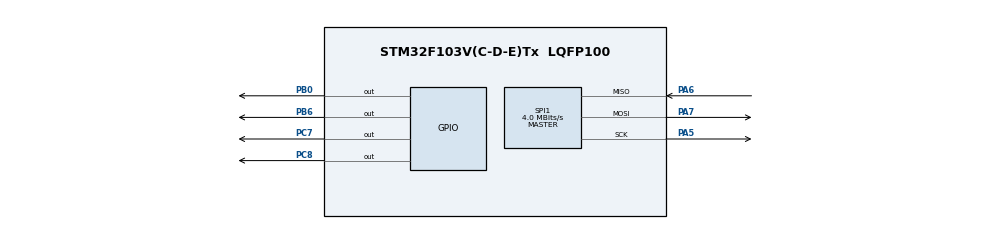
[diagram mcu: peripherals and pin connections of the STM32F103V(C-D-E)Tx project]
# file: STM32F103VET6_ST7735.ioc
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Mcu.Family=STM32F1
Mcu.Name=STM32F103V(C-D-E)Tx
Mcu.Package=LQFP100
NVIC.PriorityGroup=NVIC_PRIORITYGROUP_4
PA13.Mode=Serial_Wire
PA13.Signal=SYS_JTMS-SWDIO
PA14.Mode=Serial_Wire
PA14.Signal=SYS_JTCK-SWCLK
PA5.Mode=Full_Duplex_Master
PA5.Signal=SPI1_SCK
PA6.Mode=Full_Duplex_Master
PA6.Signal=SPI1_MISO
PA7.Mode=Full_Duplex_Master
PA7.Signal=SPI1_MOSI
PB0.PinState=GPIO_PIN_SET
PB0.Signal=GPIO_Output
PB6.Signal=GPIO_Output
PC7.Signal=GPIO_Output
PC8.Signal=GPIO_Output
ProjectManager.HeapSize=0x200
ProjectManager.StackSize=0x400
ProjectManager.TargetToolchain=STM32CubeIDE
RCC.APB1Freq_Value=8000000
RCC.APB2Freq_Value=8000000
SPI1.CalculateBaudRate=4.0 MBits/s
SPI1.Direction=SPI_DIRECTION_2LINES
SPI1.Mode=SPI_MODE_MASTER
SPI1.VirtualType=VM_MASTER
board=custom

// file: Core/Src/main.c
/* USER CODE BEGIN Header */
/**
  ******************************************************************************
  * @file           : main.c
  * @brief          : Main program body
  ******************************************************************************
  * @attention
  *
  * Copyright (c) 2024 STMicroelectronics.
  * All rights reserved.
  *
  * This software is licensed under terms that can be found in the LICENSE file
  * in the root directory of this software component.
  * If no LICENSE file comes with this software, it is provided AS-IS.
  *
  ******************************************************************************
  */
/* USER CODE END Header */
#include "main.h"
#include "spi.h"
#include "gpio.h"

/* USER CODE BEGIN Includes */
#include "ST7735.h"
#include "fonts.h"
#include "GFX_FUNCTIONS.h"
/* USER CODE END Includes */

/* USER CODE BEGIN PD */
const uint16_t _acBrandenburg_gate_cropped_high[] = {
		  0xA2, 0xA2, 0xA2, 0xA2, 0xA2, 0xA2, 0xA2, 0xA2, 0xA2, 0xA2, 0xA2, 0xA2, 0xA2, 0xA2, 0xA2, 0xA2, 0xA8, 0xA8, 0xA8, 0xA8, 0xA8, 0xA8, 0xA8, 0xA8, 0xA8, 0xA8, 0xA8, 0xA8, 0xA8, 0xA8, 0xA8, 0xA8, 0xA8, 0xA8, 0xA8, 0xA2, 0xA2, 0xA2, 0xA8, 0xA8, 0xA8, 0xA8,
		        0xA8, 0xA8, 0xA8, 0xA8, 0xA8, 0xA8, 0xA8, 0xA8, 0xA8, 0xA8, 0xA8, 0xA8, 0xA8, 0xCC, 0xCC, 0xCC, 0xCC, 0xCC, 0xCC, 0xCC, 0xCC, 0xCC, 0xCC, 0xCD, 0xCD, 0xCD, 0xCD, 0xCD, 0xCD, 0xCD, 0xCD, 0xCC, 0xCC, 0xCC, 0xCC, 0xCC, 0xCC, 0xCC, 0xCC, 0xCC, 0xCC,
		        0xCC, 0xCC, 0xCC, 0xCC, 0xCC, 0xCC, 0xCC, 0xCC, 0xCC, 0xCC, 0xCC, 0xCC, 0xCC, 0xCC, 0xA8, 0xA8, 0xA8, 0xA8, 0xA8, 0xA8, 0xA8, 0xA8, 0xA8, 0xA8, 0xA8, 0xA8, 0xA8, 0xA8, 0xA8, 0xA8, 0xA8, 0xA8, 0xA8, 0xA8, 0xA8, 0xA8, 0xA8,
		  0xA2, 0xA2, 0xA2, 0xA2, 0xA2, 0xA2, 0xA2, 0xA2, 0xA2, 0xA2, 0xA2, 0xA2, 0xA2, 0xA2, 0xA2, 0xA2, 0xA2, 0xA2, 0xA8, 0xA8, 0xA8, 0xA8, 0xA8, 0xA8, 0xA8, 0xA8, 0xA8, 0xA8, 0xA8, 0xA8, 0xA8, 0xA8, 0xA8, 0xA8, 0xA8, 0xA2, 0xA2, 0xA2, 0xA2, 0xA8, 0xA8, 0xA8,
		        0xA8, 0xA8, 0xA8, 0xA8, 0xA8, 0xA8, 0xA8, 0xA8, 0xA8, 0xA8, 0xA8, 0xA8, 0xA8, 0xA8, 0xA8, 0xCC, 0xCC, 0xCC, 0xCC, 0xCC, 0xCC, 0xCC, 0xCC, 0xCC, 0xCC, 0xCD, 0xCD, 0xCD, 0xCD, 0xCD, 0xCD, 0xCD, 0xCD, 0xCC, 0xCC, 0xCC, 0xCC, 0xCC, 0xCC, 0xCC, 0xCC,
		        0xCC, 0xCC, 0xCC, 0xCC, 0xCC, 0xCC, 0xCC, 0xCC, 0xCC, 0xCC, 0xCC, 0xCC, 0xCC, 0xA8, 0xA8, 0xA8, 0xA8, 0xA8, 0xA8, 0xA8, 0xA8, 0xA8, 0xA8, 0xA8, 0xA8, 0xA8, 0xA8, 0xA8, 0xA8, 0xA8, 0xA8, 0xA8, 0xA8, 0xA8, 0xA8, 0xA8, 0xA8,
		  0xA8, 0xA2, 0xA2, 0xA2, 0xA2, 0xA2, 0xA2, 0xA2, 0xA2, 0xA2, 0xA2, 0xA2, 0xA2, 0xA2, 0xA2, 0xA2, 0xA2, 0xA2, 0xA2, 0xA8, 0xA8, 0xA8, 0xA8, 0xA8, 0xA8, 0xA8, 0xA8, 0xA8, 0xA8, 0xA8, 0xA8, 0xA8, 0xA8, 0xA8, 0xA8, 0xA2, 0xA2, 0xA2, 0xA2, 0xA2, 0xA8, 0xA8,
		        0xA8, 0xA8, 0xA8, 0xA8, 0xA8, 0xA8, 0xA8, 0xA8, 0xA8, 0xA8, 0xA8, 0xA8, 0xCC, 0xCC, 0xCC, 0xCC, 0xCC, 0xCC, 0xCC, 0xCC, 0xCC, 0xCC, 0xCC, 0xCC, 0xCC, 0xCC, 0xCC, 0xCD, 0xCD, 0xCD, 0xCD, 0xCD, 0xCD, 0xCC, 0xCC, 0xCC, 0xCC, 0xCC, 0xCC, 0xCC, 0xCC,
		        0xCC, 0xCC, 0xCC, 0xCC, 0xCC, 0xCC, 0xCC, 0xCC, 0xCC, 0xCC, 0xCC, 0xCC, 0xCC, 0xA8, 0xA8, 0xA8, 0xA8, 0xA8, 0xA8, 0xA8, 0xA8, 0xA8, 0xA8, 0xA8, 0xA8, 0xA8, 0xA8, 0xA8, 0xA8, 0xA8, 0xA8, 0xA8, 0xA8, 0xA8, 0xA8, 0xA8, 0xA8,
		  0xA8, 0xA2, 0xA2, 0xA2, 0xA2, 0xA2, 0xA2, 0xA2, 0xA2, 0xA2, 0xA2, 0xA2, 0xA2, 0xA2, 0xA2, 0xA2, 0xA2, 0xA2, 0xA2, 0xA8, 0xA8, 0xA8, 0xA8, 0xA8, 0xA8, 0xA8, 0xA8, 0xA8, 0xA8, 0xA8, 0xA8, 0xA8, 0xA8, 0xA8, 0xA8, 0xA8, 0xA8, 0xA8, 0xA2, 0xA2, 0xA8, 0xA8,
		        0xA8, 0xA8, 0xA8, 0xA8, 0xA8, 0xA8, 0xA8, 0xA8, 0xA8, 0xA8, 0xA8, 0xCC, 0xCC, 0xCC, 0xCC, 0xA8, 0xA8, 0xCC, 0xCC, 0xCC, 0xCC, 0xCC, 0xCC, 0xCC, 0xCC, 0xCC, 0xCC, 0xCC, 0xCD, 0xCD, 0xCD, 0xCD, 0xCD, 0xCD, 0xCD, 0xCC, 0xCC, 0xCC, 0xCC, 0xCC, 0xCC,
		        0xCC, 0xCC, 0xCC, 0xCC, 0xCC, 0xCC, 0xCC, 0xCC, 0xCC, 0xCC, 0xCC, 0xCC, 0xCC, 0xA8, 0xA8, 0xA8, 0xA8, 0xA8, 0xA8, 0xA8, 0xA8, 0xA8, 0xA8, 0xA8, 0xA8, 0xA8, 0xA8, 0xA8, 0xA8, 0xA8, 0xA8, 0xA8, 0xA8, 0xA8, 0xA8, 0xA8, 0xA8,
		  0xA8, 0xA8, 0xA2, 0xA2, 0xA2, 0xA2, 0xA2, 0xA2, 0xA2, 0xA2, 0xA2, 0xA2, 0xA2, 0xA2, 0xA2, 0xA2, 0xA2, 0xA2, 0xA2, 0xA2, 0xA8, 0xA8, 0xA8, 0xA8, 0xA8, 0xA8, 0xA8, 0xA8, 0xA8, 0xA8, 0xA8, 0xA8, 0xA8, 0xA8, 0xA8, 0xA8, 0xA8, 0xA8, 0xA2, 0xA8, 0xA8, 0xA8,
		        0xA8, 0xA8, 0xA8, 0xA8, 0xA8, 0xA8, 0xA8, 0xA8, 0xA8, 0xA8, 0xCC, 0xCC, 0xCC, 0xCC, 0xCC, 0xCC, 0xCC, 0xCC, 0xCC, 0xCC, 0xCC, 0xCC, 0xCC, 0xCC, 0xCC, 0xCC, 0xCC, 0xCC, 0xCC, 0xCC, 0xCD, 0xCD, 0xCD, 0xCD, 0xCD, 0xCD, 0xCD, 0xCC, 0xCC, 0xCC, 0xCC,
		        0xCC, 0xCC, 0xCC, 0xCC, 0xCC, 0xCC, 0xCC, 0xCC, 0xCC, 0xCC, 0xCC, 0xCC, 0xCC, 0xA8, 0xA8, 0xA8, 0xA8, 0xA8, 0xA8, 0xA8, 0xA8, 0xA8, 0xA8, 0xA8, 0xA8, 0xA8, 0xA8, 0xA8, 0xA8, 0xA8, 0xA8, 0xA8, 0xA8, 0xA8, 0xA8, 0xA8, 0xA8,
		  0xA8, 0xA8, 0xA8, 0xA2, 0xA2, 0xA2, 0xA2, 0xA2, 0xA2, 0xA2, 0xA2, 0xA2, 0xA2, 0xA2, 0xA2, 0xA2, 0xA2, 0xA2, 0xA2, 0xA2, 0xA8, 0xA8, 0xA8, 0xA8, 0xA8, 0xA8, 0xA8, 0xA8, 0xA8, 0xA8, 0xA8, 0xA8, 0xA8, 0xA8, 0xA8, 0xA8, 0xA8, 0xA8, 0xA8, 0xA8, 0xA8, 0xA8,
		        0xA8, 0xA8, 0xA8, 0xA8, 0xA8, 0xA8, 0xA8, 0xA8, 0xA8, 0xA8, 0xCC, 0xCC, 0xCC, 0xCC, 0xCC, 0xCC, 0xCC, 0xCC, 0xCC, 0xCC, 0xCC, 0xCC, 0xCC, 0xCC, 0xCC, 0xCC, 0xCC, 0xCC, 0xCC, 0xCC, 0xCD, 0xCD, 0xCD, 0xCD, 0xCD, 0xCD, 0xCD, 0xCD, 0xCD, 0xCC, 0xCC,
		        0xCC, 0xCC, 0xCC, 0xCC, 0xCC, 0xCC, 0xCC, 0xCC, 0xCC, 0xCC, 0xCC, 0xCC, 0xA8, 0xA8, 0xA8, 0xA8, 0xA8, 0xA8, 0xA8, 0xA8, 0xA8, 0xA8, 0xA8, 0xA8, 0xA8, 0xA8, 0xA8, 0xA8, 0xA8, 0xA8, 0xA8, 0xA8, 0xA8, 0xA8, 0xA8, 0xA8, 0xA8,
		  0xA8, 0xA8, 0xA8, 0xA2, 0xA2, 0xA2, 0xA2, 0xA2, 0xA2, 0xA2, 0xA2, 0xA2, 0xA2, 0xA2, 0xA2, 0xA2, 0xA2, 0xA2, 0xA2, 0xA2, 0xA2, 0xA8, 0xA8, 0xA8, 0xA8, 0xA8, 0xA8, 0xA8, 0xA8, 0xA8, 0xA8, 0xA8, 0xA8, 0xA8, 0xA8, 0xA8, 0xA8, 0xA8, 0xA8, 0xA8, 0xA8, 0xA8,
		        0xA8, 0xA8, 0xA8, 0xA8, 0xA8, 0xA8, 0xA8, 0xA8, 0xA8, 0xA8, 0xCC, 0xCC, 0xCC, 0xCC, 0xCC, 0xCC, 0xCC, 0xCC, 0xCC, 0xCC, 0xCC, 0xCC, 0xCC, 0xCC, 0xCC, 0xCC, 0xCC, 0xCC, 0xCC, 0xCC, 0xCC, 0xCC, 0xCD, 0xCD, 0xCD, 0xCD, 0xCD, 0xCD, 0xCD, 0xCD, 0xCC,
		        0xCC, 0xCC, 0xCC, 0xCC, 0xCC, 0xCC, 0xCC, 0xCC, 0xCC, 0xCC, 0xCC, 0xCC, 0xA8, 0xA8, 0xA8, 0xA8, 0xA8, 0xA8, 0xA8, 0xA8, 0xA8, 0xA8, 0xA8, 0xA8, 0xA8, 0xA8, 0xA8, 0xA8, 0xA8, 0xA8, 0xA8, 0xA8, 0xA8, 0xA8, 0xA8, 0xA8, 0xA8,
		  0xA8, 0xA8, 0xA8, 0xA2, 0xA2, 0xA2, 0xA2, 0xA2, 0xA2, 0xA2, 0xA2, 0xA2, 0xA2, 0xA2, 0xA2, 0xA2, 0xA2, 0xA2, 0xA2, 0xA2, 0xA8, 0xA8, 0xA8, 0xA8, 0xA8, 0xA8, 0xA8, 0xA8, 0xA8, 0xA8, 0xA8, 0xA8, 0xA8, 0xA8, 0xA8, 0xA8, 0xA8, 0xA8, 0xA8, 0xA8, 0xA8, 0xA8,
		        0xA8, 0xA8, 0xA8, 0xA8, 0xA8, 0xA8, 0xA8, 0xA8, 0xA8, 0xCC, 0xCC, 0xCC, 0xCC, 0xCC, 0xCC, 0xCC, 0xCC, 0xCC, 0xCC, 0xCC, 0xCC, 0xCC, 0xCC, 0xCC, 0xCC, 0xCC, 0xCC, 0xCC, 0xCC, 0xCC, 0xCC, 0xCC, 0xCD, 0xCD, 0xCD, 0xCD, 0xCD, 0xCD, 0xCD, 0xCD, 0xCC,
		        0xCC, 0xCC, 0xCC, 0xCC, 0xCC, 0xCC, 0xCC, 0xCC, 0xCC, 0xCC, 0xCC, 0xCC, 0xA8, 0xA8, 0xA8, 0xA8, 0xA8, 0xA8, 0xA8, 0xA8, 0xA8, 0xA8, 0xA8, 0xA8, 0xA8, 0xA8, 0xA8, 0xA8, 0xA8, 0xA8, 0xA8, 0xA8, 0xA8, 0xA8, 0xA8, 0xA8, 0xA8,
		  0xA8, 0xA8, 0xA8, 0xA2, 0xA2, 0xA2, 0xA2, 0xA2, 0xA2, 0xA2, 0xA2, 0xA2, 0xA2, 0xA2, 0xA2, 0xA2, 0xA2, 0xA2, 0xA2, 0xA2, 0xA8, 0xA8, 0xA8, 0xA8, 0xA8, 0xA8, 0xA8, 0xA8, 0xA8, 0xA8, 0xA8, 0xA8, 0xA8, 0xA8, 0xA8, 0xA8, 0xA8, 0xA8, 0xA8, 0xA8, 0xA8, 0xA8,
		        0xA8, 0xA8, 0xA8, 0xA8, 0xA8, 0xA8, 0xA8, 0xA8, 0xA8, 0xA8, 0xA8, 0xCC, 0xCC, 0xCC, 0xCC, 0xCC, 0xCC, 0xCC, 0xCC, 0xCC, 0xCC, 0xCC, 0xCC, 0xCC, 0xCC, 0xCC, 0xCC, 0xCC, 0xCC, 0xCC, 0xCC, 0xCC, 0xCD, 0xCC, 0xCD, 0xCD, 0xCD, 0xCD, 0xCD, 0xCD, 0xCD,
		        0xCD, 0xCC, 0xCC, 0xCD, 0xCC, 0xCC, 0xCC, 0xCC, 0xCC, 0xCC, 0xCC, 0xA8, 0xA8, 0xA8, 0xA8, 0xA8, 0xA8, 0xA8, 0xA8, 0xA8, 0xA8, 0xA8, 0xA8, 0xA8, 0xA8, 0xA8, 0xA8, 0xA8, 0xA8, 0xA8, 0xA8, 0xA8, 0xA8, 0xA8, 0xA8, 0xA8, 0xA8,
		  0xA8, 0xA8, 0xA8, 0xA8, 0xA2, 0xA2, 0xA2, 0xA2, 0xA2, 0xA2, 0xA2, 0xA2, 0xA2, 0xA2, 0xA2, 0xA2, 0xA2, 0xA2, 0xA2, 0xA8, 0xA8, 0xA8, 0xA8, 0xA8, 0xA8, 0xA8, 0xA8, 0xA8, 0xA8, 0xA8, 0xA8, 0xA8, 0xA8, 0xA8, 0xA8, 0xA8, 0xA8, 0xA8, 0xA8, 0xA8, 0xA8, 0xA8,
		        0xA8, 0xA8, 0xA8, 0xA8, 0xA8, 0xA8, 0xA8, 0xA8, 0xA8, 0xA8, 0xA8, 0xCC, 0xCC, 0xCC, 0xCC, 0xCC, 0xCC, 0xCC, 0xCC, 0xCC, 0xCC, 0xCC, 0xCC, 0xCC, 0xCC, 0xCC, 0xCC, 0xCC, 0xCC, 0xCC, 0xCC, 0xCC, 0xCC, 0xCD, 0xCD, 0xCD, 0xCD, 0xCD, 0xCD, 0xCD, 0xCD,
		        0xCD, 0xCD, 0xCD, 0xCD, 0xCC, 0xCC, 0xCC, 0xCC, 0xCC, 0xCC, 0xCC, 0xA8, 0xA8, 0xA8, 0xA8, 0xA8, 0xA8, 0xA8, 0xA8, 0xA8, 0xA8, 0xA8, 0xA8, 0xA8, 0xA8, 0xA8, 0xA8, 0xA8, 0xA8, 0xA8, 0xA8, 0xA8, 0xA8, 0xA8, 0xA8, 0xA8, 0xA8,
		  0xA8, 0xA8, 0xA8, 0xA8, 0xA2, 0xA2, 0xA2, 0xA2, 0xA2, 0xA2, 0xA2, 0xA2, 0xA2, 0xA2, 0xA2, 0xA2, 0xA2, 0xA2, 0xA8, 0xA8, 0xA8, 0xA8, 0xA8, 0xA8, 0xA8, 0xA8, 0xA8, 0xA8, 0xA8, 0xA8, 0xA8, 0xA8, 0xA8, 0xA8, 0xA8, 0xA8, 0xA8, 0xA8, 0xA8, 0xA8, 0xA8, 0xA8,
		        0xA8, 0xA8, 0xA8, 0xA8, 0xA8, 0xA8, 0xA8, 0xA8, 0xCC, 0xCC, 0xCC, 0xCC, 0xCC, 0xCC, 0xCC, 0xCC, 0xCC, 0xCC, 0xCC, 0xCC, 0xCC, 0xCC, 0xCC, 0xCC, 0xCC, 0xCC, 0xCC, 0xCC, 0xCC, 0xCC, 0xCC, 0xCC, 0xCC, 0xCD, 0xCD, 0xCD, 0xCD, 0xCD, 0xCD, 0xCD, 0xCD,
		        0xCD, 0xCD, 0xCD, 0xCD, 0xCC, 0xCC, 0xCC, 0xCC, 0xCC, 0xCC, 0xA8, 0xA8, 0xA8, 0xA8, 0xA8, 0xA8, 0xA8, 0xA8, 0xA8, 0xA8, 0xA8, 0xA8, 0xA8, 0xA8, 0xA8, 0xA8, 0xA8, 0xA8, 0xA8, 0xA8, 0xA8, 0xA8, 0xA8, 0xA8, 0xA8, 0xA8, 0xA8,
		  0xA8, 0xA8, 0xA8, 0xA8, 0xA8, 0xA8, 0xA2, 0xA2, 0xA2, 0xA2, 0xA2, 0xA2, 0xA2, 0xA2, 0xA2, 0xA2, 0xA2, 0xA8, 0xA8, 0xA8, 0xA8, 0xA8, 0xA8, 0xA8, 0xA8, 0xA8, 0xA8, 0xA8, 0xA8, 0xA8, 0xA8, 0xA8, 0xA8, 0xA8, 0xA8, 0xA8, 0xA8, 0xA8, 0xA8, 0xA8, 0xA8, 0xA8,
		        0xA8, 0xA8, 0xA8, 0xA8, 0xA8, 0xA8, 0xA8, 0xA8, 0xCC, 0xCC, 0xCC, 0xCC, 0xCC, 0xCC, 0xCC, 0xCC, 0xCC, 0xCC, 0xCC, 0xCC, 0xCC, 0xCC, 0xCC, 0xCC, 0xCC, 0xCC, 0xCC, 0xCC, 0xCC, 0xCC, 0xCC, 0xCC, 0xCC, 0xCD, 0xCD, 0xCD, 0xCD, 0xCD, 0xCD, 0xCD, 0xCD,
		        0xCD, 0xCD, 0xCD, 0xCD, 0xCD, 0xCC, 0xCC, 0xCC, 0xCC, 0xCC, 0xA8, 0xA8, 0xA8, 0xA8, 0xA8, 0xCC, 0xA8, 0xA8, 0xA8, 0xA8, 0xA8, 0xA8, 0xA8, 0xA8, 0xA8, 0xA8, 0xA8, 0xA8, 0xA8, 0xA8, 0xA8, 0xA8, 0xA8, 0xA8, 0xA8, 0xA8, 0xA8,
		  0xA8, 0xA8, 0xA8, 0xA8, 0xA8, 0xA8, 0xA2, 0xA2, 0xA2, 0xA2, 0xA2, 0xA2, 0xA2, 0xA2, 0xA2, 0xA2, 0xA2, 0xA8, 0xA8, 0xA8, 0xA8, 0xA8, 0xA8, 0xA8, 0xA8, 0xA8, 0xA8, 0xA8, 0xA8, 0xA8, 0xA8, 0xA8, 0xA8, 0xA8, 0xA8, 0xA8, 0xA8, 0xA8, 0xA8, 0xA8, 0xA8, 0xA8,
		        0xA8, 0xA8, 0xA8, 0xA8, 0xA8, 0xA8, 0xA8, 0xA8, 0xCC, 0xCC, 0xCC, 0xCC, 0xCC, 0xCC, 0xCC, 0xCC, 0xCC, 0xCC, 0xCC, 0xCC, 0xCC, 0xCC, 0xCC, 0xCC, 0xCC, 0xCC, 0xCC, 0xCC, 0xCC, 0xCC, 0xCC, 0xCC, 0xCC, 0xCC, 0xCD, 0xCD, 0xCD, 0xCD, 0xCD, 0xCD, 0xCD,
		        0xCD, 0xCD, 0xCD, 0xCD, 0xCD, 0xCD, 0xCC, 0xCC, 0xCC, 0xCC, 0xA8, 0xA8, 0xA8, 0xA8, 0xA8, 0xCC, 0xA8, 0xA8, 0xA8, 0xA8, 0xA8, 0xA8, 0xA8, 0xA8, 0xA8, 0xA8, 0xA8, 0xA8, 0xA8, 0xA8, 0xA8, 0xA8, 0xA8, 0xA8, 0xA8, 0xA8, 0xA8,
		  0xA8, 0xA8, 0xA8, 0xA8, 0xA8, 0xA8, 0xA8, 0xA2, 0xA2, 0xA2, 0xA2, 0xA2, 0xA2, 0xA2, 0xA2, 0xA2, 0xA8, 0xA8, 0xA8, 0xA8, 0xA8, 0xA8, 0xA8, 0xA8, 0xA8, 0xA8, 0xA8, 0xA8, 0xA8, 0xA8, 0xA8, 0xA8, 0xA8, 0xA8, 0xA8, 0xA8, 0xA8, 0xA8, 0xA8, 0xA8, 0xA8, 0xA8,
		        0xA8, 0xA8, 0xA8, 0xA8, 0xA8, 0xA8, 0xA8, 0xA8, 0xA8, 0xCC, 0xCC, 0xCC, 0xCC, 0xCC, 0xCC, 0xCC, 0xCC, 0xCC, 0xCC, 0xCC, 0xCC, 0xCC, 0xCC, 0xCC, 0xCC, 0xCC, 0xCC, 0xCC, 0xCC, 0xCC, 0xCC, 0xCC, 0xCC, 0xCC, 0xCD, 0xCD, 0xCD, 0xCD, 0xCD, 0xCD, 0xCD,
		        0xCD, 0xCD, 0xCD, 0xCD, 0xCD, 0xCD, 0xCC, 0xCC, 0xCC, 0xCC, 0xA8, 0xA8, 0xA8, 0xA8, 0xA8, 0xCC, 0xCC, 0xA8, 0xA8, 0xA8, 0xA8, 0xA8, 0xA8, 0xA8, 0xA8, 0xA8, 0xA8, 0xA8, 0xA8, 0xA8, 0xA8, 0xA8, 0xA8, 0xA8, 0xA8, 0xA8, 0xA8,
		  0xA8, 0xA8, 0xA8, 0xA8, 0xA8, 0xA8, 0xA8, 0xA8, 0xA2, 0xA8, 0xA8, 0xA2, 0xA2, 0xA2, 0xA2, 0xA2, 0xA2, 0xA8, 0xA8, 0xA8, 0xA8, 0xA8, 0xA8, 0xA8, 0xA8, 0xA8, 0xA8, 0xA8, 0xA8, 0xA8, 0xA8, 0xA8, 0xA8, 0xA8, 0xA8, 0xA8, 0xA8, 0xA8, 0xA8, 0xA8, 0xA8, 0xA8,
		        0xA8, 0xA8, 0xA8, 0xA8, 0xA8, 0xA8, 0xA8, 0xA8, 0xA8, 0xCC, 0xCC, 0xCC, 0xCC, 0xCC, 0xCC, 0xCC, 0xCC, 0xCC, 0xCC, 0xCC, 0xCC, 0xCC, 0xCC, 0xCC, 0xCC, 0xCC, 0xCC, 0xCC, 0xCC, 0xCC, 0xCC, 0xCC, 0xCC, 0xCC, 0xCC, 0xCD, 0xCD, 0xCD, 0xCD, 0xCD, 0xCD,
		        0xCD, 0xCD, 0xCD, 0xCD, 0xCD, 0xCD, 0xCD, 0xCC, 0xCC, 0xA8, 0xA8, 0xCC, 0xA8, 0xA8, 0xA8, 0xA8, 0xA8, 0xA8, 0xA8, 0xA8, 0xA8, 0xA8, 0xA8, 0xA8, 0xA8, 0xA8, 0xA8, 0xA8, 0xA8, 0xA8, 0xA8, 0xA8, 0xA8, 0xA8, 0xA8, 0xA8, 0xA8,
		  0xA8, 0xA8, 0xA8, 0xA8, 0xA8, 0xA8, 0xA8, 0xA2, 0xA2, 0xA2, 0xA8, 0xA2, 0xA2, 0xA2, 0xA2, 0xA2, 0xA2, 0xA8, 0xA8, 0xA8, 0xA8, 0xA8, 0xA8, 0xA8, 0xA8, 0xA8, 0xA8, 0xA8, 0xA8, 0xA8, 0xA8, 0xA8, 0xA8, 0xA8, 0xA8, 0xA8, 0xA8, 0xA8, 0xA8, 0xA8, 0xA8, 0xA8,
		        0xA8, 0xA8, 0xA8, 0xA8, 0xA8, 0xA8, 0xA8, 0xA8, 0xA8, 0xCC, 0xCC, 0xCC, 0xCC, 0xCC, 0xCC, 0xCC, 0xCC, 0xCC, 0xCC, 0xCC, 0xCC, 0xCC, 0xCC, 0xCC, 0xCC, 0xCC, 0xCC, 0xCC, 0xCC, 0xCC, 0xCC, 0xCC, 0xCC, 0xCC, 0xCC, 0xCC, 0xCD, 0xCD, 0xCD, 0xCD, 0xCD,
		        0xCD, 0xCD, 0xCD, 0xCD, 0xCD, 0xCD, 0xCD, 0xCD, 0xCC, 0xCC, 0xCC, 0xCC, 0xA8, 0xA8, 0xA8, 0xA8, 0xA8, 0xA8, 0xA8, 0xA8, 0xA8, 0xA8, 0xA8, 0xA8, 0xA8, 0xA8, 0xA8, 0xA8, 0xA8, 0xA8, 0xA8, 0xA8, 0xA8, 0xA8, 0xA8, 0xA8, 0xA8,
		  0xA8, 0xA8, 0xA8, 0xA8, 0xA8, 0xA8, 0xA8, 0xA8, 0xA8, 0xA8, 0xA8, 0xA8, 0xA8, 0xA8, 0xA8, 0xA8, 0xA8, 0xA8, 0xA8, 0xA8, 0xA8, 0xA8, 0xA8, 0xA8, 0xA8, 0xA8, 0xA8, 0xA8, 0xA8, 0xA8, 0xA8, 0xA8, 0xA8, 0xA8, 0xA8, 0xA8, 0xA8, 0xA8, 0xA8, 0xA8, 0xA8, 0xA8,
		        0xA8, 0xA8, 0xA8, 0xA8, 0xA8, 0xA8, 0xA8, 0xA8, 0xA8, 0xA8, 0xCC, 0xCC, 0xCC, 0xCC, 0xCC, 0xCC, 0xCC, 0xCC, 0xCC, 0xCC, 0xCC, 0xCC, 0xCC, 0xCC, 0xCC, 0xCC, 0xCC, 0xCD, 0xCD, 0xCD, 0xCC, 0xCC, 0xCC, 0xCC, 0xCC, 0xCC, 0xCD, 0xCD, 0xCD, 0xCD, 0xCD,
		        0xCD, 0xCD, 0xCD, 0xCD, 0xCD, 0xCD, 0xCD, 0xCD, 0xCC, 0xCC, 0xA8, 0xA8, 0xA8, 0xA8, 0xA8, 0xA8, 0xA8, 0xA8, 0xA8, 0xA8, 0xA8, 0xA8, 0xA8, 0xA8, 0xA8, 0xA8, 0xA8, 0xA8, 0xA8, 0xA8, 0xA8, 0xA8, 0xA8, 0xA8, 0xA8, 0xA8, 0xA8,
		  0xA8, 0xA8, 0xA8, 0xA8, 0xA8, 0xA8, 0xA8, 0xA8, 0xA8, 0xA8, 0xA8, 0xA8, 0xA8, 0xA8, 0xA8, 0xA8, 0xA8, 0xA8, 0xA8, 0xA8, 0xA8, 0xA8, 0xA8, 0xA8, 0xA8, 0xA8, 0xA8, 0xA8, 0xA8, 0xA8, 0xA8, 0xA8, 0xA8, 0xA8, 0xA8, 0xA8, 0xA8, 0xA8, 0xA8, 0xA8, 0xA8, 0xA8,
		        0xA8, 0xA8, 0xA8, 0xA8, 0xA8, 0xA8, 0xA8, 0xA8, 0xA8, 0xA8, 0xA8, 0xCC, 0xCC, 0xCC, 0xCC, 0xCC, 0xCC, 0xCC, 0xCC, 0xCC, 0xCC, 0xCC, 0xCC, 0xCC, 0xCC, 0xCC, 0xCC, 0xCC, 0xCD, 0xCD, 0xCD, 0xCC, 0xCC, 0xCC, 0xCC, 0xCC, 0xCD, 0xCD, 0xCD, 0xCD, 0xCD,
		        0xCD, 0xCD, 0xCD, 0xCD, 0xCD, 0xCD, 0xCD, 0xCD, 0xCD, 0xCD, 0xCC, 0xA8, 0xA8, 0xA8, 0xA8, 0xA8, 0xA8, 0xA8, 0xA8, 0xA8, 0xA8, 0xA8, 0xA8, 0xA8, 0xA8, 0xA8, 0xA8, 0xA8, 0xA8, 0xA8, 0xA8, 0xA8, 0xA8, 0xA8, 0xA8, 0xA8, 0xA8,
		  0xCC, 0xA8, 0xA8, 0xA8, 0xA8, 0xA8, 0xA8, 0xA8, 0xA8, 0xA8, 0xA8, 0xA8, 0xA8, 0xA8, 0xA8, 0xA8, 0xA8, 0xA8, 0xA8, 0xA8, 0xA8, 0xA8, 0xA8, 0xA8, 0xA8, 0xA8, 0xA8, 0xA8, 0xA8, 0xA8, 0xA8, 0xA8, 0xA8, 0xA8, 0xA8, 0xA8, 0xA8, 0xA8, 0xA8, 0xA8, 0xA8, 0xA8,
		        0xA8, 0xA8, 0xA8, 0xA8, 0xA8, 0xA8, 0xA8, 0xA8, 0xA8, 0xA8, 0xA8, 0xCC, 0xCC, 0xCC, 0xCC, 0xCC, 0xCC, 0xCC, 0xCC, 0xCC, 0xCC, 0xCC, 0xCC, 0xCC, 0xCC, 0xCC, 0xCC, 0xCC, 0xCD, 0xCD, 0xCD, 0xCD, 0xCC, 0xCC, 0xCD, 0xCD, 0xCD, 0xCD, 0xCD, 0xCD, 0xCD,
		        0xCD, 0xCD, 0xCD, 0xCD, 0xCD, 0xCD, 0xCD, 0xCD, 0xCD, 0xCD, 0xCD, 0xCC, 0xA8, 0xA8, 0xA8, 0xCC, 0xCC, 0xA8, 0xA8, 0xA8, 0xA8, 0xA8, 0xA8, 0xA8, 0xA8, 0xA8, 0xA8, 0xA8, 0xA8, 0xA8, 0xA8, 0xA8, 0xA8, 0xA8, 0xA8, 0xA8, 0xA8,
		  0xA8, 0xA8, 0xA8, 0xA8, 0xA8, 0xA8, 0xA8, 0xA8, 0xA8, 0xA8, 0xA8, 0xA8, 0xA8, 0xA8, 0xA8, 0xA8, 0xA8, 0xA8, 0xA8, 0xA8, 0xA8, 0xA8, 0xA8, 0xA8, 0xA8, 0xA8, 0xA8, 0xA8, 0xA8, 0xA8, 0xA8, 0xA8, 0xA8, 0xA8, 0xA8, 0xA8, 0xA8, 0xA8, 0xA8, 0xA8, 0xA8, 0xA8,
		        0xA8, 0xA8, 0xA8, 0xA8, 0xA8, 0xA8, 0xA8, 0xA8, 0xA8, 0xA8, 0xA8, 0xCC, 0xCC, 0xCC, 0xCC, 0xCC, 0xCC, 0xCC, 0xCC, 0xCC, 0xCC, 0xCC, 0xCC, 0xCC, 0xCC, 0xCC, 0xCC, 0xCC, 0xCD, 0xCD, 0xCD, 0xCD, 0xCD, 0xCD, 0xCD, 0xCD, 0xCD, 0xCD, 0xCD, 0xCD, 0xCD,
		        0xCD, 0xCD, 0xCD, 0xCD, 0xCD, 0xCD, 0xCD, 0xCD, 0xCC, 0xCC, 0xCC, 0xCC, 0xCC, 0xA8, 0xA8, 0xCC, 0xCC, 0xCC, 0xA8, 0xA8, 0xA8, 0xA8, 0xA8, 0xA8, 0xA8, 0xA8, 0xA8, 0xA8, 0xA8, 0xA8, 0xA8, 0xA8, 0xA8, 0xA8, 0xA8, 0xA8, 0xA8,
		  0xCC, 0xA8, 0xA8, 0xA8, 0xA8, 0xA8, 0xA8, 0xA8, 0xA8, 0xA8, 0xA8, 0xA8, 0xA8, 0xA8, 0xA8, 0xA8, 0xA8, 0xA8, 0xA8, 0xA8, 0xA8, 0xA8, 0xA8, 0xA8, 0xA8, 0xA8, 0xA8, 0xA8, 0xA8, 0xA8, 0xA8, 0xA8, 0xA8, 0xA8, 0xA8, 0xA8, 0xA8, 0xA8, 0xA8, 0xA8, 0xA8, 0xA8,
		        0xA8, 0xA8, 0xA8, 0xA8, 0xA8, 0xA8, 0xA8, 0xA8, 0xA8, 0xA8, 0xA8, 0xA8, 0xCC, 0xCC, 0xCC, 0xCC, 0xCC, 0xCC, 0xCC, 0xCC, 0xCC, 0xCC, 0xCC, 0xCC, 0xCC, 0xCC, 0xCC, 0xCD, 0xCD, 0xCD, 0xCD, 0xCD, 0xCD, 0xCD, 0xCD, 0xCD, 0xCD, 0xCD, 0xCD, 0xCD, 0xCD,
		        0xCD, 0xCC, 0xCC, 0xCC, 0xCC, 0xCC, 0xCD, 0xCC, 0xCD, 0xCC, 0xCC, 0xCD, 0xCC, 0xCC, 0xCC, 0xCC, 0xCC, 0xCC, 0xA8, 0xA8, 0xA8, 0xA8, 0xA8, 0xA8, 0xA8, 0xA8, 0xA8, 0xA8, 0xA8, 0xA8, 0xA8, 0xA8, 0xA8, 0xA8, 0xA8, 0xA8, 0xA8,
		  0xCC, 0xA8, 0xA8, 0xA8, 0xA8, 0xA8, 0xA8, 0xA8, 0xA8, 0xA8, 0xA8, 0xA8, 0xA8, 0xA8, 0xA8, 0xA8, 0xA8, 0xA8, 0xA8, 0xA8, 0xA8, 0xA8, 0xA8, 0xA8, 0xA8, 0xA8, 0xA8, 0xA8, 0xA8, 0xA8, 0xA8, 0xA8, 0xA8, 0xA8, 0xA8, 0xA8, 0xA8, 0xA8, 0xA8, 0xA8, 0xA8, 0xA8,
		        0xA8, 0xA8, 0xA8, 0xA8, 0xA8, 0xA8, 0xA8, 0xA8, 0xA8, 0xA8, 0xA8, 0xA8, 0xA8, 0xA8, 0xA8, 0xCC, 0xCC, 0xCC, 0xCC, 0xCC, 0xCC, 0xCC, 0xCC, 0xCC, 0xCC, 0xCC, 0xCC, 0xCD, 0xCD, 0xCD, 0xCD, 0xCD, 0xCD, 0xCD, 0xCD, 0xCD, 0xCD, 0xCD, 0xCD, 0xCD, 0xCD,
		        0xCC, 0xCC, 0xCC, 0xCC, 0xCC, 0xCC, 0xCD, 0xCC, 0xCD, 0xCD, 0xCD, 0xCD, 0xCC, 0xCC, 0xCC, 0xCC, 0xCC, 0xCC, 0xA8, 0xA8, 0xA8, 0xCC, 0xA8, 0xA8, 0xA8, 0xA8, 0xA8, 0xA8, 0xA8, 0xA8, 0xA8, 0xA8, 0xA8, 0xA8, 0xA8, 0xA8, 0xA8,
		  0xCC, 0xA8, 0xA8, 0xA8, 0xA8, 0xA8, 0xA8, 0xA8, 0xA8, 0xA8, 0xA8, 0xA8, 0xA8, 0xA8, 0xA8, 0xA8, 0xA8, 0xA8, 0xA8, 0xA8, 0xA8, 0xA8, 0xA8, 0xA8, 0xA8, 0xA8, 0xA8, 0xA8, 0xA8, 0xA8, 0xA8, 0xA8, 0xA8, 0xA8, 0xA8, 0xA8, 0xA8, 0xA8, 0xA8, 0xA8, 0xA8, 0xA8,
		        0xA8, 0xA8, 0xA8, 0xA8, 0xA8, 0xA8, 0xA8, 0xA8, 0xA8, 0xCC, 0xCC, 0xCC, 0xA8, 0xA8, 0xCC, 0xCC, 0xCC, 0xCC, 0xCC, 0xCC, 0xCC, 0xCC, 0xCC, 0xCC, 0xCC, 0xCC, 0xCD, 0xCC, 0xCD, 0xCD, 0xCD, 0xCD, 0xCD, 0xCD, 0xCD, 0xCD, 0xCD, 0xCD, 0xCD, 0xCD, 0xCD,
		        0xCC, 0xCC, 0xCC, 0xCC, 0xCC, 0xCC, 0xCC, 0xCC, 0xCC, 0xCC, 0xCD, 0xCC, 0xCC, 0xCC, 0xCC, 0xCC, 0xCC, 0xCC, 0xCC, 0xCC, 0xA8, 0xA8, 0xA8, 0xA8, 0xA8, 0xA8, 0xA8, 0xA8, 0xA8, 0xA8, 0xA8, 0xA8, 0xA8, 0xA8, 0xA8, 0xA8, 0xA8,
		  0xCC, 0xA8, 0xA8, 0xA8, 0xA8, 0xA8, 0xA8, 0xA8, 0xA8, 0xA8, 0xA8, 0xA8, 0xA8, 0xA8, 0xA8, 0xA8, 0xA8, 0xA8, 0xA8, 0xA8, 0xA8, 0xA8, 0xA8, 0xA8, 0xA8, 0xA8, 0xA8, 0xA8, 0xA8, 0xA8, 0xA8, 0xA8, 0xA8, 0xA8, 0xA8, 0xA8, 0xA8, 0xA8, 0xA8, 0xA8, 0xA8, 0xA8,
		        0xA8, 0xA8, 0xA8, 0xA8, 0xA8, 0xA8, 0xCC, 0xA8, 0xCC, 0xCC, 0xCC, 0xCC, 0xA8, 0xA8, 0xCC, 0xA8, 0xA8, 0xA8, 0xA8, 0xCC, 0xA8, 0xA8, 0xA8, 0xCC, 0xCC, 0xCD, 0xCC, 0xCD, 0xCD, 0xCD, 0xCD, 0xCD, 0xCD, 0xCD, 0xCD, 0xCD, 0xCD, 0xCD, 0xCD, 0xCD, 0xCD,
		        0xCC, 0xCC, 0xCC, 0xCC, 0xCC, 0xCC, 0xCC, 0xCC, 0xCC, 0xCD, 0xCD, 0xCD, 0xCD, 0xCC, 0xCC, 0xCC, 0xCC, 0xA8, 0xCC, 0xCC, 0xA8, 0xA8, 0xA8, 0xA8, 0xCC, 0xCC, 0xA8, 0xA8, 0xA8, 0xA8, 0xA8, 0xA8, 0xA8, 0xA8, 0xA8, 0xA8, 0xCC,
		  0xCC, 0xA8, 0xA8, 0xA8, 0xA8, 0xA8, 0xA8, 0xA8, 0xA8, 0xA8, 0xA8, 0xA8, 0xA8, 0xA8, 0xA8, 0xA8, 0xA8, 0xA8, 0xA8, 0xA8, 0xA8, 0xA8, 0xA8, 0xA8, 0xA8, 0xA8, 0xA8, 0xA8, 0xA8, 0xA8, 0xA8, 0xA8, 0xA8, 0xA8, 0xA8, 0xA8, 0xA8, 0xA8, 0xA8, 0xA8, 0xA8, 0xA8,
		        0xA8, 0xA8, 0xA8, 0xA8, 0xA8, 0xA8, 0xA8, 0xA8, 0xCC, 0xCC, 0xCC, 0xCC, 0xA8, 0xA8, 0xCC, 0xA2, 0x55, 0xA8, 0xA8, 0xA8, 0xA2, 0x2B, 0xA8, 0xCC, 0xCC, 0xCC, 0xCD, 0xCD, 0xCD, 0xCD, 0xCD, 0xCD, 0xCD, 0xCD, 0xCD, 0xCD, 0xCD, 0xCD, 0xCD, 0xCD, 0xCD,
		        0xCC, 0xCC, 0xCC, 0xCC, 0xCC, 0xCC, 0xCC, 0xCC, 0xCC, 0xCC, 0xCD, 0xCD, 0xCD, 0xCD, 0xCC, 0xCC, 0xCC, 0xCC, 0xCC, 0xA8, 0xA8, 0xCC, 0xA8, 0xA8, 0xCC, 0xCC, 0xCC, 0xA8, 0xA8, 0xA8, 0xA8, 0xCC, 0xCC, 0xA8, 0xA8, 0xA8, 0xCC,
		  0xCC, 0xA8, 0xA8, 0xA8, 0xA8, 0xA8, 0xA8, 0xA8, 0xA8, 0xA8, 0xA8, 0xA8, 0xA8, 0xA8, 0xA8, 0xA8, 0xA8, 0xA8, 0xA8, 0xA8, 0xA8, 0xA8, 0xA8, 0xA8, 0xA8, 0xA8, 0xA8, 0xA8, 0xA8, 0xA8, 0xA8, 0xA8, 0xA8, 0xA8, 0xA8, 0xA8, 0xA8, 0xA8, 0xA8, 0xA8, 0xA8, 0xA8,
		        0xA8, 0xA8, 0xA8, 0xA8, 0xA8, 0xA8, 0xCC, 0xCC, 0xCC, 0xCC, 0xCC, 0xCC, 0xCC, 0xA8, 0xCC, 0xA8, 0x2B, 0x2B, 0xA2, 0xA2, 0x00, 0x4F, 0xCC, 0xCC, 0xCC, 0xCC, 0xCD, 0xCD, 0xCD, 0xCD, 0xCD, 0xCD, 0xCD, 0xCD, 0xCD, 0xCD, 0xCD, 0xCD, 0xCD, 0xCD, 0xCC,
		        0xCC, 0xCC, 0xCC, 0xCC, 0xCC, 0xCC, 0xCC, 0xCC, 0xCC, 0xCC, 0xCC, 0xCC, 0xCC, 0xCD, 0xCD, 0xCC, 0xCC, 0xCC, 0xCC, 0xA8, 0xA8, 0xCC, 0xCC, 0xA8, 0xCC, 0xCC, 0xCC, 0xCC, 0xCC, 0xCC, 0xCC, 0xCC, 0xCC, 0xA8, 0xA8, 0xA8, 0xCC,
		  0xCC, 0xA8, 0xA8, 0xA8, 0xA8, 0xA8, 0xA8, 0xA8, 0xA8, 0xA8, 0xA8, 0xA8, 0xA8, 0xA8, 0xA8, 0xA8, 0xA8, 0xA8, 0xA8, 0xA8, 0xA8, 0xA8, 0xA8, 0xA8, 0xA8, 0xA8, 0xA8, 0xA8, 0xA8, 0xA8, 0xA8, 0xA8, 0xA8, 0xA8, 0xA8, 0xA8, 0xA8, 0xA8, 0xA8, 0xA8, 0xA8, 0xA8,
		        0xA8, 0xA8, 0xA8, 0xA8, 0xA8, 0xCC, 0xCC, 0xCC, 0xCC, 0xCC, 0xCC, 0xCC, 0xCC, 0xCC, 0xCC, 0xCC, 0x56, 0x2B, 0x55, 0x2B, 0x2A, 0xA2, 0xCC, 0xCC, 0xCC, 0xCC, 0xCC, 0xCD, 0xCD, 0xCD, 0xCD, 0xCD, 0xCD, 0xCD, 0xCD, 0xCD, 0xCD, 0xCD, 0xCD, 0xCD, 0xCC,
		        0xCC, 0xCC, 0xCC, 0xCC, 0xCC, 0xCC, 0xCC, 0xCC, 0xCC, 0xCC, 0xCC, 0xCC, 0xCD, 0xCD, 0xCD, 0xCC, 0xCC, 0xCC, 0xCC, 0xCC, 0xCC, 0xCC, 0xCC, 0xCC, 0xCC, 0xCC, 0xCC, 0xCC, 0xCC, 0xCC, 0xCC, 0xCC, 0xCC, 0xCC, 0xCC, 0xCC, 0xCC,
		  0xCC, 0xCC, 0xCC, 0xA8, 0xA8, 0xA8, 0xA8, 0xA8, 0xA8, 0xA8, 0xA8, 0xA8, 0xA8, 0xA8, 0xA8, 0xA8, 0xA8, 0xA8, 0xA8, 0xA8, 0xA8, 0xA8, 0xA8, 0xA8, 0xA8, 0xA8, 0xA8, 0xA8, 0xA8, 0xA8, 0xA8, 0xA8, 0xA8, 0xA8, 0xA8, 0xA8, 0xA8, 0xA8, 0xA8, 0xA8, 0xA8, 0xA8,
		        0xA8, 0xA8, 0xA8, 0xA8, 0xA8, 0xCC, 0xCC, 0xCC, 0xCC, 0xCC, 0xCC, 0xCC, 0xCC, 0xCC, 0xCC, 0xCC, 0xCC, 0x56, 0x2B, 0x2B, 0x55, 0xA8, 0xA8, 0xCC, 0xCC, 0xCC, 0xCC, 0xCD, 0xCD, 0xCD, 0xCD, 0xCD, 0xCD, 0xCD, 0xCD, 0xCD, 0xCD, 0xCD, 0xCD, 0xCD, 0xCC,
		        0xCC, 0xCC, 0xCC, 0xCC, 0xCC, 0xCC, 0xCC, 0xCC, 0xCC, 0xCC, 0xCC, 0xCC, 0xCC, 0xCC, 0xCC, 0xCC, 0xCC, 0xCC, 0xCC, 0xCC, 0xCC, 0xCC, 0xCC, 0xCC, 0xCC, 0xCC, 0xCC, 0xCC, 0xCC, 0xCC, 0xCC, 0xCC, 0xCC, 0xCC, 0xCC, 0xCC, 0xCC,
		  0xCC, 0xCC, 0xA8, 0xCC, 0xA8, 0xA8, 0xA8, 0xA8, 0xA8, 0xA8, 0xA8, 0xA8, 0xA8, 0xA8, 0xA8, 0xA8, 0xA8, 0xA8, 0xA8, 0xA8, 0xA8, 0xA8, 0xA8, 0xA8, 0xA8, 0xA8, 0xA8, 0xA8, 0xA8, 0xA8, 0xA8, 0xA8, 0xA8, 0xA8, 0xA8, 0xA8, 0xA8, 0xA8, 0xA8, 0xA8, 0xA8, 0xA8,
		        0xA8, 0xA8, 0xA8, 0xA8, 0xCC, 0xCC, 0xCC, 0xCC, 0xCC, 0xCC, 0xCC, 0xCC, 0xCC, 0xCC, 0xCC, 0xCC, 0xCC, 0xA8, 0x56, 0x2B, 0xA8, 0xCC, 0xA8, 0xCC, 0xCC, 0xCC, 0xCC, 0xCD, 0xCD, 0xCD, 0xCD, 0xCD, 0xCD, 0xCD, 0xCD, 0xCD, 0xCD, 0xCD, 0xCD, 0xCC, 0xCC,
		        0xCC, 0xCC, 0xCC, 0xCC, 0xCC, 0xCC, 0xCC, 0xCC, 0xCC, 0xCC, 0xCC, 0xCC, 0xCC, 0xCC, 0xCC, 0xCC, 0xCC, 0xCC, 0xCC, 0xCC, 0xCC, 0xCC, 0xCC, 0xCC, 0xA8, 0xCC, 0xCC, 0xCC, 0xCC, 0xCC, 0xCC, 0xCC, 0xCC, 0xCC, 0xCC, 0xCC, 0xCC,
		  0xCC, 0xCC, 0xCC, 0xCC, 0xCC, 0xA8, 0xA8, 0xA8, 0xA8, 0xA8, 0xA8, 0xA8, 0xA8, 0xA8, 0xA8, 0xA8, 0xA8, 0xA8, 0xA8, 0xA8, 0xA8, 0xA8, 0xA8, 0xA8, 0xA8, 0xA8, 0xA8, 0xA8, 0xA8, 0xA8, 0xA8, 0xA8, 0xA8, 0xA8, 0xA8, 0xA8, 0xA8, 0xA8, 0xA8, 0xA8, 0xA8, 0xA8,
		        0xA8, 0xA8, 0xA8, 0xCC, 0xCC, 0xCC, 0xCC, 0xCC, 0xCC, 0xCC, 0xCC, 0xCC, 0xCC, 0xCC, 0xCC, 0xCC, 0xCC, 0xA8, 0x55, 0x2B, 0x56, 0xA8, 0xA8, 0xCC, 0xCC, 0xCC, 0xCC, 0xCC, 0xCD, 0xCD, 0xCD, 0xCD, 0xCD, 0xCD, 0xCD, 0xCD, 0xCD, 0xCD, 0xCD, 0xCC, 0xCC,
		        0xCC, 0xCC, 0xCC, 0xCC, 0xCC, 0xCC, 0xCC, 0xCC, 0xCC, 0xCC, 0xCC, 0xCC, 0xCC, 0xCC, 0xCC, 0xCC, 0xCC, 0xCC, 0xCC, 0xCC, 0xCC, 0xCC, 0xCC, 0xCC, 0xCC, 0xCC, 0xCC, 0xCC, 0xCC, 0xCC, 0xCC, 0xCC, 0xCC, 0xCC, 0xCC, 0xCC, 0xCC,
		  0xCC, 0xCC, 0xCC, 0xCC, 0xCC, 0xA8, 0xA8, 0xA8, 0xA8, 0xA8, 0xA8, 0xA8, 0xA8, 0xA8, 0xA8, 0xA8, 0xA8, 0xA8, 0xA8, 0xCC, 0xCC, 0xCC, 0xA8, 0xA8, 0xA8, 0xA8, 0xA8, 0xA8, 0xA8, 0xA8, 0xA8, 0xA8, 0xA8, 0xA8, 0xA8, 0xA8, 0xA8, 0xA8, 0xA8, 0xA8, 0xA8, 0xA8,
		        0xA8, 0xA8, 0xA8, 0xCC, 0xCC, 0xCC, 0xCC, 0xCC, 0xCC, 0xCC, 0xCC, 0xCC, 0xCC, 0xCC, 0xCC, 0xCC, 0xCC, 0x55, 0x56, 0x56, 0x55, 0xA8, 0xCC, 0xCC, 0xCC, 0xCC, 0xCC, 0xCC, 0xCD, 0xCD, 0xCD, 0xCD, 0xCD, 0xCD, 0xCD, 0xCD, 0xCD, 0xCD, 0xCD, 0xCC, 0xCC,
		        0xCC, 0xCC, 0xCC, 0xCC, 0xCC, 0xCC, 0xCC, 0xCC, 0xCC, 0xCC, 0xCC, 0xCC, 0xCC, 0xCC, 0xCC, 0xCC, 0xCC, 0xCC, 0xCC, 0xCC, 0xCC, 0xCC, 0xCC, 0xCC, 0xCC, 0xCC, 0xCC, 0xCC, 0xCC, 0xCC, 0xCC, 0xCC, 0xCC, 0xCC, 0xCC, 0xCC, 0xCC,
		  0xCC, 0xCC, 0xCC, 0xCC, 0xCC, 0xA8, 0xA8, 0xA8, 0xA8, 0xA8, 0xA8, 0xA8, 0xA8, 0xA8, 0xA8, 0xA8, 0xA8, 0xA8, 0xA8, 0xA8, 0xCC, 0xCC, 0xA8, 0xA8, 0xA8, 0xA8, 0xA8, 0xA8, 0xA8, 0xA8, 0xA8, 0xA8, 0xA8, 0xA8, 0xA8, 0xA8, 0xA8, 0xA8, 0xA8, 0xA8, 0xA8, 0xA8,
		        0xA8, 0xA8, 0xA8, 0xA8, 0xCC, 0xCC, 0xCC, 0xCC, 0xCC, 0xCC, 0xCC, 0xCC, 0xCC, 0xCC, 0xCC, 0xCC, 0xA8, 0x56, 0xA2, 0x56, 0x4F, 0xA8, 0xA8, 0xCC, 0xCC, 0xCC, 0xCC, 0xCC, 0xCC, 0xCD, 0xCD, 0xCD, 0xCD, 0xCD, 0xCD, 0xCD, 0xCD, 0xCD, 0xCD, 0xCC, 0xCC,
		        0xCC, 0xCC, 0xCC, 0xCC, 0xCC, 0xCC, 0xCC, 0xCC, 0xCC, 0xCC, 0xCC, 0xCC, 0xCC, 0xCC, 0xCC, 0xCC, 0xCC, 0xCC, 0xCC, 0xCC, 0xCC, 0xCD, 0xCC, 0xCC, 0xCC, 0xCC, 0xCC, 0xCC, 0xCC, 0xCC, 0xCC, 0xCC, 0xCC, 0xCC, 0xCC, 0xCC, 0xCC,
		  0xCC, 0xCC, 0xCC, 0xCC, 0xCC, 0xCC, 0xA8, 0xA8, 0xA8, 0xA8, 0xA8, 0xA8, 0xA8, 0xA8, 0xA8, 0xA8, 0xA8, 0xA8, 0xA8, 0xCC, 0xCC, 0xCC, 0xCC, 0xA8, 0xA8, 0xA8, 0xA8, 0xA8, 0xA8, 0xA8, 0xA8, 0xA8, 0xA8, 0xA8, 0xA8, 0xA8, 0xA8, 0xA8, 0xA8, 0xA8, 0xA8, 0xA8,
		        0xA8, 0xA8, 0xA8, 0xA8, 0xCC, 0xCC, 0xCC, 0xCC, 0xCC, 0xCC, 0xCC, 0xCC, 0xCC, 0xCC, 0xCC, 0xCC, 0xCC, 0xA8, 0x55, 0x55, 0xA2, 0xCC, 0xCC, 0xCC, 0xCC, 0xCC, 0xCC, 0xCC, 0xCD, 0xCD, 0xCD, 0xCD, 0xCD, 0xCD, 0xCD, 0xCD, 0xCD, 0xCD, 0xCD, 0xCC, 0xCC,
		        0xCC, 0xCC, 0xCC, 0xCC, 0xCC, 0xCC, 0xCC, 0xCC, 0xCC, 0xCC, 0xCC, 0xCC, 0xCC, 0xCC, 0xCC, 0xCC, 0xCC, 0xCC, 0xCC, 0xCC, 0xCC, 0xCC, 0xCD, 0xCC, 0xCC, 0xCC, 0xCD, 0xCC, 0xCC, 0xCC, 0xCC, 0xCC, 0xCC, 0xCC, 0xCC, 0xCC, 0xCC,
		  0xCC, 0xCC, 0xCC, 0xCC, 0xCC, 0xCC, 0xCC, 0xA8, 0xA8, 0xA8, 0xA8, 0xA8, 0xA8, 0xA8, 0xA8, 0xA8, 0xCC, 0xCC, 0xCC, 0xCC, 0xCC, 0xCC, 0xA8, 0xA8, 0xA8, 0xA8, 0xA8, 0xA8, 0xA8, 0xA8, 0xA8, 0xA8, 0xA8, 0xA8, 0xA8, 0xA8, 0xA8, 0xA8, 0xA8, 0xA8, 0xA8, 0xA8,
		        0xA8, 0xA8, 0xCC, 0xCC, 0xCC, 0xCC, 0xCC, 0xCC, 0xCC, 0xCC, 0xCC, 0xCC, 0xCC, 0xCC, 0xCC, 0xCC, 0xCC, 0xCC, 0xA8, 0xA2, 0xA8, 0xCC, 0xA8, 0xCC, 0xCC, 0xCC, 0xCC, 0xCC, 0xCC, 0xCD, 0xCD, 0xCD, 0xCD, 0xCD, 0xCD, 0xCD, 0xCD, 0xCD, 0xCC, 0xCC, 0xCC,
		        0xCC, 0xCC, 0xCC, 0xCC, 0xCC, 0xCC, 0xCC, 0xCC, 0xCC, 0xCC, 0xCC, 0xCC, 0xCC, 0xCC, 0xCC, 0xCC, 0xCC, 0xCC, 0xCC, 0xCC, 0xCC, 0xCC, 0xCC, 0xCC, 0xCD, 0xCD, 0xCD, 0xCD, 0xCC, 0xCC, 0xCC, 0xCC, 0xCC, 0xCC, 0xCC, 0xCC, 0xCC,
		  0xCC, 0xCC, 0xCC, 0xCC, 0xCC, 0xCC, 0xCC, 0xCC, 0xCC, 0xCC, 0xCC, 0xA8, 0xA8, 0xA8, 0xA8, 0xA8, 0xA8, 0xCC, 0xCC, 0xCC, 0xCC, 0xCC, 0xA8, 0xCC, 0xA8, 0xA8, 0xA8, 0xA8, 0xA8, 0xA8, 0xA8, 0xA8, 0xA8, 0xA8, 0xA8, 0xA8, 0xA8, 0xA8, 0xA8, 0xA8, 0xA8, 0xA8,
		        0xA8, 0xA8, 0xCC, 0xCC, 0xCC, 0xCC, 0xCC, 0xCC, 0xCC, 0xCC, 0xCC, 0xCC, 0xCC, 0xCC, 0xCC, 0xCC, 0xCC, 0xCC, 0xCC, 0xA2, 0xCC, 0xA8, 0xCC, 0xCC, 0xA8, 0xA8, 0xA8, 0xCC, 0xCD, 0xCD, 0xCD, 0xCD, 0xCD, 0xCD, 0xCD, 0xCD, 0xCD, 0xCD, 0xCC, 0xCC, 0xCC,
		        0xCC, 0xCC, 0xCC, 0xCC, 0xCC, 0xCC, 0xCC, 0xCC, 0xCC, 0xCC, 0xCC, 0xCC, 0xCC, 0xCC, 0xCC, 0xCC, 0xCC, 0xCC, 0xCC, 0xCC, 0xCC, 0xCC, 0xCC, 0xCC, 0xCD, 0xCD, 0xCD, 0xCD, 0xCD, 0xCC, 0xCC, 0xCC, 0xCC, 0xCC, 0xCC, 0xCC, 0xCC,
		  0xCC, 0xCC, 0xCC, 0xCC, 0xCC, 0xCC, 0xCC, 0xCC, 0xCC, 0xA8, 0xA8, 0xA8, 0xA8, 0xA8, 0xA8, 0xCC, 0xCC, 0xCC, 0xCC, 0xCC, 0xCC, 0xCC, 0xA8, 0xA8, 0xA8, 0xA8, 0xA8, 0xA8, 0xA8, 0xA8, 0xA8, 0xA8, 0xA8, 0xA8, 0xA8, 0xA8, 0xA8, 0xA8, 0xA8, 0xA8, 0xA8, 0xCC,
		        0xCC, 0xCC, 0xCC, 0xCC, 0xA8, 0xA8, 0xCC, 0xCC, 0xCC, 0xCC, 0xCC, 0xCC, 0xCC, 0xCC, 0xA8, 0xA2, 0xA8, 0xCC, 0xCC, 0xA2, 0xCC, 0xA8, 0xCC, 0xCC, 0xA8, 0xA8, 0xA8, 0xCC, 0xCD, 0xCD, 0xCD, 0xCD, 0xCD, 0xCD, 0xCD, 0xA8, 0xA8, 0xCD, 0xCC, 0xCC, 0xCC,
		        0xCC, 0xCC, 0xCC, 0xCC, 0xCC, 0xCC, 0xCC, 0xCC, 0xCC, 0xCC, 0xCC, 0xCC, 0xCC, 0xCC, 0xCC, 0xCC, 0xCC, 0xCC, 0xCC, 0xCC, 0xCC, 0xCC, 0xCC, 0xCC, 0xCC, 0xCD, 0xCD, 0xCD, 0xCD, 0xCD, 0xCC, 0xCC, 0xCC, 0xCC, 0xCC, 0xCC, 0xCC,
		  0xCC, 0xCC, 0xCC, 0xCC, 0xCC, 0xCC, 0xCC, 0xCC, 0xCC, 0xCC, 0xCC, 0xCC, 0xA8, 0xA8, 0xCC, 0xCC, 0xCC, 0xCC, 0xCC, 0xCC, 0xCC, 0xCC, 0xCC, 0xA8, 0xA8, 0xA8, 0xA8, 0xA8, 0xA8, 0xA8, 0xA8, 0xA8, 0xA8, 0xA8, 0xA8, 0xA8, 0xA8, 0xA8, 0xA8, 0xA8, 0xA8, 0xCC,
		        0xCC, 0xCC, 0xCC, 0xA8, 0xA8, 0x56, 0xA8, 0xCC, 0xCC, 0xCC, 0xCC, 0xCC, 0xCC, 0xA8, 0xA8, 0x56, 0xA8, 0xCC, 0xA8, 0xA8, 0xA8, 0xA8, 0xCC, 0xCC, 0xA8, 0xA8, 0xA8, 0xCC, 0xCD, 0xCD, 0xCD, 0xCD, 0xCD, 0xCD, 0xCD, 0xA8, 0xA8, 0xCC, 0xCC, 0xCC, 0xCC,
		        0xCC, 0xCC, 0xCC, 0xCC, 0xCC, 0xCC, 0xCC, 0xCC, 0xCC, 0xCC, 0xCC, 0xCC, 0xCC, 0xCC, 0xCC, 0xCC, 0xCC, 0xCC, 0xCC, 0xCC, 0xCC, 0xCC, 0xCC, 0xCC, 0xCD, 0xCD, 0xCD, 0xCD, 0xCD, 0xCD, 0xCC, 0xCC, 0xCC, 0xCC, 0xCC, 0xCC, 0xCC,
		  0xCC, 0xCC, 0xCC, 0xCC, 0xCC, 0xCC, 0xCC, 0xCC, 0xCC, 0xCC, 0xCC, 0xCC, 0xCC, 0xCC, 0xCC, 0xCC, 0xCC, 0xCC, 0xCC, 0xCC, 0xCC, 0xCC, 0xCC, 0xCC, 0xA8, 0xA8, 0xA8, 0xA8, 0xA8, 0xA8, 0xA8, 0xA8, 0xA8, 0xA8, 0xA8, 0xA8, 0xA8, 0xA8, 0xCC, 0xCC, 0xCC, 0xCC,
		        0xCC, 0xCC, 0xCC, 0xA8, 0xA8, 0x56, 0xA8, 0xCC, 0xCC, 0xCC, 0xCC, 0xCC, 0xCC, 0xCC, 0xA8, 0x55, 0xCC, 0xA8, 0x56, 0x2B, 0x2B, 0xA2, 0xA8, 0xA8, 0xA8, 0x2B, 0x55, 0xCD, 0xCD, 0xCD, 0xCD, 0xCD, 0xCD, 0xCD, 0xA8, 0xA8, 0xA8, 0xCD, 0xCD, 0xCC, 0xCC,
		        0xCC, 0xCC, 0xCC, 0xCC, 0xCC, 0xCC, 0xCC, 0xCC, 0xCC, 0xCC, 0xCC, 0xCC, 0xCC, 0xCC, 0xCC, 0xCC, 0xCC, 0xCC, 0xCC, 0xCC, 0xCC, 0xCC, 0xCC, 0xCC, 0xCD, 0xCC, 0xCD, 0xCD, 0xCD, 0xCD, 0xCD, 0xCD, 0xCD, 0xCC, 0xCC, 0xCC, 0xCC,
		  0xCC, 0xCC, 0xCC, 0xCC, 0xCC, 0xCC, 0xCC, 0xCC, 0xCC, 0xCC, 0xCC, 0xCC, 0xCC, 0xCC, 0xCC, 0xCC, 0xCC, 0xCC, 0xCC, 0xCC, 0xCC, 0xCC, 0xCC, 0xCC, 0xCC, 0xCC, 0xCC, 0xA8, 0xA8, 0xA8, 0xA8, 0xA8, 0xA8, 0xA8, 0xA8, 0xA8, 0xA8, 0xCC, 0xCC, 0xCC, 0xCC, 0xCC,
		        0xCC, 0xCC, 0xCC, 0xCC, 0xA8, 0x2B, 0x55, 0xA8, 0xCC, 0xCC, 0xCC, 0xCC, 0xCC, 0xA8, 0xA8, 0x55, 0xA8, 0xA2, 0x56, 0x55, 0x2B, 0xA8, 0xA8, 0xCC, 0xA8, 0x31, 0xA2, 0xCD, 0xCD, 0xCD, 0xCD, 0xCD, 0xCD, 0xA9, 0xA8, 0xA8, 0xA8, 0xCD, 0xCD, 0xCC, 0xCC,
		        0xCC, 0xCC, 0xCC, 0xCC, 0xCC, 0xCC, 0xCC, 0xCC, 0xCC, 0xCC, 0xCC, 0xCC, 0xCC, 0xCC, 0xCC, 0xCC, 0xCC, 0xCC, 0xCC, 0xCC, 0xCC, 0xCC, 0xCC, 0xCC, 0xCD, 0xCD, 0xCD, 0xCD, 0xCD, 0xCD, 0xCD, 0xCD, 0xCD, 0xCD, 0xCD, 0xCC, 0xCC,
		  0xCC, 0xCC, 0xCC, 0xCC, 0xCC, 0xCC, 0xCC, 0xCC, 0xCC, 0xCC, 0xCC, 0xCC, 0xCC, 0xCC, 0xCC, 0xCC, 0xCC, 0xCC, 0xCC, 0xCC, 0xCC, 0xCC, 0xCC, 0xCC, 0xCC, 0xCC, 0xCC, 0xCC, 0xA8, 0xA8, 0xA8, 0xA8, 0xCC, 0xA8, 0xA8, 0xA8, 0xCC, 0xCC, 0xCC, 0xCC, 0xCC, 0xCC,
		        0xCC, 0xCC, 0xCC, 0xCC, 0xA8, 0x2B, 0x2B, 0xA8, 0xCC, 0xCC, 0xCC, 0xCC, 0xCC, 0xA8, 0x55, 0x55, 0xA8, 0x55, 0x2B, 0x2B, 0x2B, 0xA8, 0x4F, 0xA8, 0xA8, 0x55, 0xA2, 0xCC, 0xCD, 0xCD, 0xCD, 0xCD, 0xCD, 0xA8, 0xA8, 0x56, 0xA8, 0xCD, 0xCC, 0xCC, 0xCC,
		        0xCC, 0xCC, 0xCC, 0xCC, 0xCC, 0xCC, 0xCC, 0xCC, 0xCC, 0xCC, 0xCC, 0xCC, 0xCC, 0xCC, 0xCC, 0xCC, 0xCC, 0xCC, 0xCC, 0xCC, 0xCC, 0xCC, 0xCC, 0xCC, 0xCC, 0xCD, 0xCD, 0xCD, 0xCD, 0xCD, 0xCD, 0xCD, 0xCD, 0xCD, 0xCD, 0xCD, 0xCD,
		  0xCC, 0xCC, 0xCC, 0xCC, 0xCC, 0xCC, 0xCC, 0xCC, 0xCC, 0xCC, 0xCC, 0xCC, 0xCC, 0xCC, 0xCC, 0xCC, 0xCC, 0xCC, 0xCC, 0xCC, 0xCC, 0xCC, 0xCC, 0xCC, 0xCC, 0xCC, 0xCC, 0xA8, 0xA8, 0xCC, 0xCC, 0xCC, 0xCC, 0xCC, 0xCC, 0xCC, 0xCC, 0xCC, 0xCC, 0xCC, 0xCC, 0xCC,
		        0xCC, 0xCC, 0xCC, 0xCC, 0xA2, 0x55, 0x55, 0xA8, 0xCC, 0xCC, 0xCC, 0xCC, 0xCC, 0xA8, 0x55, 0x2B, 0xA8, 0x2B, 0x2B, 0x2B, 0x56, 0x56, 0x06, 0x55, 0x56, 0x55, 0xA8, 0xCD, 0xCD, 0xCD, 0xCD, 0xCD, 0xCD, 0xA8, 0x5C, 0x55, 0xCD, 0xCC, 0xCC, 0xCC, 0xCC,
		        0xCC, 0xCC, 0xCC, 0xCC, 0xCC, 0xCC, 0xCC, 0xCC, 0xCC, 0xCC, 0xCC, 0xCC, 0xCC, 0xCC, 0xCC, 0xCC, 0xCC, 0xCC, 0xCC, 0xCC, 0xCC, 0xCC, 0xCC, 0xCC, 0xCC, 0xCD, 0xCD, 0xCD, 0xCD, 0xCD, 0xCD, 0xCD, 0xCD, 0xCD, 0xCD, 0xCD, 0xCD,
		  0xCC, 0xCC, 0xCC, 0xCC, 0xCC, 0xCC, 0xCC, 0xCC, 0xCC, 0xCC, 0xCC, 0xCC, 0xCC, 0xCC, 0xCC, 0xCC, 0xCC, 0xCC, 0xCC, 0xCC, 0xCC, 0xCC, 0xCC, 0xCC, 0xCC, 0xCC, 0xA8, 0xCC, 0xCC, 0xCC, 0xCC, 0xCC, 0xCC, 0xCC, 0xCC, 0xCC, 0xCC, 0xCC, 0xCC, 0xCC, 0xCC, 0xCC,
		        0xCC, 0xCC, 0xCC, 0xCC, 0xA8, 0xA2, 0x55, 0x55, 0xA8, 0xCC, 0xCC, 0xA8, 0xA8, 0xA8, 0x5C, 0x55, 0xA8, 0x31, 0x5C, 0x2B, 0x2B, 0x56, 0x06, 0x56, 0xA8, 0xA8, 0xA8, 0xA8, 0xCD, 0xCD, 0xCD, 0xCD, 0xA8, 0xA8, 0xA8, 0xA2, 0xCC, 0xCC, 0xCC, 0xCC, 0xCC,
		        0xCC, 0xCC, 0xCC, 0xCC, 0xCC, 0xCC, 0xCC, 0xCC, 0xCC, 0xCC, 0xCC, 0xCC, 0xCC, 0xCC, 0xCC, 0xCC, 0xCC, 0xCC, 0xCC, 0xCC, 0xCC, 0xCC, 0xCC, 0xCC, 0xCC, 0xCD, 0xCD, 0xCD, 0xCD, 0xCD, 0xCD, 0xCD, 0xCD, 0xCD, 0xCD, 0xCD, 0xCD,
		  0xCC, 0xCC, 0xCC, 0xCC, 0xCC, 0xCC, 0xCC, 0xCC, 0xCC, 0xCC, 0xCC, 0xCC, 0xCC, 0xCC, 0xCC, 0xCC, 0xCC, 0xCC, 0xCC, 0xCC, 0xCC, 0xCC, 0xCC, 0xCC, 0xCC, 0xCC, 0xCC, 0xCC, 0xCC, 0xCC, 0xCC, 0xCC, 0xCC, 0xCC, 0xCC, 0xCC, 0xCC, 0xCC, 0xCC, 0xCC, 0xCC, 0xCC,
		        0xCC, 0xCC, 0xCC, 0xCC, 0xCC, 0xA8, 0x55, 0xA8, 0xA8, 0xA8, 0xA8, 0xA8, 0xA8, 0xA8, 0x56, 0x55, 0x55, 0x55, 0x55, 0x31, 0x2B, 0x55, 0x00, 0x56, 0x56, 0x31, 0x31, 0xA2, 0xA8, 0xA8, 0xA8, 0xA8, 0xA8, 0xAF, 0xA8, 0xA8, 0xCC, 0xCC, 0xCC, 0xCC, 0xCC,
		        0xCC, 0xCC, 0xCC, 0xCC, 0xCC, 0xCC, 0xCC, 0xCC, 0xCC, 0xCC, 0xCC, 0xCC, 0xCC, 0xCC, 0xCC, 0xCC, 0xCC, 0xCC, 0xCC, 0xCC, 0xCC, 0xCC, 0xCC, 0xCC, 0xCD, 0xCD, 0xCD, 0xCD, 0xCD, 0xCD, 0xCD, 0xCD, 0xCD, 0xCD, 0xCD, 0xCD, 0xCD,
		  0xCC, 0xCC, 0xCC, 0xCC, 0xCC, 0xCC, 0xCC, 0xCC, 0xCC, 0xCC, 0xCC, 0xCC, 0xCC, 0xCC, 0xCC, 0xCC, 0xCC, 0xCC, 0xCC, 0xCC, 0xCC, 0xCC, 0xCC, 0xCC, 0xCC, 0xCC, 0xCC, 0xCC, 0xCC, 0xCC, 0xCC, 0xCC, 0xCC, 0xCC, 0xCC, 0xCC, 0xCC, 0xCC, 0xCC, 0xCC, 0xCC, 0xCC,
		        0xCC, 0xCC, 0xCC, 0xCC, 0xCC, 0xA8, 0x5C, 0x5C, 0x55, 0x56, 0xA8, 0xA8, 0xA8, 0x56, 0x31, 0x31, 0x2B, 0x55, 0x56, 0x55, 0x55, 0x31, 0x2B, 0xA8, 0x55, 0x2B, 0x2B, 0xA2, 0xCD, 0xCD, 0xA9, 0x56, 0x5C, 0x5C, 0x55, 0x56, 0xA8, 0xCC, 0xCC, 0xCC, 0xCC,
		        0xCC, 0xCC, 0xCC, 0xCC, 0xCC, 0xCC, 0xCC, 0xCC, 0xCC, 0xCC, 0xCC, 0xCC, 0xCC, 0xCC, 0xCC, 0xCC, 0xCC, 0xCC, 0xCC, 0xCC, 0xCC, 0xCC, 0xCC, 0xCD, 0xCC, 0xCD, 0xCD, 0xCD, 0xCD, 0xCD, 0xCD, 0xCD, 0xCD, 0xCD, 0xCD, 0xCD, 0xCD,
		  0xCC, 0xCC, 0xCC, 0xCC, 0xCC, 0xCC, 0xCC, 0xCC, 0xCC, 0xCC, 0xCC, 0xCC, 0xCC, 0xCC, 0xCC, 0xCC, 0xCC, 0xCC, 0xCC, 0xCC, 0xCC, 0xCC, 0xCC, 0xCC, 0xCC, 0xCC, 0xCC, 0xCC, 0xCC, 0xCC, 0xCC, 0xCC, 0xCC, 0xCC, 0xCC, 0xCC, 0xCC, 0xCC, 0xCC, 0xCC, 0xCC, 0xCC,
		        0xCC, 0xCC, 0xCC, 0xCC, 0xCC, 0xA8, 0x31, 0x56, 0x2B, 0x31, 0xA8, 0xA8, 0xA8, 0x06, 0x2B, 0x2B, 0x2B, 0x2B, 0x56, 0x55, 0x2B, 0x56, 0x56, 0x56, 0x2A, 0x00, 0x00, 0xA8, 0xCD, 0xA8, 0xA8, 0x5C, 0x31, 0x2B, 0x55, 0x55, 0xCC, 0xCC, 0xCC, 0xCC, 0xCC,
		        0xCC, 0xCC, 0xCC, 0xCC, 0xCC, 0xCC, 0xCC, 0xCC, 0xCC, 0xCC, 0xCC, 0xCC, 0xCC, 0xCC, 0xCC, 0xCC, 0xCC, 0xCC, 0xCC, 0xCC, 0xCC, 0xCC, 0xCD, 0xCC, 0xCD, 0xCD, 0xCD, 0xCD, 0xCD, 0xCD, 0xCD, 0xCD, 0xCD, 0xCD, 0xCD, 0xCD, 0xCD,
		  0xCC, 0xCC, 0xCC, 0xCC, 0xCC, 0xCC, 0xCC, 0xCC, 0xCC, 0xCC, 0xCC, 0xCC, 0xCC, 0xCC, 0xCC, 0xCC, 0xCC, 0xCC, 0xCC, 0xCC, 0xCC, 0xCC, 0xCC, 0xCC, 0xCC, 0xCC, 0xCC, 0xCC, 0xCC, 0xCC, 0xCC, 0xCC, 0xCC, 0xCC, 0xCC, 0xCC, 0xCC, 0xCC, 0xCC, 0xCC, 0xCC, 0xCC,
		        0xCC, 0xCC, 0xCC, 0xCC, 0xCC, 0xA8, 0x2B, 0x2A, 0x00, 0x2A, 0x31, 0xA2, 0xA8, 0x06, 0x00, 0x55, 0x2A, 0x31, 0x5C, 0x56, 0x55, 0x55, 0x56, 0x5C, 0x00, 0x00, 0x06, 0xA2, 0xCD, 0xA8, 0x5C, 0x55, 0x31, 0x00, 0x2A, 0x5C, 0xA8, 0xCC, 0xCC, 0xCC, 0xCC,
		        0xCC, 0xCC, 0xCC, 0xCC, 0xCC, 0xCC, 0xCC, 0xCC, 0xCC, 0xCC, 0xCC, 0xCC, 0xCC, 0xCC, 0xCC, 0xCC, 0xCC, 0xCC, 0xCC, 0xCC, 0xCC, 0xCC, 0xCC, 0xCC, 0xCC, 0xCD, 0xCD, 0xCD, 0xCD, 0xCD, 0xCD, 0xCD, 0xCD, 0xCD, 0xCD, 0xCD, 0xCD,
		  0xCC, 0xCC, 0xCC, 0xCC, 0xCC, 0xCC, 0xCC, 0xCC, 0xCC, 0xCC, 0xCC, 0xCC, 0xCC, 0xCC, 0xCC, 0xCC, 0xCC, 0xCC, 0xCC, 0xCC, 0xCC, 0xCC, 0xCC, 0xCC, 0xCC, 0xCC, 0xCC, 0xCC, 0xCC, 0xCC, 0xCC, 0xCC, 0xCC, 0xCC, 0xCC, 0xCC, 0xCC, 0xCC, 0xCC, 0xCC, 0xCC, 0xCC,
		        0xCC, 0xCC, 0xCC, 0xCC, 0xA8, 0x55, 0x00, 0x00, 0x2B, 0x06, 0x2B, 0x55, 0xA8, 0x2B, 0x00, 0x2B, 0x00, 0x2B, 0x5C, 0x56, 0x55, 0x56, 0x55, 0x55, 0x00, 0x00, 0x2A, 0xA8, 0xCD, 0x56, 0x56, 0x2B, 0x2B, 0x00, 0x00, 0x55, 0xA8, 0xCC, 0xCC, 0xCC, 0xCC,
		        0xCC, 0xCC, 0xCC, 0xCC, 0xCC, 0xCC, 0xCC, 0xCC, 0xCC, 0xCC, 0xCC, 0xCC, 0xCC, 0xCC, 0xCC, 0xCC, 0xCC, 0xCC, 0xCC, 0xCC, 0xCC, 0xCD, 0xCC, 0xCD, 0xCD, 0xCC, 0xCC, 0xCD, 0xCD, 0xCD, 0xCD, 0xCD, 0xCD, 0xCD, 0xCD, 0xCD, 0xCD,
		  0xCC, 0xCD, 0xCC, 0xCC, 0xCC, 0xCC, 0xCC, 0xCC, 0xCC, 0xCC, 0xCC, 0xCC, 0xCC, 0xCC, 0xCC, 0xCC, 0xCC, 0xCC, 0xCC, 0xCC, 0xCC, 0xCC, 0xCC, 0xCC, 0xCC, 0xCC, 0xCC, 0xCC, 0xCC, 0xCC, 0xCC, 0xCC, 0xCC, 0xCC, 0xCC, 0xCC, 0xCC, 0xCC, 0xCC, 0xCC, 0xCC, 0xCC,
		        0xCC, 0xCC, 0xCC, 0xCC, 0xA8, 0xA8, 0x2B, 0x2A, 0x2B, 0x00, 0x00, 0x2B, 0xA8, 0x55, 0x00, 0x31, 0x00, 0x2B, 0x5C, 0x56, 0x55, 0x5C, 0x55, 0x2B, 0x00, 0x00, 0x2B, 0xA9, 0xA8, 0x56, 0x2B, 0x00, 0x2B, 0x2B, 0x56, 0xA8, 0xA8, 0xCC, 0xCC, 0xCC, 0xCC,
		        0xCC, 0xCC, 0xCC, 0xCC, 0xCC, 0xCC, 0xCC, 0xCC, 0xCC, 0xCC, 0xCC, 0xCC, 0xCC, 0xCC, 0xCC, 0xCC, 0xCC, 0xCC, 0xCC, 0xCC, 0xCC, 0xCC, 0xCC, 0xCC, 0xCC, 0xCC, 0xCC, 0xCC, 0xCD, 0xCD, 0xCD, 0xCD, 0xCD, 0xCD, 0xCD, 0xCD, 0xCD,
		  0xCC, 0xCD, 0xCD, 0xCD, 0xCC, 0xCC, 0xCC, 0xCC, 0xCC, 0xCC, 0xCD, 0xCC, 0xCC, 0xCC, 0xCC, 0xCC, 0xCD, 0xCC, 0xCC, 0xCC, 0xCC, 0xCC, 0xCC, 0xCC, 0xCC, 0xCC, 0xCC, 0xCC, 0xCC, 0xCC, 0xCC, 0xCC, 0xCC, 0xCC, 0xCC, 0xCC, 0xCC, 0xCC, 0xCC, 0xCC, 0xCC, 0xCC,
		        0xCC, 0xCC, 0xCC, 0xCC, 0xA8, 0xA8, 0xA2, 0x56, 0x2B, 0x00, 0x00, 0x4F, 0xA2, 0x55, 0x00, 0x2B, 0x00, 0x2B, 0x31, 0x2B, 0x2B, 0x2B, 0x2B, 0x00, 0x00, 0x06, 0x2B, 0xA9, 0xA8, 0x2B, 0x00, 0x00, 0x2B, 0x55, 0xA8, 0x5C, 0xA8, 0xCC, 0xCC, 0xCC, 0xCC,
		        0xCC, 0xCC, 0xCC, 0xCC, 0xCC, 0xCC, 0xCC, 0xCC, 0xCC, 0xCC, 0xCC, 0xCC, 0xCC, 0xCC, 0xCC, 0xCC, 0xCC, 0xCC, 0xCC, 0xCC, 0xCC, 0xCC, 0xCC, 0xCC, 0xCC, 0xCC, 0xCC, 0xCC, 0xCC, 0xCC, 0xCD, 0xCD, 0xCD, 0xCD, 0xCD, 0xCD, 0xCD,
		  0xCC, 0xCC, 0xCC, 0xCD, 0xCD, 0xCD, 0xCC, 0xCD, 0xCC, 0xCC, 0xCC, 0xCC, 0xCC, 0xCC, 0xCC, 0xCD, 0xCD, 0xCD, 0xCC, 0xCC, 0xCC, 0xCC, 0xCC, 0xCC, 0xCC, 0xCC, 0xCC, 0xCC, 0xCC, 0xCC, 0xCC, 0xCC, 0xCC, 0xCC, 0xCC, 0xCC, 0xCC, 0xCC, 0xCC, 0xCC, 0xCC, 0xCC,
		        0xCC, 0xCC, 0xCC, 0xCC, 0xA8, 0x55, 0xCC, 0xA8, 0x2B, 0x00, 0x00, 0xA2, 0xA2, 0x56, 0x2B, 0x55, 0x2B, 0x2B, 0x56, 0x56, 0x2B, 0x31, 0x2B, 0x00, 0x2A, 0x06, 0x56, 0x56, 0xCD, 0x55, 0x2B, 0x4F, 0x2B, 0xA8, 0xA8, 0x55, 0xCC, 0xCC, 0xCC, 0xA8, 0xCC,
		        0xCC, 0xCC, 0xCC, 0xCC, 0xCC, 0xCC, 0xCC, 0xCC, 0xCC, 0xCC, 0xCC, 0xCC, 0xCC, 0xCC, 0xCC, 0xCC, 0xCC, 0xCC, 0xCC, 0xCC, 0xCC, 0xCC, 0xCC, 0xCC, 0xCC, 0xCC, 0xCC, 0xCC, 0xCC, 0xCC, 0xCC, 0xCC, 0xCD, 0xCD, 0xCD, 0xCD, 0xCD,
		  0xCD, 0xCC, 0xCC, 0xCD, 0xCD, 0xCD, 0xCD, 0xCD, 0xCD, 0xCC, 0xCC, 0xCC, 0xCC, 0xCC, 0xCC, 0xCD, 0xCD, 0xCD, 0xCC, 0xCC, 0xCC, 0xCC, 0xCC, 0xCC, 0xCC, 0xCC, 0xCC, 0xCC, 0xCC, 0xCC, 0xCC, 0xCC, 0xCC, 0xCC, 0xCC, 0xCC, 0xCC, 0xCC, 0xCC, 0xCC, 0xCC, 0xCC,
		        0xA8, 0xA8, 0xA9, 0xA8, 0xA8, 0x56, 0xA9, 0x56, 0x56, 0x56, 0x2C, 0x56, 0x56, 0x56, 0x32, 0x56, 0x56, 0x32, 0x56, 0x56, 0x56, 0x56, 0x56, 0x2B, 0x32, 0x32, 0x56, 0x56, 0x56, 0x56, 0x56, 0x56, 0x56, 0x56, 0x5D, 0x56, 0x56, 0x5C, 0x56, 0xA2, 0xA8,
		        0xCC, 0xCC, 0xCC, 0xCC, 0xCC, 0xCC, 0xCC, 0xCC, 0xCC, 0xCC, 0xCC, 0xCC, 0xCC, 0xCC, 0xCC, 0xCC, 0xCC, 0xCC, 0xCC, 0xCC, 0xCC, 0xCC, 0xCC, 0xCC, 0xCC, 0xCC, 0xCC, 0xCC, 0xCC, 0xCC, 0xCC, 0xCC, 0xCC, 0xCC, 0xCC, 0xCC, 0xCD,
		  0xCD, 0xCD, 0xCC, 0xCC, 0xCC, 0xCC, 0xCD, 0xCD, 0xCD, 0xCD, 0xCD, 0xCC, 0xCD, 0xCD, 0xCD, 0xCD, 0xCD, 0xCD, 0xCD, 0xCC, 0xCC, 0xCC, 0xCC, 0xCC, 0xCC, 0xCC, 0xCC, 0xCC, 0xCC, 0xCC, 0xCC, 0xCC, 0xCC, 0xCC, 0xCC, 0xCC, 0xCC, 0xCC, 0xCC, 0xCC, 0xA2, 0xA8,
		        0x56, 0x57, 0x5D, 0x5D, 0x5D, 0x5D, 0x5D, 0x5D, 0x5D, 0x5D, 0x5D, 0x5D, 0x5D, 0x5D, 0x5D, 0x57, 0x5D, 0x5D, 0x5D, 0x5D, 0x5D, 0x5D, 0x5D, 0x56, 0x57, 0x57, 0x57, 0x57, 0x5D, 0x5D, 0x5D, 0x5D, 0x5D, 0x5D, 0x5D, 0x5D, 0x5D, 0x5D, 0x5D, 0xA9, 0xA2,
		        0xA2, 0xA8, 0xCC, 0xCC, 0xCC, 0xA8, 0xCC, 0xCC, 0xCC, 0xCC, 0xCC, 0xCC, 0xCC, 0xCC, 0xCC, 0xCC, 0xCC, 0xCC, 0xCC, 0xCC, 0xCC, 0xCC, 0xCC, 0xCC, 0xCC, 0xCC, 0xCC, 0xCC, 0xCC, 0xCC, 0xCC, 0xCC, 0xCC, 0xCC, 0xCC, 0xCC, 0xCD,
		  0xCD, 0xCD, 0xCC, 0xCC, 0xCC, 0xCC, 0xCC, 0xCD, 0xCD, 0xCD, 0xCD, 0xCC, 0xCC, 0xCC, 0xCC, 0xCC, 0xCD, 0xCD, 0xCC, 0xCC, 0xCC, 0xCC, 0xCC, 0xCC, 0xCC, 0xCC, 0xCC, 0xCC, 0xCC, 0xCC, 0xCC, 0xCC, 0xCC, 0xCC, 0xCC, 0xCC, 0xCC, 0xCC, 0xCC, 0xCC, 0xA9, 0x5D,
		        0x5D, 0x5D, 0x57, 0x5D, 0x5D, 0x5D, 0x5D, 0x5D, 0x5D, 0x5D, 0x57, 0x57, 0x57, 0x57, 0x5D, 0x57, 0x57, 0x57, 0x57, 0x57, 0x57, 0x57, 0x5D, 0x5D, 0x5D, 0x5D, 0x5D, 0x5D, 0x5D, 0x5D, 0x5D, 0x5D, 0x5D, 0x5D, 0x5D, 0x5D, 0x57, 0x57, 0x5D, 0x5D, 0x5D,
		        0x5D, 0xA8, 0xA8, 0xA8, 0xA8, 0xA8, 0xA8, 0xA8, 0xA8, 0xA8, 0xA8, 0xCC, 0xCC, 0xCC, 0xCC, 0xCC, 0xCC, 0xCC, 0xCC, 0xCC, 0xCC, 0xCC, 0xCC, 0xCC, 0xCC, 0xCC, 0xCC, 0xCC, 0xCC, 0xCC, 0xCC, 0xCC, 0xCC, 0xCC, 0xCC, 0xCC, 0xCC,
		  0xCC, 0xCD, 0xCD, 0xCC, 0xCC, 0xCC, 0xCC, 0xCC, 0xCC, 0xCC, 0xCC, 0xCC, 0xCC, 0xCC, 0xCC, 0xCC, 0xCC, 0xCC, 0xCC, 0xCC, 0xCC, 0xCC, 0xCC, 0xCC, 0xCC, 0xCC, 0xCC, 0xCC, 0xCC, 0xCC, 0xCC, 0xCC, 0xCC, 0xCC, 0xCC, 0xCC, 0xCC, 0xCC, 0xCC, 0xCC, 0x56, 0x2B,
		        0x56, 0x32, 0x57, 0x2C, 0x2C, 0x2C, 0x56, 0x32, 0x56, 0x2C, 0x2C, 0x2C, 0x32, 0x56, 0x57, 0x2C, 0x2C, 0x2C, 0x32, 0x56, 0x57, 0x32, 0x2C, 0x32, 0x56, 0x56, 0x57, 0x32, 0x32, 0x32, 0x32, 0x57, 0x56, 0x56, 0x2C, 0x32, 0x32, 0x57, 0x32, 0x32, 0x2C,
		        0x56, 0xA8, 0xCC, 0xCC, 0xCC, 0xCC, 0xCC, 0xCC, 0xCC, 0xCC, 0xCC, 0xCC, 0xCC, 0xCC, 0xCC, 0xCC, 0xCC, 0xCC, 0xCC, 0xCC, 0xCC, 0xCC, 0xCC, 0xCC, 0xCC, 0xCC, 0xCC, 0xCC, 0xCC, 0xCC, 0xCC, 0xCC, 0xCC, 0xCC, 0xCC, 0xCC, 0xCC,
		  0xA8, 0xA8, 0xA8, 0xA8, 0xA8, 0xA8, 0xA8, 0xA8, 0xA8, 0xA8, 0xA8, 0xA8, 0xA8, 0xA8, 0xA8, 0xA8, 0xA8, 0xA8, 0xA8, 0xA8, 0xA8, 0xA8, 0xA8, 0xA8, 0xA8, 0xA8, 0xA8, 0xA8, 0xA8, 0xA8, 0xA8, 0xA8, 0xA8, 0xA8, 0xA8, 0xA8, 0xA8, 0xA8, 0xA8, 0xA8, 0x56, 0x2B,
		        0x2B, 0x2B, 0x2C, 0x2B, 0x2B, 0x2B, 0x2C, 0x2B, 0x2C, 0x2B, 0x2B, 0x2B, 0x2B, 0x2B, 0x2B, 0x2B, 0x07, 0x07, 0x07, 0x07, 0x2C, 0x2B, 0x2B, 0x2B, 0x2B, 0x2B, 0x2C, 0x2B, 0x2B, 0x2B, 0x2B, 0x2B, 0x2B, 0x2B, 0x2B, 0x2B, 0x2B, 0x2C, 0x2B, 0x2B, 0x2B,
		        0x56, 0xA2, 0xA2, 0xA2, 0xA2, 0xA2, 0xA2, 0xA2, 0xA2, 0xA2, 0xA2, 0xA2, 0xA2, 0xA2, 0xA2, 0xA2, 0xA2, 0xA2, 0xA2, 0xA2, 0xA2, 0xA2, 0xA2, 0xA2, 0xA2, 0xA2, 0xA2, 0xA2, 0xA2, 0xA2, 0xA2, 0xA2, 0xA2, 0xA2, 0xA2, 0xA2, 0xA2,
		  0x5D, 0xA9, 0x5D, 0x5D, 0x5D, 0x5D, 0x57, 0x5D, 0x57, 0x57, 0x57, 0x57, 0x5D, 0xA9, 0xA9, 0x5D, 0x5D, 0x5D, 0x5D, 0x5D, 0x57, 0x5D, 0x5D, 0x57, 0x57, 0x57, 0x57, 0x5D, 0x5D, 0x5D, 0x5D, 0x5D, 0x5D, 0x5D, 0x57, 0x57, 0x57, 0x57, 0x5D, 0x5D, 0x56, 0x2B,
		        0x32, 0x2C, 0x32, 0x32, 0x32, 0x32, 0x56, 0x2C, 0x32, 0x32, 0x57, 0x57, 0x56, 0x2C, 0x32, 0x2C, 0x32, 0x32, 0x32, 0x2B, 0x2C, 0x2C, 0x32, 0x32, 0x32, 0x2B, 0x2C, 0x2C, 0x56, 0x56, 0x56, 0x2C, 0x2C, 0x32, 0x56, 0x56, 0x57, 0x32, 0x32, 0x2B, 0x07,
		        0x32, 0x56, 0x56, 0x57, 0x57, 0x57, 0x5D, 0x57, 0x57, 0x57, 0x57, 0x5D, 0x5D, 0x5D, 0x5D, 0x5D, 0x5D, 0x5D, 0x5D, 0x5D, 0x57, 0x57, 0x57, 0x5D, 0x57, 0x57, 0x57, 0x57, 0x57, 0x57, 0x5D, 0x57, 0x5D, 0x5D, 0x57, 0x5D, 0x57,
		  0x32, 0x56, 0x56, 0x57, 0x32, 0x32, 0x32, 0x5D, 0x56, 0x57, 0x2C, 0x2C, 0x2C, 0x57, 0x56, 0x56, 0x32, 0x32, 0x32, 0x56, 0x56, 0x32, 0x32, 0x32, 0x32, 0x56, 0x56, 0x32, 0x2C, 0x2C, 0x32, 0x56, 0x56, 0x2C, 0x2C, 0x2C, 0x32, 0x32, 0x56, 0x2C, 0x2B, 0x07,
		        0x32, 0x5D, 0x5E, 0x57, 0x5D, 0x5D, 0x57, 0x5D, 0x5D, 0x56, 0x5D, 0x5D, 0x5D, 0x5D, 0x56, 0x5D, 0x57, 0x5D, 0x57, 0x57, 0x57, 0x57, 0x5D, 0x5D, 0x5D, 0x5D, 0x57, 0x56, 0x5D, 0x57, 0x5D, 0x5D, 0x57, 0x57, 0x5D, 0x5D, 0x5D, 0xAA, 0xA9, 0x2C, 0x00,
		        0x2B, 0x2B, 0x56, 0x56, 0x32, 0x2B, 0x2B, 0x2B, 0x32, 0x56, 0x2C, 0x2B, 0x2B, 0x2C, 0x32, 0x56, 0x2C, 0x2B, 0x2B, 0x32, 0x32, 0x32, 0x2C, 0x2B, 0x2B, 0x56, 0x32, 0x56, 0x2C, 0x2C, 0x2B, 0x56, 0x32, 0x56, 0x2C, 0x2B, 0x2B,
		  0x2B, 0x2C, 0x2B, 0x32, 0x2B, 0x2B, 0x2B, 0x32, 0x2B, 0x32, 0x2B, 0x2B, 0x2B, 0x2C, 0x2B, 0x32, 0x2B, 0x2B, 0x2B, 0x2C, 0x2B, 0x2B, 0x2B, 0x2B, 0x2B, 0x2C, 0x2B, 0x2B, 0x2B, 0x2B, 0x2B, 0x2B, 0x2B, 0x2B, 0x2B, 0x2B, 0x2B, 0x2B, 0x56, 0x57, 0x56, 0x57,
		        0x57, 0x5D, 0x5E, 0x5D, 0x57, 0x5D, 0x5D, 0x5D, 0x5D, 0x5D, 0xAA, 0x5D, 0x5D, 0x5E, 0x5D, 0x5D, 0x5D, 0x5D, 0x5D, 0x57, 0xA9, 0xA9, 0x5D, 0x5D, 0xAA, 0x5D, 0x5D, 0x5D, 0x57, 0x5D, 0x5D, 0x56, 0x57, 0x5D, 0x5D, 0x5D, 0x5D, 0xAA, 0xA9, 0x32, 0x2B,
		        0x2B, 0x2B, 0x56, 0x2B, 0x2C, 0x32, 0x32, 0x2C, 0x2B, 0x2B, 0x2B, 0x2B, 0x2B, 0x2B, 0x2B, 0x2C, 0x2B, 0x2C, 0x2B, 0x2C, 0x2B, 0x2C, 0x2C, 0x32, 0x2C, 0x32, 0x2B, 0x32, 0x32, 0x32, 0x2C, 0x56, 0x2B, 0x32, 0x32, 0x32, 0x2C,
		  0xA9, 0xA9, 0x56, 0x56, 0x56, 0x5D, 0x5D, 0x5D, 0x56, 0x57, 0x56, 0x5D, 0x5D, 0x5D, 0x32, 0x56, 0x56, 0x5D, 0x5D, 0x57, 0x32, 0x56, 0x56, 0x5D, 0x5D, 0x56, 0x32, 0x56, 0x56, 0x56, 0x56, 0x56, 0x32, 0x56, 0xA9, 0x5D, 0x5D, 0x5D, 0x5D, 0x5D, 0x5D, 0x5D,
		        0x5D, 0x5E, 0x5E, 0x57, 0x56, 0x5D, 0x5D, 0x5D, 0x5D, 0x5D, 0xAA, 0x57, 0x57, 0xAA, 0x57, 0x5D, 0x5D, 0x5D, 0x5D, 0x5D, 0x5D, 0x5D, 0xA9, 0xAA, 0xA9, 0x5D, 0x5D, 0x5D, 0x5D, 0x5D, 0x5D, 0x5D, 0x5D, 0x5D, 0x5D, 0x57, 0x5D, 0x5E, 0x5D, 0x32, 0x32,
		        0x32, 0x56, 0x5D, 0x5D, 0x5D, 0x5D, 0x5D, 0x5D, 0x56, 0x56, 0x56, 0x5D, 0x5D, 0x5D, 0x56, 0x57, 0x5D, 0xA9, 0xA9, 0x57, 0x56, 0x57, 0x5D, 0xA9, 0xA9, 0xA9, 0x5D, 0x5D, 0xA9, 0xA9, 0xA9, 0x5D, 0x5D, 0x5D, 0xA9, 0xA9, 0xA9,
		  0xAA, 0xAA, 0xAA, 0xAA, 0xAA, 0xAA, 0xAA, 0xAA, 0xAA, 0xAA, 0xAA, 0xAA, 0xAA, 0xAA, 0xAA, 0xAA, 0xAA, 0xA9, 0xA9, 0xA9, 0xA9, 0xA9, 0xA9, 0xA9, 0xA9, 0xA9, 0xA9, 0x5D, 0x5D, 0x5D, 0x5D, 0x5D, 0x5D, 0x5D, 0x5D, 0x5D, 0x5D, 0x5D, 0x57, 0x5D, 0x56, 0x57,
		        0x5D, 0x5E, 0x5E, 0x57, 0x57, 0xA9, 0x56, 0x57, 0x5D, 0x57, 0x5D, 0x5D, 0x5D, 0x57, 0x5D, 0x5D, 0x5D, 0x5D, 0xA9, 0x5D, 0x5D, 0x5D, 0x5D, 0x5D, 0x5D, 0x5D, 0x5D, 0xA9, 0x5D, 0x5D, 0x5E, 0x5D, 0x57, 0x5D, 0x5D, 0x5D, 0x5D, 0xB0, 0xB0, 0x56, 0x56,
		        0x56, 0x56, 0x5D, 0x5D, 0x5D, 0x5D, 0x5D, 0x5D, 0xA9, 0xA9, 0x5D, 0x5D, 0x5D, 0x5D, 0x5D, 0xA9, 0x5D, 0x5D, 0xA9, 0xA9, 0xA9, 0xA9, 0xA9, 0xA9, 0xA9, 0xAA, 0xAA, 0xAA, 0xAA, 0xA9, 0xA9, 0xAA, 0xAA, 0xAA, 0xAA, 0xAA, 0xAA,
		  0xA9, 0xA9, 0xA9, 0xA9, 0xAA, 0xAA, 0xAA, 0xAA, 0xAA, 0xAA, 0xAA, 0xAA, 0xAA, 0xA9, 0xAA, 0xA9, 0xA9, 0xA9, 0xA9, 0x5D, 0x5D, 0x5D, 0x5D, 0x5D, 0x5D, 0x5D, 0x5D, 0x5D, 0x5D, 0x5D, 0x5D, 0x5D, 0x5D, 0x5D, 0x5D, 0x5D, 0x5D, 0x5D, 0x5D, 0x5D, 0x56, 0x57,
		        0x5D, 0x5E, 0xAA, 0x5D, 0x57, 0x5D, 0x5D, 0x5D, 0x57, 0x57, 0x5D, 0x57, 0x5D, 0x5D, 0x5D, 0x5D, 0x5D, 0x5D, 0x5D, 0x5D, 0x5D, 0x57, 0x57, 0x57, 0x57, 0xA9, 0x57, 0x5D, 0x5D, 0x57, 0xAA, 0x5D, 0x5D, 0xAA, 0x5D, 0x5D, 0x5D, 0xAA, 0xB0, 0x57, 0x56,
		        0x56, 0x56, 0x5D, 0x5D, 0x5D, 0x5D, 0x5D, 0x5D, 0x5D, 0x5D, 0x5D, 0x5D, 0x5D, 0x5D, 0x5D, 0x5D, 0x5D, 0x5D, 0x5D, 0x5D, 0x5D, 0x5D, 0x5D, 0xA9, 0xA9, 0xA9, 0xA9, 0xAA, 0xAA, 0xAA, 0xA9, 0xA9, 0xAA, 0xAA, 0xAA, 0xAA, 0xAA,
		  0xA9, 0xAA, 0xA9, 0xA9, 0xAA, 0xA9, 0xAA, 0xAA, 0xAA, 0xAA, 0xA9, 0xAA, 0xA9, 0xA9, 0x5D, 0x5D, 0x5D, 0x5D, 0x5D, 0x5D, 0x5D, 0x5D, 0x5D, 0x5D, 0x5D, 0x5D, 0x5D, 0x5D, 0x5D, 0x5D, 0x5D, 0xA9, 0xA9, 0x5D, 0x5D, 0x5D, 0x5D, 0x5D, 0x5D, 0x5D, 0x56, 0x5D,
		        0x5D, 0x5D, 0xAA, 0x5D, 0x5D, 0x5D, 0x56, 0x5D, 0x57, 0x5D, 0x5D, 0x5D, 0x5D, 0x5D, 0x5D, 0x5D, 0xAA, 0x5D, 0x5D, 0x5D, 0x57, 0x5D, 0x56, 0x56, 0x5D, 0x5D, 0x5D, 0x5D, 0x5D, 0x5D, 0x5D, 0x5D, 0x5D, 0x5D, 0x57, 0x5D, 0x5D, 0xB0, 0xAA, 0x57, 0x56,
		        0x56, 0x56, 0x5D, 0x5D, 0x5D, 0x5D, 0x5D, 0xA9, 0x5D, 0x5D, 0x5D, 0x5D, 0x5D, 0x5D, 0x5D, 0x5D, 0x5D, 0x5D, 0x5D, 0x5D, 0x5D, 0x5D, 0x5D, 0x5D, 0x56, 0x5D, 0x5D, 0xA9, 0xA9, 0xA9, 0xA9, 0xA9, 0xA9, 0xA9, 0xA9, 0x5D, 0x5D,
		  0xA9, 0xB0, 0xAA, 0xA9, 0xA9, 0xA9, 0xAA, 0xAA, 0xA9, 0x5D, 0x5D, 0x5D, 0x5D, 0x5D, 0x5D, 0x5D, 0x5D, 0x5D, 0x5D, 0x5D, 0x5D, 0x5D, 0x5D, 0x5D, 0x5D, 0x5D, 0x5D, 0x5D, 0x5D, 0x5D, 0x5D, 0x5D, 0x5D, 0x5D, 0x5D, 0x5D, 0x5D, 0x5D, 0x5D, 0x5D, 0x5D, 0x56,
		        0x5D, 0x5D, 0x5D, 0x5D, 0x5D, 0x5D, 0x5D, 0x5D, 0x5D, 0x5D, 0x5D, 0x5D, 0x5D, 0x5D, 0x5E, 0x5D, 0x5D, 0x5D, 0x5D, 0x5D, 0x5D, 0x5D, 0x5D, 0x5D, 0x5D, 0x5D, 0x5D, 0x5D, 0x5D, 0x5D, 0x5D, 0x5D, 0x5D, 0x5D, 0x5D, 0x5D, 0x5D, 0xAA, 0x5E, 0x57, 0x56,
		        0x56, 0x57, 0x5D, 0x5D, 0x5D, 0x5D, 0x5D, 0x5D, 0x5D, 0x5D, 0x5D, 0x5D, 0x5D, 0x5D, 0x5D, 0x5D, 0x5D, 0x5D, 0x5D, 0x5D, 0x5D, 0x5D, 0x5D, 0x5D, 0x5D, 0x5D, 0x5D, 0x5D, 0x5D, 0x5D, 0x5D, 0x5D, 0x5D, 0xAA, 0xA9, 0x5D, 0x5D,
		  0x5D, 0x5D, 0x5D, 0x5D, 0x5D, 0x5D, 0xA9, 0x5D, 0x5D, 0x57, 0x5D, 0x5D, 0x5D, 0x5D, 0x5D, 0x5D, 0x5D, 0x5D, 0x5D, 0x5D, 0x5D, 0x5D, 0x5D, 0x5D, 0x5D, 0x5D, 0x5D, 0x5D, 0x5D, 0x5D, 0x5D, 0x5D, 0x5D, 0x5D, 0x5D, 0x5D, 0x5D, 0x5D, 0x5D, 0x5D, 0x57, 0x56,
		        0x57, 0x57, 0x5D, 0x5D, 0x5D, 0x5D, 0x5D, 0x5D, 0x5D, 0x5D, 0x5D, 0x5D, 0x5D, 0x5E, 0xAA, 0x5E, 0x5E, 0x5D, 0x5D, 0x5D, 0xAA, 0x5D, 0x5D, 0x5D, 0x5D, 0x5D, 0x5D, 0x5D, 0x5D, 0x5D, 0x5D, 0x5D, 0x5D, 0x5D, 0x5D, 0x5D, 0x5D, 0x5D, 0x5D, 0x5D, 0x5D,
		        0x56, 0x5D, 0x5D, 0x5D, 0x5D, 0x5D, 0x5D, 0x5D, 0x5D, 0x5D, 0x5D, 0x5D, 0x5D, 0x5D, 0x5D, 0x5D, 0x5D, 0x5D, 0x5D, 0x5D, 0x5D, 0x5D, 0x5D, 0x5D, 0x5D, 0x5D, 0x5D, 0x5D, 0x5D, 0x5D, 0x5D, 0x5D, 0x5D, 0x5D, 0x5D, 0x5D, 0x5D,
		  0x5D, 0x5D, 0x5D, 0x5D, 0x5D, 0x57, 0x5D, 0x5D, 0x5D, 0x5D, 0x5D, 0xA9, 0x5D, 0x5D, 0x5D, 0x5D, 0x5D, 0x5D, 0x5D, 0x5D, 0x5D, 0x5D, 0x5D, 0x5D, 0x57, 0x57, 0x57, 0x57, 0x5D, 0x57, 0x57, 0x5D, 0x5D, 0x57, 0x5D, 0x5D, 0x5D, 0x57, 0x57, 0x5D, 0x5D, 0x5D,
		        0x57, 0x57, 0x5D, 0x57, 0x56, 0x56, 0x56, 0x57, 0x57, 0x56, 0x57, 0x5D, 0x57, 0x57, 0x57, 0x57, 0x57, 0x57, 0x57, 0x57, 0x56, 0x56, 0x57, 0x57, 0x56, 0x56, 0x56, 0x56, 0x56, 0x56, 0x56, 0x56, 0x56, 0x56, 0x56, 0x57, 0x56, 0x56, 0x56, 0x56, 0x57,
		        0x56, 0x57, 0x57, 0x56, 0x56, 0x56, 0x56, 0x56, 0x56, 0x5D, 0x56, 0x56, 0x56, 0x56, 0x56, 0x56, 0x56, 0x56, 0x57, 0x57, 0x57, 0x56, 0x56, 0x56, 0x56, 0x56, 0x56, 0x56, 0x56, 0x56, 0x56, 0x56, 0x56, 0x56, 0x56, 0x56, 0x56,
		  0x56, 0x56, 0x56, 0x56, 0x56, 0x32, 0x32, 0x56, 0x57, 0x57, 0x57, 0x57, 0x56, 0x57, 0x57, 0x57, 0x56, 0x57, 0x56, 0x57, 0x57, 0x57, 0x57, 0x57, 0x57, 0x57, 0x57, 0x57, 0x57, 0x57, 0x57, 0x57, 0x57, 0x57, 0x57, 0x57, 0x57, 0x57, 0x57, 0x57, 0x57, 0x57,
		        0x56, 0x32, 0x56, 0x56, 0x32, 0x57, 0x32, 0x56, 0x57, 0x57, 0x57, 0x57, 0x56, 0x57, 0x57, 0x57, 0x56, 0x32, 0x33, 0x56, 0x57, 0x57, 0x57, 0x57, 0x56, 0x57, 0x57, 0x57, 0x57, 0x57, 0x57, 0x57, 0x56, 0x57, 0x57, 0x57, 0x57, 0x56, 0x57, 0x57, 0x57,
		        0x57, 0x57, 0x57, 0x57, 0x57, 0x57, 0x56, 0x56, 0x56, 0x56, 0x56, 0x57, 0x57, 0x57, 0x57, 0x57, 0x57, 0x57, 0x57, 0x5D, 0x57, 0x57, 0x57, 0x57, 0x57, 0x5D, 0x5D, 0x5D, 0x57, 0x56, 0x57, 0x57, 0x56, 0x57, 0x56, 0x56, 0x57,
		  0x32, 0x32, 0x32, 0x32, 0x32, 0x32, 0x32, 0x32, 0x56, 0x56, 0x56, 0x56, 0x56, 0x56, 0x56, 0x56, 0x56, 0x56, 0x56, 0x56, 0x56, 0x32, 0x32, 0x56, 0x56, 0x56, 0x56, 0x56, 0x56, 0x56, 0x56, 0x56, 0x56, 0x32, 0x56, 0x56, 0x32, 0x32, 0x32, 0x32, 0x32, 0x32,
		        0x32, 0x32, 0x32, 0x32, 0x32, 0x32, 0x32, 0x32, 0x32, 0x32, 0x56, 0x32, 0x32, 0x32, 0x32, 0x32, 0x32, 0x32, 0x32, 0x32, 0x32, 0x32, 0x32, 0x32, 0x32, 0x32, 0x32, 0x32, 0x32, 0x32, 0x32, 0x32, 0x32, 0x32, 0x32, 0x32, 0x32, 0x32, 0x32, 0x32, 0x32,
		        0x32, 0x32, 0x32, 0x32, 0x32, 0x32, 0x32, 0x32, 0x32, 0x32, 0x32, 0x32, 0x32, 0x32, 0x32, 0x56, 0x56, 0x56, 0x56, 0x56, 0x56, 0x56, 0x56, 0x56, 0x56, 0x56, 0x56, 0x56, 0x56, 0x32, 0x32, 0x56, 0x32, 0x32, 0x32, 0x56, 0x32,
		  0x5D, 0x57, 0x57, 0x57, 0x57, 0x57, 0x56, 0x56, 0x57, 0x57, 0x5D, 0x5D, 0x5D, 0x5D, 0x5D, 0x5D, 0x5D, 0x5D, 0x5D, 0x5D, 0x5D, 0x5D, 0x5D, 0x5D, 0x5D, 0x5D, 0x5D, 0x5D, 0x5D, 0x5D, 0x5D, 0x5D, 0x5D, 0x5D, 0x5D, 0x5D, 0x5D, 0x5D, 0x5D, 0x5D, 0x5D, 0x5D,
		        0x5D, 0x5D, 0x5D, 0x5D, 0x57, 0x5D, 0x5D, 0x5D, 0x5D, 0x5D, 0x5D, 0x5D, 0x5D, 0x5D, 0x57, 0x57, 0x5D, 0x57, 0x5D, 0x57, 0x57, 0x57, 0x5D, 0x5D, 0x5D, 0x5D, 0x5D, 0x5D, 0x57, 0x57, 0x57, 0x5D, 0x5D, 0x5D, 0x5D, 0x5D, 0x57, 0x5D, 0x5D, 0x5D, 0x5D,
		        0x5D, 0x5D, 0x5D, 0x5D, 0x5D, 0x5D, 0x5D, 0x5D, 0x5D, 0x5D, 0x5D, 0x5D, 0x5D, 0x5D, 0x5D, 0x5D, 0x5D, 0x5D, 0x5D, 0x5D, 0x5D, 0x5D, 0x5D, 0xA9, 0xA9, 0xA9, 0xA9, 0x5D, 0x5D, 0x5D, 0x5D, 0x5D, 0xA9, 0xA9, 0x5D, 0xA9, 0xAA,
		  0x5D, 0x57, 0x57, 0x57, 0x57, 0x5D, 0x57, 0x5D, 0x5D, 0x5D, 0x5D, 0x5D, 0x5D, 0x5D, 0xA9, 0xA9, 0xA9, 0x5D, 0x5D, 0x5D, 0x5D, 0x5D, 0x5D, 0x5D, 0x5D, 0x5D, 0x5D, 0x5D, 0x5D, 0x5D, 0x5D, 0x5D, 0x5D, 0x5D, 0x5D, 0x5D, 0x5D, 0x5D, 0x5D, 0x5D, 0x5D, 0x5D,
		        0x5D, 0x5D, 0x5D, 0x5D, 0x5D, 0x5D, 0x5D, 0x5D, 0x5D, 0x5D, 0xA9, 0x5D, 0x5D, 0x5D, 0x5D, 0x5D, 0x5D, 0x5D, 0x5D, 0x5D, 0x5D, 0x5D, 0x5D, 0x5D, 0x5D, 0x5D, 0x57, 0x57, 0x5D, 0x57, 0x5D, 0x5D, 0x5D, 0x5D, 0x5D, 0x57, 0x57, 0x57, 0x5D, 0x5D, 0x5D,
		        0x5D, 0x5D, 0x5D, 0x5D, 0x5D, 0x5D, 0x5D, 0x5D, 0x5D, 0x5D, 0x5D, 0x57, 0x57, 0x57, 0x57, 0x57, 0x57, 0x57, 0x57, 0x57, 0x57, 0x57, 0x57, 0x5D, 0x5D, 0x5D, 0x5D, 0x57, 0x57, 0x57, 0x57, 0x5D, 0x5D, 0x5D, 0x5D, 0x5D, 0x5D,
		  0x2C, 0x2C, 0x32, 0x32, 0x32, 0x2C, 0x2C, 0x2C, 0x2C, 0x2C, 0x56, 0x56, 0x56, 0x2C, 0x32, 0x32, 0x32, 0x32, 0x32, 0x57, 0x57, 0x56, 0x2C, 0x32, 0x32, 0x32, 0x2C, 0x56, 0x56, 0x56, 0x2B, 0x2C, 0x2C, 0x2C, 0x2C, 0x32, 0x32, 0x32, 0x2C, 0x2C, 0x2C, 0x2C,
		        0x2C, 0x32, 0x56, 0x56, 0x32, 0x2C, 0x32, 0x32, 0x32, 0x2C, 0x57, 0x57, 0x57, 0x32, 0x32, 0x32, 0x32, 0x32, 0x56, 0x57, 0x57, 0x56, 0x2C, 0x2C, 0x2C, 0x2C, 0x2C, 0x32, 0x32, 0x32, 0x2C, 0x2C, 0x2C, 0x2C, 0x2C, 0x32, 0x32, 0x32, 0x2C, 0x2C, 0x2C,
		        0x2C, 0x2C, 0x2C, 0x32, 0x32, 0x32, 0x2B, 0x2B, 0x2B, 0x2B, 0x2B, 0x32, 0x32, 0x32, 0x2B, 0x2B, 0x2B, 0x2B, 0x07, 0x2C, 0x32, 0x32, 0x2C, 0x2B, 0x2B, 0x2B, 0x2B, 0x2C, 0x32, 0x32, 0x32, 0x2B, 0x2B, 0x2B, 0x2B, 0x2B, 0x32,
		  0x2B, 0x2B, 0x07, 0x07, 0x07, 0x07, 0x2B, 0x2B, 0x2B, 0x2B, 0x2B, 0x2B, 0x07, 0x2B, 0x2B, 0x2B, 0x2B, 0x2B, 0x2B, 0x2B, 0x2B, 0x2B, 0x2B, 0x2B, 0x2B, 0x2B, 0x2B, 0x07, 0x07, 0x07, 0x07, 0x07, 0x07, 0x07, 0x07, 0x07, 0x07, 0x07, 0x07, 0x07, 0x07, 0x07,
		        0x07, 0x07, 0x07, 0x07, 0x07, 0x07, 0x07, 0x07, 0x07, 0x07, 0x07, 0x07, 0x07, 0x07, 0x07, 0x07, 0x07, 0x07, 0x07, 0x07, 0x07, 0x07, 0x07, 0x07, 0x07, 0x07, 0x07, 0x07, 0x07, 0x07, 0x2B, 0x07, 0x07, 0x2B, 0x07, 0x2B, 0x07, 0x07, 0x07, 0x2B, 0x2B,
		        0x2B, 0x2B, 0x2B, 0x2B, 0x2B, 0x07, 0x07, 0x07, 0x07, 0x2B, 0x07, 0x07, 0x07, 0x07, 0x2B, 0x2B, 0x2B, 0x2B, 0x2B, 0x07, 0x07, 0x07, 0x07, 0x2B, 0x2B, 0x2B, 0x07, 0x2B, 0x07, 0x07, 0x2B, 0x2B, 0x2B, 0x2B, 0x07, 0x2B, 0x2B,
		  0x2C, 0x2B, 0x2C, 0x2C, 0x2B, 0x2B, 0x32, 0x32, 0x32, 0x32, 0x32, 0x2C, 0x2C, 0x2C, 0x2C, 0x32, 0x2C, 0x32, 0x32, 0x32, 0x32, 0x2C, 0x2C, 0x2C, 0x2B, 0x2B, 0x2C, 0x2C, 0x2C, 0x2C, 0x2C, 0x2C, 0x2C, 0x2C, 0x2C, 0x2C, 0x2C, 0x2C, 0x2C, 0x2C, 0x2C, 0x2B,
		        0x2C, 0x2C, 0x2C, 0x2C, 0x2C, 0x2B, 0x2B, 0x2B, 0x2B, 0x2B, 0x2C, 0x2C, 0x2C, 0x2C, 0x32, 0x2C, 0x2C, 0x2C, 0x2C, 0x2C, 0x2C, 0x2B, 0x2C, 0x2B, 0x2C, 0x2C, 0x2C, 0x2C, 0x2C, 0x2C, 0x2C, 0x2B, 0x2B, 0x2C, 0x2C, 0x32, 0x32, 0x32, 0x2C, 0x32, 0x2C,
		        0x2C, 0x2C, 0x2C, 0x32, 0x32, 0x2B, 0x2C, 0x2C, 0x2C, 0x2C, 0x2C, 0x2C, 0x2C, 0x2C, 0x2C, 0x32, 0x2C, 0x32, 0x2C, 0x2C, 0x2C, 0x2C, 0x2C, 0x2C, 0x2C, 0x32, 0x2C, 0x2C, 0x2C, 0x2C, 0x2C, 0x2C, 0x32, 0x32, 0x32, 0x32, 0x2C,
		  0x56, 0x56, 0x5D, 0x5D, 0x57, 0x57, 0x57, 0x5D, 0x5D, 0x5D, 0x5D, 0x5D, 0x57, 0x57, 0x57, 0xA9, 0x5D, 0xA9, 0x5D, 0xA9, 0x5D, 0x57, 0x56, 0x57, 0x5D, 0x57, 0x57, 0x5D, 0x57, 0x57, 0x57, 0x57, 0x5D, 0x56, 0x5D, 0x5D, 0x5D, 0x57, 0x57, 0x56, 0x5D, 0x57,
		        0x57, 0x5D, 0x5D, 0x57, 0x57, 0x56, 0x57, 0x57, 0x56, 0x56, 0x5D, 0x57, 0x57, 0x56, 0x57, 0x5D, 0x5D, 0x57, 0x5D, 0x57, 0x57, 0x32, 0x56, 0x5D, 0x57, 0x5D, 0x5D, 0x57, 0x57, 0x57, 0x56, 0x5D, 0x5D, 0x57, 0x5D, 0xA9, 0x5D, 0x5D, 0x57, 0x5D, 0x57,
		        0x57, 0x5D, 0x5D, 0x5D, 0xA9, 0x56, 0x56, 0x5D, 0x57, 0x5D, 0x5D, 0x5D, 0x5D, 0x57, 0x5D, 0x5D, 0x5D, 0x5D, 0x5D, 0x5D, 0x5D, 0x5D, 0x57, 0x5D, 0x5D, 0x5D, 0x57, 0x5D, 0x5D, 0x5D, 0x57, 0x57, 0x57, 0x5D, 0x5D, 0xA9, 0x5D,
		  0xA9, 0x57, 0xAA, 0x5D, 0x5D, 0x5D, 0xB0, 0xA9, 0xA9, 0xA9, 0xB0, 0x5D, 0x5D, 0x5D, 0xAA, 0xA9, 0xA9, 0xA9, 0xA9, 0xAA, 0xAA, 0xA9, 0x5D, 0xAA, 0xA9, 0x5D, 0x5D, 0xAA, 0x5D, 0x5D, 0x5D, 0xAA, 0x57, 0x57, 0xA9, 0xAA, 0xA9, 0xA9, 0xA9, 0xAA, 0x5D, 0x57,
		        0x5D, 0xAA, 0x5D, 0xA9, 0x5D, 0xA9, 0xA9, 0x5D, 0x5D, 0xA9, 0xAA, 0xAA, 0xAA, 0xA9, 0xAA, 0x5D, 0x56, 0x5D, 0xAA, 0xA9, 0xA9, 0xA9, 0xA9, 0x5D, 0xAA, 0x5D, 0xAA, 0xA9, 0x5D, 0x5D, 0xAA, 0xA9, 0x5D, 0x5D, 0xAA, 0xAA, 0xA9, 0xAA, 0xAA, 0x5D, 0x5D,
		        0xA9, 0xAA, 0xA9, 0xA9, 0xAA, 0xA9, 0xA9, 0x5D, 0x5D, 0xAA, 0x5E, 0x5E, 0xAA, 0xA9, 0xAA, 0x5D, 0x57, 0x5D, 0xAA, 0x5E, 0x5D, 0xA9, 0x5D, 0x57, 0x57, 0x57, 0x5E, 0x5D, 0x5D, 0x5D, 0x5D, 0x5D, 0x5D, 0x5D, 0xAA, 0xAA, 0xAA,
		  0x5D, 0xA9, 0xAA, 0xA9, 0x5D, 0x5D, 0xAA, 0x5D, 0xA9, 0x5D, 0xAA, 0x5D, 0x5D, 0x5D, 0xAA, 0xAA, 0xA9, 0xA9, 0xA9, 0xAA, 0xAA, 0xA9, 0xA9, 0x5D, 0x57, 0x56, 0x5D, 0xAA, 0x5D, 0x5D, 0x5D, 0xA9, 0xA9, 0x5D, 0x5D, 0xAA, 0xA9, 0xA9, 0xA9, 0xAA, 0x5D, 0x5D,
		        0x5D, 0xAA, 0x5E, 0xAA, 0xA9, 0xA9, 0x5D, 0x5D, 0x57, 0x5D, 0xAA, 0xAA, 0xA9, 0xA9, 0x5D, 0x5D, 0xA9, 0xAA, 0xAA, 0xA9, 0xA9, 0xA9, 0xAA, 0x5D, 0x5D, 0x5D, 0xAA, 0x5D, 0x5D, 0xA9, 0xAA, 0xA9, 0xAA, 0xA9, 0xAA, 0xAA, 0x5D, 0xAA, 0xAA, 0xA9, 0x5D,
		        0xA9, 0xAA, 0xA9, 0xA9, 0xA9, 0xA9, 0xAA, 0xAA, 0xA9, 0xAA, 0xAA, 0xAA, 0xAA, 0xAA, 0xA9, 0x5D, 0xA9, 0xA9, 0xAA, 0x5E, 0x5D, 0x5D, 0x5D, 0x5E, 0xAA, 0x5D, 0x5E, 0x5E, 0x5E, 0x5E, 0xAA, 0xAA, 0x5D, 0xAA, 0xAA, 0x5E, 0x5E,
		  0xA9, 0xA9, 0xA9, 0x5D, 0x5D, 0xA9, 0xAA, 0xA9, 0xA9, 0xA9, 0xA9, 0x5D, 0x5D, 0x5D, 0xA9, 0xA9, 0x5D, 0x5D, 0xA9, 0x5D, 0x5D, 0x5D, 0x5D, 0x5D, 0x5D, 0x5D, 0x5D, 0x5D, 0x5D, 0x5D, 0x5D, 0x5D, 0x5D, 0x5D, 0x5D, 0x5D, 0x5D, 0xA9, 0xA9, 0x5D, 0x5D, 0xA9,
		        0xA9, 0x5D, 0x5D, 0xA9, 0x5D, 0xA9, 0xA9, 0xA9, 0xA9, 0xAA, 0x5D, 0x5D, 0x5D, 0xAA, 0xAA, 0xAA, 0xAA, 0xAA, 0xAA, 0x5D, 0x5D, 0x5D, 0xAA, 0x5E, 0x5D, 0xAA, 0x5E, 0x5D, 0x5D, 0x5D, 0x5D, 0x5D, 0x5D, 0x5D, 0x5D, 0x5D, 0x5D, 0x5D, 0x5D, 0x5D, 0x5D,
		        0x5D, 0x5D, 0x5D, 0xA9, 0xA9, 0xA9, 0x5D, 0x5D, 0x5D, 0x5D, 0xA9, 0xA9, 0xA9, 0x5D, 0x5D, 0x5D, 0x5D, 0x5D, 0x5D, 0x5D, 0x5D, 0x5D, 0x5D, 0x5D, 0x5D, 0x5D, 0x5D, 0x5D, 0x5D, 0x5D, 0x5D, 0x57, 0x57, 0x57, 0x57, 0x5D, 0x5D,
		  0x57, 0x5D, 0x5D, 0x57, 0x5D, 0x5D, 0x5D, 0x5D, 0x5D, 0x5D, 0x5D, 0x5D, 0x5D, 0x5D, 0x5D, 0x5D, 0x5D, 0x5D, 0x5D, 0x5D, 0x5D, 0x5D, 0x5D, 0x5D, 0x5D, 0x5D, 0x5D, 0x5D, 0x5D, 0x5D, 0x5D, 0x5D, 0xA9, 0xA9, 0xA9, 0x5D, 0x5D, 0x57, 0x5D, 0x5D, 0x5D, 0x5D,
		        0x5D, 0x5D, 0x5D, 0x5D, 0x5D, 0x5D, 0x5D, 0x57, 0x57, 0x57, 0x57, 0x57, 0x57, 0x57, 0x5D, 0x5D, 0x57, 0x57, 0x57, 0x57, 0x57, 0x57, 0x57, 0x57, 0x57, 0x57, 0x5D, 0x5D, 0x5D, 0x57, 0x5D, 0x5D, 0x5D, 0x5D, 0x57, 0x57, 0x5D, 0x57, 0x5D, 0x5D, 0x5D,
		        0x5D, 0x5D, 0xA9, 0xA9, 0x5D, 0xA9, 0xA9, 0xA9, 0xA9, 0xA9, 0xA9, 0x5D, 0x5D, 0x5D, 0x5D, 0x5D, 0x5D, 0xA9, 0xA9, 0xA9, 0x5D, 0x5D, 0x5D, 0x5D, 0x5D, 0x5D, 0x5D, 0x5D, 0x5D, 0x5D, 0xA9, 0xA9, 0xAA, 0xAA, 0xAA, 0x5D, 0x5D,
		  0x5D, 0xAA, 0xAA, 0xAA, 0xAA, 0xAA, 0xAA, 0x5E, 0xAA, 0xAA, 0xAA, 0xAA, 0xAA, 0xAA, 0xAA, 0xAA, 0xAA, 0xAA, 0xAA, 0xAA, 0xAA, 0xAA, 0xAA, 0xAA, 0xAA, 0xAA, 0xAA, 0xAA, 0xAA, 0xAA, 0xAA, 0xAA, 0xAA, 0xAA, 0xAA, 0xAA, 0xAA, 0x5E, 0xAA, 0xAA, 0x5E, 0xAA,
		        0xAA, 0xAA, 0xAA, 0xAA, 0xAA, 0xAA, 0xB0, 0x5D, 0x5E, 0x5E, 0x5E, 0xAA, 0xB0, 0xAA, 0xAA, 0xAA, 0xAA, 0xAA, 0xAA, 0xAA, 0xAA, 0xAA, 0x5E, 0x5E, 0x5E, 0xAA, 0xAA, 0xAA, 0xAA, 0xAA, 0xAA, 0xAA, 0xAA, 0xAA, 0x5E, 0x5E, 0xAA, 0xAA, 0xAA, 0xAA, 0xAA,
		        0xAA, 0xAA, 0xAA, 0xB0, 0xAA, 0xAA, 0xAA, 0xAA, 0xAA, 0xAA, 0xAA, 0xAA, 0xAA, 0xAA, 0xAA, 0xAA, 0xAA, 0xAA, 0xAA, 0xAA, 0xAA, 0xAA, 0xAA, 0x5E, 0x5D, 0x5E, 0x5E, 0x5E, 0x5E, 0xAA, 0xAA, 0xAA, 0xAA, 0xAA, 0xAA, 0xAA, 0xAA,
		  0x5D, 0x5E, 0xAA, 0xAA, 0xAA, 0xAA, 0xAA, 0x5E, 0xAA, 0x5E, 0x5E, 0xAA, 0xAA, 0xAA, 0xAA, 0x5E, 0xA9, 0x5D, 0xAA, 0xAA, 0xAA, 0xAA, 0xAA, 0xAA, 0xAA, 0xA9, 0xAA, 0xAA, 0xAA, 0xAA, 0xAA, 0xAA, 0xAA, 0xAA, 0xAA, 0xAA, 0xAA, 0x5E, 0xAA, 0xAA, 0x5E, 0xAA,
		        0xAA, 0xAA, 0xAA, 0xAA, 0xAA, 0xAA, 0xAA, 0x5D, 0x5E, 0x5E, 0x5E, 0xAA, 0xAA, 0xAA, 0xAA, 0xB0, 0xAA, 0xAA, 0xAA, 0xAA, 0xA9, 0xAA, 0x5E, 0x5E, 0x5E, 0xAA, 0xAA, 0xAA, 0xAA, 0xAA, 0xAA, 0xAA, 0x5E, 0x5E, 0x5E, 0x5E, 0x5E, 0x5E, 0xAA, 0xAA, 0xA9,
		        0xAA, 0xAA, 0xB0, 0xB0, 0xAA, 0xAA, 0xAA, 0xAA, 0xAA, 0xAA, 0xAA, 0xAA, 0xAA, 0xAA, 0xB0, 0xAA, 0xAA, 0xAA, 0xAA, 0xAA, 0xAA, 0xAA, 0xAA, 0x5E, 0x5D, 0x5E, 0x5E, 0x5E, 0x5E, 0xAA, 0xAA, 0xAA, 0xAA, 0xAA, 0xAA, 0xAA, 0xAA,
		  0x56, 0x57, 0x57, 0x57, 0x57, 0x57, 0x57, 0x57, 0x57, 0x57, 0x57, 0x57, 0x57, 0x57, 0x57, 0x57, 0x57, 0x5D, 0x5D, 0x5D, 0x5D, 0x5D, 0x5D, 0x5D, 0x57, 0x57, 0x57, 0x57, 0x57, 0x57, 0x57, 0x57, 0x57, 0x5D, 0x5D, 0x57, 0x57, 0x57, 0x57, 0x5D, 0x5D, 0x5D,
		        0x5D, 0x5D, 0x5D, 0x5D, 0x5D, 0x5D, 0x5D, 0x57, 0x57, 0x57, 0x57, 0x5D, 0x5D, 0x5D, 0x5D, 0x5D, 0x5D, 0x5D, 0x5D, 0x5D, 0x57, 0x5D, 0x5D, 0x5D, 0x5D, 0x5D, 0x5D, 0x5D, 0x5D, 0x5D, 0x5D, 0x5D, 0x5D, 0x5D, 0x5D, 0x5D, 0x5D, 0x5D, 0x5D, 0x5D, 0x57,
		        0x56, 0x57, 0x57, 0x57, 0x57, 0x57, 0x57, 0x57, 0x57, 0x57, 0x57, 0x57, 0x57, 0x57, 0x57, 0x57, 0x5D, 0x5D, 0x5D, 0x5D, 0x5D, 0xA9, 0x5D, 0x5D, 0x5D, 0x56, 0x57, 0x57, 0x57, 0x57, 0x57, 0x57, 0x57, 0x57, 0x57, 0x57, 0x57,
		  0x2B, 0x07, 0x07, 0x07, 0x07, 0x07, 0x07, 0x2B, 0x2B, 0x2B, 0x2B, 0x2B, 0x07, 0x07, 0x07, 0x07, 0x2C, 0x2C, 0x2C, 0x57, 0x57, 0x57, 0x32, 0x2C, 0x2C, 0x07, 0x07, 0x07, 0x07, 0x07, 0x07, 0x07, 0x2B, 0x2B, 0x2B, 0x2B, 0x2B, 0x07, 0x2B, 0x2B, 0x2B, 0x32,
		        0x2C, 0x32, 0x5D, 0x5D, 0x57, 0x32, 0x2C, 0x2C, 0x07, 0x2B, 0x2B, 0x2B, 0x2B, 0x2B, 0x2B, 0x2B, 0x2B, 0x2C, 0x2B, 0x2B, 0x2B, 0x2B, 0x2B, 0x2B, 0x2B, 0x2B, 0x2B, 0x2B, 0x2B, 0x2B, 0x2B, 0x2B, 0x32, 0x2C, 0x56, 0x5D, 0x5D, 0x56, 0x2C, 0x2C, 0x2C,
		        0x2B, 0x2B, 0x2B, 0x2B, 0x2B, 0x2B, 0x2B, 0x2B, 0x2B, 0x2B, 0x2B, 0x2B, 0x2B, 0x2B, 0x07, 0x2C, 0x32, 0x2C, 0x56, 0x5D, 0x5D, 0x57, 0x32, 0x2C, 0x2C, 0x2B, 0x2B, 0x2B, 0x2B, 0x2B, 0x2B, 0x2B, 0x2B, 0x2B, 0x2B, 0x2B, 0x2B,
		  0x2B, 0x07, 0x07, 0x07, 0x07, 0x07, 0x07, 0x07, 0x07, 0x07, 0x07, 0x2B, 0x07, 0x2B, 0x2B, 0x07, 0x07, 0x2B, 0x2C, 0x32, 0x32, 0x2C, 0x2C, 0x2C, 0x2B, 0x07, 0x07, 0x01, 0x07, 0x2B, 0x07, 0x07, 0x2B, 0x2B, 0x2B, 0x2B, 0x2B, 0x07, 0x2B, 0x07, 0x07, 0x2B,
		        0x2C, 0x32, 0x32, 0x32, 0x2C, 0x2C, 0x2C, 0x2B, 0x07, 0x2B, 0x2B, 0x2B, 0x2B, 0x2B, 0x2B, 0x2B, 0x2C, 0x2C, 0x2B, 0x2B, 0x2B, 0x2B, 0x2B, 0x2B, 0x2B, 0x2B, 0x2B, 0x2B, 0x2B, 0x2B, 0x07, 0x07, 0x2B, 0x2C, 0x32, 0x32, 0x32, 0x32, 0x2C, 0x2B, 0x07,
		        0x2B, 0x2B, 0x2B, 0x2B, 0x2B, 0x2B, 0x2B, 0x2B, 0x2B, 0x2B, 0x2B, 0x2B, 0x07, 0x07, 0x07, 0x2B, 0x2C, 0x2C, 0x32, 0x32, 0x32, 0x32, 0x2C, 0x2B, 0x2B, 0x2B, 0x2B, 0x2B, 0x2B, 0x2B, 0x2B, 0x07, 0x07, 0x2B, 0x07, 0x07, 0x07,
		  0x2B, 0x2B, 0x07, 0x07, 0x07, 0x01, 0x01, 0x01, 0x2B, 0x07, 0x2B, 0x2B, 0x2B, 0x2B, 0x2B, 0x2B, 0x2B, 0x07, 0x2C, 0x5D, 0x5D, 0x5D, 0x57, 0x2C, 0x2B, 0x07, 0x07, 0x07, 0x01, 0x07, 0x2B, 0x07, 0x2B, 0x2B, 0x2B, 0x2B, 0x2B, 0x2B, 0x2B, 0x2B, 0x2B, 0x07,
		        0x2B, 0x57, 0xA9, 0x5D, 0x5D, 0x32, 0x2B, 0x2B, 0x07, 0x07, 0x2B, 0x2B, 0x2B, 0x2B, 0x2C, 0x2C, 0x2C, 0x2C, 0x2C, 0x2C, 0x2C, 0x2C, 0x2C, 0x2C, 0x2C, 0x2B, 0x2B, 0x2B, 0x2B, 0x2B, 0x07, 0x07, 0x2B, 0x2C, 0x5D, 0x5D, 0x5D, 0x57, 0x32, 0x07, 0x07,
		        0x2B, 0x2B, 0x2B, 0x2B, 0x2B, 0x2B, 0x2B, 0x2B, 0x2B, 0x07, 0x07, 0x01, 0x01, 0x07, 0x07, 0x2B, 0x2C, 0x57, 0x5D, 0x5D, 0x5D, 0x5D, 0x2C, 0x2B, 0x2B, 0x2B, 0x2B, 0x2B, 0x2B, 0x2B, 0x2B, 0x07, 0x07, 0x01, 0x01, 0x01, 0x07,
		  0x2B, 0x07, 0x07, 0x07, 0x2B, 0x07, 0x01, 0x01, 0x01, 0x07, 0x07, 0x07, 0x07, 0x07, 0x2B, 0x2B, 0x07, 0x07, 0x32, 0x5E, 0x5E, 0x5D, 0x5D, 0x57, 0x2C, 0x07, 0x07, 0x07, 0x01, 0x01, 0x07, 0x07, 0x07, 0x07, 0x2B, 0x2B, 0x2B, 0x2B, 0x2B, 0x07, 0x07, 0x07,
		        0x2C, 0xA9, 0xAA, 0xA9, 0xA9, 0x5D, 0x2C, 0x07, 0x07, 0x07, 0x2B, 0x2B, 0x2B, 0x2B, 0x2B, 0x2B, 0x2B, 0x2B, 0x2B, 0x2B, 0x2C, 0x2C, 0x2C, 0x2B, 0x2B, 0x2B, 0x2B, 0x2B, 0x2B, 0x2B, 0x07, 0x07, 0x2B, 0x5D, 0xAA, 0xAA, 0x5D, 0x5D, 0x5D, 0x07, 0x07,
		        0x07, 0x2B, 0x2B, 0x2B, 0x2B, 0x2B, 0x2B, 0x07, 0x07, 0x07, 0x07, 0x01, 0x01, 0x07, 0x07, 0x07, 0x32, 0x5D, 0x5D, 0x5D, 0x5D, 0xA9, 0x32, 0x2B, 0x2B, 0x2B, 0x2B, 0x2B, 0x07, 0x07, 0x07, 0x07, 0x01, 0x01, 0x01, 0x07, 0x07,
		  0x2B, 0x07, 0x2B, 0x2B, 0x2B, 0x07, 0x07, 0x01, 0x00, 0x01, 0x07, 0x07, 0x07, 0x07, 0x07, 0x07, 0x07, 0x07, 0x57, 0xAA, 0xAA, 0x5D, 0x5D, 0x57, 0x2C, 0x2B, 0x2B, 0x07, 0x07, 0x01, 0x01, 0x07, 0x07, 0x07, 0x07, 0x07, 0x07, 0x07, 0x07, 0x07, 0x07, 0x07,
		        0x32, 0xA9, 0xA9, 0xA9, 0x5D, 0x5D, 0x32, 0x2B, 0x2B, 0x01, 0x2B, 0x2B, 0x2B, 0x2B, 0x2B, 0x2B, 0x2B, 0x2B, 0x2B, 0x2B, 0x2B, 0x2B, 0x2B, 0x2B, 0x2B, 0x2B, 0x2B, 0x2B, 0x07, 0x2B, 0x01, 0x2B, 0x2C, 0x5D, 0xAA, 0x5E, 0x5D, 0x5D, 0x5D, 0x2B, 0x07,
		        0x07, 0x07, 0x07, 0x07, 0x07, 0x07, 0x07, 0x07, 0x07, 0x07, 0x01, 0x01, 0x07, 0x07, 0x2C, 0x2B, 0x5D, 0x5D, 0xA9, 0xA9, 0xA9, 0xA9, 0x32, 0x07, 0x07, 0x07, 0x07, 0x07, 0x07, 0x07, 0x07, 0x01, 0x00, 0x01, 0x07, 0x07, 0x07,
		  0x2B, 0x2B, 0x2B, 0x2C, 0x2B, 0x07, 0x07, 0x07, 0x01, 0x01, 0x01, 0x07, 0x07, 0x07, 0x07, 0x07, 0x07, 0x07, 0x57, 0xA9, 0xAA, 0x5D, 0x5D, 0x57, 0x32, 0x2B, 0x2C, 0x2B, 0x07, 0x07, 0x01, 0x01, 0x07, 0x07, 0x07, 0x07, 0x07, 0x07, 0x07, 0x07, 0x07, 0x07,
		        0x32, 0xAA, 0xA9, 0xA9, 0xA9, 0x5D, 0x32, 0x2B, 0x2B, 0x01, 0x2B, 0x07, 0x2B, 0x2B, 0x2B, 0x2B, 0x2B, 0x2B, 0x2B, 0x2B, 0x2B, 0x2B, 0x2B, 0x2B, 0x2B, 0x2B, 0x2B, 0x2B, 0x07, 0x2B, 0x01, 0x2C, 0x32, 0xAA, 0xAA, 0x5E, 0x5D, 0x5D, 0x5D, 0x2B, 0x07,
		        0x07, 0x07, 0x07, 0x07, 0x07, 0x07, 0x07, 0x07, 0x07, 0x01, 0x01, 0x01, 0x07, 0x2B, 0x32, 0x2C, 0x5D, 0x5D, 0x5D, 0x5D, 0x5D, 0x5D, 0x56, 0x07, 0x07, 0x07, 0x07, 0x07, 0x07, 0x07, 0x01, 0x01, 0x01, 0x07, 0x07, 0x07, 0x2B,
		  0x2B, 0x2B, 0x2C, 0x2C, 0x2C, 0x2B, 0x07, 0x07, 0x07, 0x01, 0x01, 0x01, 0x01, 0x07, 0x07, 0x07, 0x07, 0x07, 0x57, 0xA9, 0xA9, 0xA9, 0x5D, 0x57, 0x32, 0x2B, 0x2C, 0x2C, 0x07, 0x07, 0x01, 0x01, 0x01, 0x07, 0x07, 0x07, 0x07, 0x07, 0x07, 0x07, 0x07, 0x07,
		        0x32, 0xAA, 0xA9, 0xA9, 0x5D, 0x57, 0x56, 0x2C, 0x2C, 0x07, 0x07, 0x07, 0x07, 0x2B, 0x2B, 0x2B, 0x2B, 0x2B, 0x2B, 0x2B, 0x2B, 0x2B, 0x2B, 0x2B, 0x2B, 0x2B, 0x2B, 0x07, 0x07, 0x07, 0x07, 0x2C, 0x32, 0x5D, 0x5D, 0x5D, 0x5D, 0x5D, 0x5D, 0x2B, 0x07,
		        0x07, 0x07, 0x07, 0x07, 0x07, 0x07, 0x07, 0x01, 0x01, 0x01, 0x01, 0x07, 0x07, 0x2C, 0x32, 0x32, 0x5D, 0x5D, 0x5D, 0x5D, 0x5D, 0x5D, 0x56, 0x07, 0x07, 0x07, 0x07, 0x07, 0x01, 0x00, 0x00, 0x01, 0x07, 0x07, 0x07, 0x2B, 0x2B,
		  0x2B, 0x2C, 0x2C, 0x32, 0x2C, 0x2C, 0x2B, 0x07, 0x07, 0x07, 0x01, 0x00, 0x00, 0x00, 0x00, 0x00, 0x00, 0x01, 0x57, 0xA9, 0xA9, 0xA9, 0x5D, 0x57, 0x32, 0x2C, 0x2C, 0x2C, 0x07, 0x07, 0x07, 0x01, 0x00, 0x00, 0x01, 0x01, 0x01, 0x01, 0x01, 0x01, 0x01, 0x01,
		        0x32, 0xA9, 0xA9, 0xA9, 0x5D, 0x5D, 0x56, 0x2C, 0x2C, 0x07, 0x01, 0x01, 0x01, 0x01, 0x01, 0x01, 0x01, 0x01, 0x01, 0x01, 0x01, 0x01, 0x01, 0x01, 0x01, 0x01, 0x01, 0x01, 0x01, 0x01, 0x07, 0x32, 0x57, 0x5D, 0x5D, 0x5D, 0x5D, 0x57, 0x57, 0x07, 0x01,
		        0x01, 0x01, 0x01, 0x01, 0x01, 0x01, 0x01, 0x00, 0x00, 0x01, 0x07, 0x07, 0x2B, 0x2C, 0x57, 0x32, 0x5D, 0x5D, 0x5D, 0x5D, 0xA9, 0x5D, 0x56, 0x01, 0x01, 0x00, 0x00, 0x00, 0x00, 0x00, 0x01, 0x07, 0x07, 0x07, 0x07, 0x2B, 0x2C,
		  0x2B, 0x2C, 0x2C, 0x32, 0x2C, 0x2C, 0x2B, 0x07, 0x07, 0x07, 0x07, 0x01, 0x00, 0x00, 0x01, 0x01, 0x01, 0x01, 0x5D, 0xA9, 0xA9, 0x5D, 0x5D, 0x57, 0x32, 0x2C, 0x32, 0x2C, 0x2B, 0x07, 0x07, 0x01, 0x00, 0x01, 0x01, 0x01, 0x01, 0x01, 0x01, 0x01, 0x01, 0x01,
		        0x32, 0xA9, 0xA9, 0x5D, 0x5D, 0x5D, 0x56, 0x2C, 0x2C, 0x07, 0x01, 0x01, 0x01, 0x01, 0x01, 0x01, 0x01, 0x01, 0x01, 0x01, 0x01, 0x01, 0x01, 0x01, 0x01, 0x01, 0x01, 0x01, 0x01, 0x01, 0x2B, 0x32, 0x5D, 0x5D, 0x5D, 0x5D, 0x57, 0x57, 0x57, 0x07, 0x01,
		        0x01, 0x01, 0x01, 0x01, 0x01, 0x01, 0x01, 0x00, 0x00, 0x01, 0x07, 0x07, 0x2B, 0x2C, 0x5D, 0x5D, 0x57, 0xAA, 0x5D, 0x5D, 0xA9, 0x5D, 0x56, 0x01, 0x01, 0x01, 0x01, 0x00, 0x00, 0x01, 0x07, 0x07, 0x07, 0x07, 0x2B, 0x2C, 0x2C,
		  0x2B, 0x2C, 0x32, 0x32, 0x2C, 0x2C, 0x2C, 0x07, 0x07, 0x07, 0x07, 0x07, 0x00, 0x01, 0x01, 0x01, 0x01, 0x01, 0x5D, 0xAA, 0xA9, 0x5D, 0x5D, 0x57, 0x32, 0x2C, 0x32, 0x2C, 0x2C, 0x07, 0x07, 0x07, 0x01, 0x01, 0x01, 0x07, 0x07, 0x01, 0x01, 0x01, 0x01, 0x01,
		        0x56, 0xA9, 0x5D, 0x5D, 0x5D, 0x57, 0x32, 0x2C, 0x2C, 0x07, 0x01, 0x01, 0x01, 0x01, 0x07, 0x07, 0x07, 0x07, 0x07, 0x07, 0x07, 0x07, 0x07, 0x07, 0x07, 0x07, 0x01, 0x01, 0x01, 0x01, 0x07, 0x5D, 0xAA, 0x5D, 0x5D, 0x5D, 0x5D, 0x57, 0x57, 0x2B, 0x01,
		        0x01, 0x01, 0x01, 0x01, 0x01, 0x01, 0x01, 0x01, 0x01, 0x07, 0x07, 0x07, 0x2C, 0x32, 0xB0, 0xB0, 0x5D, 0x5D, 0xAA, 0x5E, 0x5D, 0x5D, 0x56, 0x01, 0x01, 0x01, 0x01, 0x01, 0x00, 0x01, 0x07, 0x07, 0x07, 0x07, 0x2B, 0x2C, 0x2C,
		  0x2B, 0x2C, 0x32, 0x32, 0x2C, 0x2C, 0x2C, 0x07, 0x01, 0x07, 0x07, 0x07, 0x01, 0x01, 0x2B, 0x2B, 0x2B, 0x2B, 0x5D, 0x5D, 0x5D, 0x5D, 0x5D, 0x57, 0x32, 0x2C, 0x32, 0x2C, 0x2C, 0x01, 0x07, 0x07, 0x01, 0x2B, 0x2B, 0x2B, 0x2B, 0x2B, 0x2B, 0x2B, 0x2B, 0x2B,
		        0x56, 0xA9, 0x5D, 0x5D, 0x57, 0x57, 0x32, 0x32, 0x2C, 0x07, 0x01, 0x01, 0x07, 0x07, 0x07, 0x07, 0x2B, 0x2B, 0x2B, 0x2B, 0x2B, 0x2B, 0x2B, 0x2B, 0x2B, 0x01, 0x01, 0x01, 0x01, 0x01, 0x07, 0x5D, 0xAA, 0xA9, 0xA9, 0xA9, 0xA9, 0x5D, 0x57, 0x2B, 0x01,
		        0x2B, 0x2B, 0x2B, 0x2B, 0x2B, 0x2B, 0x2B, 0x01, 0x01, 0x07, 0x07, 0x07, 0x2C, 0x57, 0xB0, 0xB0, 0x5D, 0x5E, 0x5E, 0xAA, 0x5D, 0x5D, 0x56, 0x2B, 0x2B, 0x2B, 0x2B, 0x00, 0x01, 0x01, 0x07, 0x07, 0x07, 0x01, 0x2B, 0x2C, 0x32,
		  0x2B, 0x2C, 0x32, 0x56, 0x32, 0x2C, 0x2C, 0x07, 0x01, 0x07, 0x07, 0x07, 0x01, 0x2B, 0x56, 0xCD, 0xCD, 0xCD, 0xA9, 0xA9, 0x5D, 0x5D, 0x5D, 0x57, 0x32, 0x2C, 0x32, 0x2C, 0x2C, 0x01, 0x07, 0x07, 0x2B, 0x56, 0xCD, 0xCD, 0xCD, 0xCD, 0xCD, 0xCD, 0xCD, 0xCD,
		        0xA9, 0xA9, 0xA9, 0xA9, 0x5D, 0x57, 0x32, 0x32, 0x2C, 0x07, 0x56, 0xCD, 0xCD, 0xCD, 0xCD, 0xCD, 0xCD, 0xCD, 0xCD, 0xCD, 0xCD, 0xCD, 0xCD, 0xCD, 0xCD, 0xCD, 0xCD, 0xCD, 0xCD, 0x2B, 0x07, 0xAA, 0xAA, 0xA9, 0x5D, 0xA9, 0x5D, 0x5D, 0x57, 0xA8, 0xCD,
		        0xCD, 0xCD, 0xCD, 0xCD, 0xCD, 0xCD, 0xCD, 0x56, 0x01, 0x07, 0x07, 0x07, 0x2C, 0x5D, 0xB0, 0xB0, 0x5D, 0x5E, 0x5E, 0xAA, 0xA9, 0x5D, 0xA9, 0xCD, 0xCD, 0xCD, 0xA9, 0x07, 0x01, 0x07, 0x07, 0x07, 0x01, 0x01, 0x2B, 0x2C, 0x56,
		  0x2B, 0x2C, 0x32, 0x56, 0x32, 0x2C, 0x2C, 0x01, 0x01, 0x07, 0x2B, 0x2B, 0x2B, 0xCD, 0xCD, 0xCD, 0xCD, 0xCD, 0xA9, 0xAA, 0xA9, 0x5D, 0x5D, 0x57, 0x56, 0x2C, 0x32, 0x32, 0x2C, 0x01, 0x07, 0x2B, 0xA9, 0xCD, 0xCD, 0xCD, 0xCD, 0xCD, 0xCD, 0xCD, 0xCD, 0xCD,
		        0xA9, 0xA9, 0xA9, 0xA9, 0x5D, 0x57, 0x32, 0x32, 0x2C, 0x2B, 0xCD, 0xCD, 0xCD, 0xCD, 0xCD, 0xCD, 0xCD, 0xCD, 0xCD, 0xCD, 0xCD, 0xCD, 0xCD, 0xCD, 0xCD, 0xCD, 0xCD, 0xCD, 0xCD, 0xA9, 0x2B, 0xAA, 0xAA, 0xA9, 0xA9, 0xA9, 0x5D, 0x5D, 0x57, 0xA8, 0xCD,
		        0xCD, 0xCD, 0xCD, 0xCD, 0xCD, 0xCD, 0xCD, 0xCD, 0xA9, 0x2B, 0x07, 0x07, 0x2C, 0x5D, 0xB0, 0xB0, 0x5D, 0xAA, 0xAA, 0x5E, 0xAA, 0xA9, 0xA9, 0xCD, 0xCD, 0xCD, 0xCD, 0xCD, 0x56, 0x07, 0x07, 0x07, 0x01, 0x01, 0x2B, 0x2C, 0x57,
		  0x2B, 0x2C, 0x32, 0x56, 0x32, 0x2C, 0x2C, 0x01, 0x01, 0x07, 0x2B, 0x2B, 0x2B, 0xCD, 0xCD, 0xCD, 0xCD, 0xCD, 0xA9, 0xAA, 0xAA, 0x5D, 0x5D, 0x57, 0x56, 0x2C, 0x32, 0x32, 0x2C, 0x07, 0x07, 0x2B, 0xA9, 0xCD, 0xCD, 0xCD, 0xCD, 0xCD, 0xCD, 0xCD, 0xCD, 0xCD,
		        0xA9, 0xA9, 0xA9, 0x5D, 0x5D, 0x5D, 0x32, 0x32, 0x2C, 0x2B, 0xCD, 0xCD, 0xCD, 0xCD, 0xCD, 0xCD, 0xCD, 0xCD, 0xCD, 0xCD, 0xCD, 0xCD, 0xCD, 0xCD, 0xCD, 0xCD, 0xCD, 0xCD, 0xCD, 0xCD, 0x2B, 0xAA, 0xAA, 0xA9, 0xA9, 0xA9, 0xA9, 0x5D, 0x57, 0xA8, 0xCD,
		        0xCD, 0xCD, 0xCD, 0xCD, 0xCD, 0xCD, 0xCD, 0xCD, 0xA9, 0x2B, 0x07, 0x07, 0x32, 0xA9, 0xB0, 0xB0, 0x5D, 0x5D, 0xA9, 0x5D, 0xA9, 0x5D, 0xA9, 0xCD, 0xCD, 0xCD, 0xCD, 0xCD, 0xA8, 0x2B, 0x2B, 0x07, 0x01, 0x07, 0x2B, 0x32, 0x5D,
		  0x2B, 0x2C, 0x32, 0x56, 0x32, 0x32, 0x2C, 0x01, 0x01, 0x07, 0x2B, 0x2B, 0x2B, 0xCD, 0xCD, 0xCD, 0xCD, 0xCD, 0xAA, 0xAA, 0x5E, 0x5D, 0x5D, 0x57, 0x32, 0x2C, 0x32, 0x32, 0x2C, 0x07, 0x07, 0x2B, 0xA9, 0xCD, 0xCD, 0xCD, 0xCD, 0xCD, 0xCD, 0xCD, 0xCD, 0xCD,
		        0xA9, 0xA9, 0xA9, 0xA9, 0x5D, 0x5D, 0x56, 0x32, 0x32, 0x2B, 0xCD, 0xCD, 0xCD, 0xCD, 0xCD, 0xCD, 0xCD, 0xCD, 0xCD, 0xCD, 0xCD, 0xCD, 0xCD, 0xCD, 0xCD, 0xCD, 0xCD, 0xCD, 0xCD, 0xCD, 0x2B, 0xB0, 0xAA, 0xA9, 0xA9, 0xA9, 0xA9, 0x5D, 0x57, 0xA9, 0xCD,
		        0xCD, 0xCD, 0xCD, 0xCD, 0xCD, 0xCD, 0xCD, 0xCD, 0xA9, 0x2B, 0x07, 0x07, 0x32, 0xA9, 0xB0, 0xB0, 0x5D, 0x5D, 0x5D, 0x5D, 0x5D, 0x5D, 0xA9, 0xCD, 0xCD, 0xCD, 0xCD, 0xCD, 0xA2, 0x2B, 0x2B, 0x07, 0x01, 0x07, 0x2B, 0x56, 0x5D,
		  0x2B, 0x2C, 0x32, 0x56, 0x32, 0x32, 0x2C, 0x07, 0x01, 0x07, 0x2B, 0x2B, 0x2B, 0xCD, 0xCD, 0xCD, 0xCD, 0xCD, 0xAA, 0x5E, 0x5E, 0x5D, 0x5D, 0x57, 0x32, 0x2C, 0x32, 0x32, 0x2C, 0x07, 0x07, 0x2B, 0xA9, 0xCD, 0xCD, 0xCD, 0xCD, 0xCD, 0xCD, 0xCD, 0xCD, 0xCD,
		        0xA9, 0x5D, 0xA9, 0x5D, 0x5D, 0x5D, 0x56, 0x32, 0x32, 0x2B, 0xCD, 0xCD, 0xCD, 0xCD, 0xCD, 0xCD, 0xCD, 0xCD, 0xCD, 0xCD, 0xCD, 0xCD, 0xCD, 0xCD, 0xCD, 0xCD, 0xCD, 0xCD, 0xCD, 0xCD, 0x2B, 0xB0, 0xB0, 0xA9, 0xA9, 0xA9, 0xA9, 0x5D, 0x5D, 0xA8, 0xCD,
		        0xCD, 0xCD, 0xCD, 0xCD, 0xCD, 0xCD, 0xCD, 0xCD, 0xA9, 0x2B, 0x07, 0x07, 0x56, 0xA9, 0xB0, 0xB0, 0x5D, 0x5D, 0xAA, 0x5D, 0x5D, 0x5D, 0x5D, 0xCD, 0xCD, 0xCD, 0xCD, 0xCD, 0x56, 0x2B, 0x2B, 0x07, 0x01, 0x07, 0x2C, 0x5D, 0x5D,
		  0x2B, 0x2C, 0x32, 0x56, 0x32, 0x32, 0x2C, 0x07, 0x01, 0x07, 0x2B, 0x2B, 0x2B, 0xCD, 0xCD, 0xCD, 0xCD, 0xCD, 0x5D, 0x5E, 0x5D, 0x5D, 0x5D, 0x57, 0x32, 0x2C, 0x32, 0x32, 0x2C, 0x07, 0x07, 0x2B, 0xA9, 0xCD, 0xCD, 0xCD, 0xCD, 0xCD, 0xCD, 0xCD, 0xCD, 0xCD,
		        0xA9, 0x5D, 0xA9, 0x5D, 0x5D, 0x5D, 0x56, 0x32, 0x32, 0x2B, 0xCD, 0xCD, 0xCD, 0xCD, 0xCD, 0xCD, 0xCD, 0xCD, 0xCD, 0xCD, 0xCD, 0xCD, 0xCD, 0xCD, 0xCD, 0xCD, 0xCD, 0xCD, 0xCD, 0xCD, 0x2B, 0xB0, 0xAA, 0xA9, 0xA9, 0xA9, 0xA9, 0x5D, 0x5D, 0xA9, 0xCD,
		        0xCD, 0xCD, 0xCD, 0xCD, 0xCD, 0xCD, 0xCD, 0xCD, 0xA9, 0x2B, 0x2B, 0x07, 0x57, 0xA9, 0xB1, 0xB0, 0x5D, 0x5D, 0xA9, 0xA9, 0x5D, 0x5D, 0x5D, 0xCD, 0xCD, 0xCD, 0xCD, 0xCD, 0x56, 0x2B, 0x2B, 0x2B, 0x01, 0x07, 0x32, 0x5D, 0x5D,
		  0x2C, 0x2C, 0x32, 0x56, 0x32, 0x32, 0x32, 0x2B, 0x01, 0x2B, 0x2B, 0x2B, 0x2B, 0xCD, 0xCD, 0xCD, 0xCD, 0xCD, 0xA9, 0x5D, 0x5D, 0x5D, 0x5D, 0x56, 0x32, 0x2C, 0x32, 0x32, 0x2C, 0x07, 0x07, 0x2B, 0xA9, 0xCD, 0xCD, 0xCD, 0xCD, 0xCD, 0xCD, 0xCD, 0xCD, 0xCD,
		        0xA9, 0x5D, 0xA9, 0x5D, 0x5D, 0x5D, 0x56, 0x32, 0x32, 0x2B, 0xCD, 0xCD, 0xCD, 0xCD, 0xCD, 0xCD, 0xCD, 0xCD, 0xCD, 0xCD, 0xCD, 0xCD, 0xCD, 0xCD, 0xCD, 0xCD, 0xCD, 0xCD, 0xCD, 0xCD, 0x2B, 0xB0, 0xB0, 0xA9, 0xA9, 0xA9, 0xA9, 0xA9, 0x5D, 0xA9, 0xCD,
		        0xCD, 0xCD, 0xCD, 0xCD, 0xCD, 0xCD, 0xCD, 0xCD, 0xA9, 0x2B, 0x2B, 0x2B, 0x5D, 0xAA, 0xB0, 0xB0, 0x5D, 0x5D, 0x5D, 0x5D, 0x5D, 0x5D, 0x5D, 0xCD, 0xCD, 0xCD, 0xCD, 0xCD, 0x56, 0x2B, 0x2B, 0x2B, 0x07, 0x2B, 0x56, 0x5D, 0x5D,
		  0x2C, 0x2C, 0x32, 0x56, 0x32, 0x32, 0x32, 0x2C, 0x07, 0x2B, 0x2C, 0x2B, 0x2B, 0xCD, 0xCD, 0xCD, 0xCD, 0xCD, 0x5D, 0x5D, 0x5D, 0x5D, 0x57, 0x56, 0x32, 0x2C, 0x32, 0x32, 0x32, 0x2B, 0x2B, 0x2B, 0xA9, 0xCD, 0xCD, 0xCD, 0xCD, 0xCD, 0xCD, 0xCD, 0xCD, 0xCD,
		        0xA9, 0xA9, 0xA9, 0x5D, 0x5D, 0x57, 0x56, 0x32, 0x32, 0x2C, 0xCD, 0xCD, 0xCD, 0xCD, 0xCD, 0xCD, 0xCD, 0xCD, 0xCD, 0xCD, 0xCD, 0xCD, 0xCD, 0xCD, 0xCD, 0xCD, 0xCD, 0xCD, 0xCD, 0xCD, 0x2C, 0xB0, 0xB0, 0xA9, 0xA9, 0xA9, 0xA9, 0x5D, 0x57, 0xA9, 0xCD,
		        0xCD, 0xCD, 0xCD, 0xCD, 0xCD, 0xCD, 0xCD, 0xCD, 0xA9, 0x2B, 0x2B, 0x2C, 0x5D, 0xAA, 0xB0, 0xAA, 0x5D, 0x5D, 0x5D, 0x5D, 0x5D, 0x5D, 0x57, 0xCD, 0xCD, 0xCD, 0xCD, 0xCD, 0x56, 0x2B, 0x2B, 0x2B, 0x07, 0x2B, 0x5D, 0x5D, 0x5D,
		  0x2C, 0x2C, 0x32, 0x56, 0x32, 0x32, 0x32, 0x2C, 0x2C, 0x2C, 0x2B, 0x2B, 0x2B, 0xCD, 0xCD, 0xCD, 0xCD, 0xCD, 0x5D, 0x5D, 0x5D, 0x5D, 0x57, 0x56, 0x32, 0x2C, 0x32, 0x32, 0x32, 0x2C, 0x2B, 0x2B, 0xA8, 0xCD, 0xCD, 0xCD, 0xCD, 0xCD, 0xCD, 0xCD, 0xCD, 0xCD,
		        0xA9, 0xA9, 0xA9, 0xA9, 0x5D, 0x57, 0x56, 0x32, 0x32, 0x32, 0xCD, 0xCD, 0xCD, 0xCD, 0xCD, 0xCD, 0xCD, 0xCD, 0xCD, 0xCD, 0xCD, 0xCD, 0xCD, 0xCD, 0xCD, 0xCD, 0xCD, 0xCD, 0xCD, 0xCD, 0x32, 0xB0, 0xAA, 0xA9, 0xA9, 0xA9, 0xA9, 0x5D, 0x57, 0xA9, 0xCD,
		        0xCD, 0xCD, 0xCD, 0xCD, 0xCD, 0xCD, 0xCD, 0xCD, 0xA8, 0x2B, 0x2C, 0x32, 0x5D, 0xAA, 0xB1, 0xAA, 0x5D, 0x5D, 0x5D, 0x5D, 0xA9, 0x5D, 0x56, 0xCD, 0xCD, 0xCD, 0xCD, 0xCD, 0x56, 0x2B, 0x2B, 0x2B, 0x2C, 0x32, 0x5D, 0x5D, 0xA9,
		  0x2B, 0x2C, 0x32, 0x56, 0x32, 0x32, 0x32, 0x32, 0x2C, 0x2C, 0x2C, 0x2B, 0x2B, 0xCD, 0xCD, 0xCD, 0xCD, 0xCD, 0x5D, 0x5D, 0x5D, 0x5D, 0x57, 0x56, 0x32, 0x2C, 0x32, 0x32, 0x32, 0x2C, 0x2C, 0x2B, 0xA8, 0xCD, 0xCD, 0xCD, 0xCD, 0xCD, 0xCD, 0xCD, 0xCD, 0xCD,
		        0xA9, 0xA9, 0xA9, 0x5D, 0x5D, 0x57, 0x56, 0x32, 0x32, 0x32, 0xCD, 0xCD, 0xCD, 0xCD, 0xCD, 0xCD, 0xCD, 0xCD, 0xCD, 0xCD, 0xCD, 0xCD, 0xCD, 0xCD, 0xCD, 0xCD, 0xCD, 0xCD, 0xCD, 0xCD, 0x56, 0xB0, 0xAA, 0xA9, 0xAA, 0xA9, 0xA9, 0xA9, 0x57, 0xA9, 0xCD,
		        0xCD, 0xCD, 0xCD, 0xCD, 0xCD, 0xCD, 0xCD, 0xCD, 0xA8, 0x2B, 0x2C, 0x57, 0x5D, 0xAA, 0xB0, 0xAA, 0x5D, 0x5D, 0x5D, 0x5D, 0x5D, 0x5D, 0x57, 0xCD, 0xCD, 0xCD, 0xCD, 0xCD, 0x56, 0x2B, 0x2B, 0x2C, 0x2C, 0x57, 0x5D, 0x5D, 0x5D,
		  0x2C, 0x2C, 0x32, 0x56, 0x32, 0x2C, 0x32, 0x32, 0x2C, 0x2C, 0x2C, 0x2B, 0x2B, 0xCD, 0xCD, 0xCD, 0xCD, 0xCD, 0xA9, 0xA9, 0x5D, 0x5D, 0x5D, 0x57, 0x56, 0x2C, 0x32, 0x2C, 0x32, 0x2C, 0x2C, 0x2B, 0xA8, 0xCD, 0xCD, 0xCD, 0xCD, 0xCD, 0xCD, 0xCD, 0xCD, 0xCD,
		        0xA9, 0xA9, 0xAA, 0xA9, 0x5D, 0x5D, 0x56, 0x32, 0x32, 0x32, 0xCD, 0xCD, 0xCD, 0xCD, 0xCD, 0xCD, 0xCD, 0xCD, 0xCD, 0xCD, 0xCD, 0xCD, 0xCD, 0xCD, 0xCD, 0xCD, 0xCD, 0xCD, 0xCD, 0xCD, 0x56, 0xB0, 0xAA, 0xA9, 0xAA, 0xA9, 0x5D, 0x5D, 0x57, 0xA9, 0xCD,
		        0xCD, 0xCD, 0xCD, 0xCD, 0xCD, 0xCD, 0xCD, 0xCD, 0xA8, 0x2B, 0x2C, 0x57, 0x5D, 0x5D, 0xB0, 0xAA, 0x5D, 0x5D, 0x5D, 0x5D, 0xA9, 0x5D, 0x57, 0xCD, 0xCD, 0xCD, 0xCD, 0xCD, 0x56, 0x2B, 0x2C, 0x2C, 0x2C, 0x5D, 0x5D, 0x57, 0x57,
		  0x2C, 0x2C, 0x32, 0x56, 0x32, 0x07, 0x2B, 0x2B, 0x2C, 0x2C, 0x2C, 0x2B, 0x2B, 0xCD, 0xCD, 0xCD, 0xCD, 0xCD, 0xAA, 0xA9, 0xAA, 0xA9, 0x5D, 0x5D, 0x56, 0x2C, 0x56, 0x2C, 0x2B, 0x2C, 0x2C, 0x2B, 0xA8, 0xCD, 0xCD, 0xCD, 0xCD, 0xCD, 0xCD, 0xCD, 0xCD, 0xCD,
		        0xA9, 0xAA, 0xAA, 0xA9, 0x5D, 0x5D, 0x56, 0x32, 0x32, 0x56, 0xCD, 0xCD, 0xCD, 0xCD, 0xCD, 0xCD, 0xCD, 0xCD, 0xCD, 0xCD, 0xCD, 0xCD, 0xCD, 0xCD, 0xCD, 0xCD, 0xCD, 0xCD, 0xCD, 0xCD, 0x32, 0xB0, 0xAA, 0x5D, 0x5D, 0x5D, 0x5D, 0x5D, 0x57, 0xA8, 0xCD,
		        0xCD, 0xCD, 0xCD, 0xCD, 0xCD, 0xCD, 0xCD, 0xCD, 0xA8, 0x2B, 0x2C, 0x57, 0x2C, 0xA9, 0xB0, 0xAA, 0x5D, 0xA9, 0xA9, 0xA9, 0xA9, 0x5D, 0x5D, 0xCD, 0xCD, 0xCD, 0xCD, 0xCD, 0x56, 0x2B, 0x2C, 0x2C, 0x32, 0x57, 0x2C, 0x32, 0x57,
		  0x2C, 0x2C, 0x32, 0x57, 0x32, 0x07, 0x2B, 0x07, 0x07, 0x2B, 0x2C, 0x2B, 0x2B, 0xCD, 0xCD, 0xCD, 0xCD, 0xCD, 0xAA, 0x5E, 0x5D, 0x5D, 0x5D, 0x57, 0x32, 0x2C, 0x32, 0x2C, 0x2B, 0x07, 0x2B, 0x2B, 0xA8, 0xCD, 0xCD, 0xCD, 0xCD, 0xCD, 0xCD, 0xCD, 0xCD, 0xCD,
		        0xA9, 0xA9, 0xA9, 0x5D, 0x5D, 0x57, 0x56, 0x32, 0x2C, 0x2C, 0xCD, 0xCD, 0xCD, 0xCD, 0xCD, 0xCD, 0xCD, 0xCD, 0xCD, 0xCD, 0xCD, 0xCD, 0xCD, 0xCD, 0xCD, 0xCD, 0xCD, 0xCD, 0xCD, 0xCD, 0x2C, 0xB0, 0xAA, 0x5D, 0x5D, 0x5D, 0x5D, 0x5D, 0x57, 0xA8, 0xCD,
		        0xCD, 0xCD, 0xCD, 0xCD, 0xCD, 0xCD, 0xCD, 0xCD, 0xA2, 0x2B, 0x2B, 0x32, 0x56, 0x5D, 0xB1, 0xAA, 0x5D, 0x5D, 0xA9, 0xA9, 0xA9, 0x5D, 0x5D, 0xCD, 0xCD, 0xCD, 0xCD, 0xCD, 0x56, 0x2B, 0x2C, 0x2C, 0x2B, 0x2C, 0x32, 0x32, 0x5D,
		  0x2C, 0x2C, 0x32, 0x57, 0x32, 0x2B, 0x2B, 0x07, 0x07, 0x07, 0x07, 0x2B, 0x2B, 0xCD, 0xCD, 0xCD, 0xCD, 0xA9, 0x5E, 0x5E, 0x5E, 0x5D, 0x5D, 0x57, 0x32, 0x2C, 0x56, 0x2C, 0x2B, 0x07, 0x07, 0x2B, 0xA2, 0xCD, 0xCD, 0xCD, 0xCD, 0xCD, 0xCD, 0xCD, 0xCD, 0xCD,
		        0xA9, 0xA9, 0xA9, 0x5D, 0x5D, 0x5D, 0x56, 0x32, 0x32, 0x2C, 0xCD, 0xCD, 0xCD, 0xCD, 0xCD, 0xCD, 0xCD, 0xCD, 0xCD, 0xCD, 0xCD, 0xCD, 0xCD, 0xCD, 0xCD, 0xCD, 0xCD, 0xCD, 0xCD, 0xCD, 0x32, 0xB0, 0xA9, 0x5D, 0x5D, 0x5D, 0x5D, 0x5D, 0x57, 0xA9, 0xCD,
		        0xCD, 0xCD, 0xCD, 0xCD, 0xCD, 0xCD, 0xCD, 0xCD, 0xA2, 0x2B, 0x07, 0x32, 0x56, 0xA9, 0xB1, 0xAA, 0x5D, 0x5D, 0xA9, 0xA9, 0xAA, 0xA9, 0x57, 0xCD, 0xCD, 0xCD, 0xCD, 0xCD, 0x56, 0x2B, 0x2B, 0x07, 0x32, 0x32, 0x32, 0x32, 0x57,
		  0x2C, 0x2C, 0x32, 0x57, 0x32, 0x07, 0x2B, 0x07, 0x07, 0x07, 0x01, 0x2B, 0x2B, 0xCD, 0xCD, 0xCD, 0xCD, 0xA9, 0xA9, 0xAA, 0xA9, 0x5D, 0x5D, 0x57, 0x32, 0x2C, 0x56, 0x2C, 0x2B, 0x2B, 0x07, 0x2B, 0xA2, 0xCD, 0xCD, 0xCD, 0xCD, 0xCD, 0xCD, 0xCD, 0xCD, 0xCD,
		        0xA9, 0xAA, 0xA9, 0x5D, 0x5D, 0x5D, 0x56, 0x32, 0x32, 0x2C, 0xCD, 0xCD, 0xCD, 0xCD, 0xCD, 0xCD, 0xCD, 0xCD, 0xCD, 0xCD, 0xCD, 0xCD, 0xCD, 0xCD, 0xCD, 0xCD, 0xCD, 0xCD, 0xCD, 0xCD, 0x2C, 0xB0, 0x5D, 0x5D, 0x5D, 0x5D, 0x5D, 0x5D, 0x57, 0x56, 0xCD,
		        0xCD, 0xCD, 0xCD, 0xCD, 0xCD, 0xCD, 0xCD, 0xCD, 0xA2, 0x2B, 0x2B, 0x32, 0x32, 0xA9, 0xB1, 0xAA, 0x5D, 0x5D, 0x5D, 0x5D, 0xAA, 0xA9, 0x57, 0xCD, 0xCD, 0xCD, 0xCD, 0xCD, 0x56, 0x2B, 0x07, 0x2B, 0x32, 0x2C, 0x33, 0x32, 0x57,
		  0x2C, 0x2C, 0x32, 0x57, 0x32, 0x2B, 0x2B, 0x07, 0x07, 0x07, 0x01, 0x2B, 0x07, 0xCD, 0xCD, 0xCD, 0xCD, 0xA9, 0xA9, 0xA9, 0xA9, 0x5D, 0x5D, 0x5D, 0x56, 0x2C, 0x56, 0x2C, 0x2B, 0x07, 0x07, 0x2B, 0xA2, 0xCD, 0xCD, 0xCD, 0xCD, 0xCD, 0xCD, 0xCD, 0xCD, 0xCD,
		        0xA9, 0x5D, 0x5D, 0x5D, 0x5D, 0x57, 0x56, 0x32, 0x32, 0x32, 0xCD, 0xCD, 0xCD, 0xCD, 0xCD, 0xCD, 0xCD, 0xCD, 0xCD, 0xCD, 0xCD, 0xCD, 0xCD, 0xCD, 0xCD, 0xCD, 0xCD, 0xCD, 0xCD, 0xCD, 0x32, 0xB0, 0xAA, 0xA9, 0xAA, 0xA9, 0xA9, 0x5D, 0x57, 0x56, 0xCD,
		        0xCD, 0xCD, 0xCD, 0xCD, 0xCD, 0xCD, 0xCD, 0xCD, 0x56, 0x2B, 0x2C, 0x32, 0x32, 0xA9, 0xD5, 0xAA, 0x5D, 0x5D, 0x5D, 0x5E, 0x5D, 0x5D, 0x57, 0xCD, 0xCD, 0xCD, 0xCD, 0xCD, 0x56, 0x2B, 0x07, 0x2B, 0x32, 0x32, 0x32, 0x32, 0x57,
		  0x2C, 0x2C, 0x32, 0x57, 0x32, 0x2B, 0x2B, 0x07, 0x07, 0x07, 0x01, 0x2B, 0x07, 0xCD, 0xCD, 0xCD, 0xCD, 0xA9, 0xA9, 0xA9, 0xAA, 0x5D, 0x5D, 0x5D, 0x56, 0x2C, 0x56, 0x2C, 0x2B, 0x2B, 0x07, 0x2B, 0xA2, 0xCD, 0xCD, 0xCD, 0xCD, 0xCD, 0xCD, 0xCD, 0xCD, 0xCD,
		        0xA9, 0x5D, 0x5D, 0x5D, 0x5D, 0x57, 0x56, 0x32, 0x32, 0x32, 0xCD, 0xCD, 0xCD, 0xCD, 0xCD, 0xCD, 0xCD, 0xCD, 0xCD, 0xCD, 0xCD, 0xCD, 0xCD, 0xCD, 0xCD, 0xCD, 0xCD, 0xCD, 0xCD, 0xCD, 0x56, 0xB0, 0xAA, 0xA9, 0xA9, 0xA9, 0xAA, 0xA9, 0x57, 0x56, 0xCD,
		        0xCD, 0xCD, 0xCD, 0xCD, 0xCD, 0xCD, 0xCD, 0xCD, 0x56, 0x2B, 0x32, 0x56, 0x56, 0x5D, 0xD5, 0xAA, 0x5D, 0x5D, 0x5D, 0xAA, 0x5D, 0x5D, 0x56, 0xCD, 0xCD, 0xCD, 0xCD, 0xCD, 0x56, 0x2B, 0x2B, 0x32, 0x32, 0x32, 0x32, 0x57, 0x57,
		  0x2C, 0x2C, 0x32, 0x56, 0x32, 0x2C, 0x2B, 0x07, 0x07, 0x01, 0x07, 0x2C, 0x07, 0xCD, 0xCD, 0xCD, 0xCD, 0xA9, 0xA9, 0xA9, 0xA9, 0x5D, 0x5D, 0x57, 0x32, 0x2C, 0x56, 0x32, 0x2B, 0x2B, 0x07, 0x2B, 0x56, 0xCD, 0xCD, 0xCD, 0xCD, 0xCD, 0xCD, 0xCD, 0xCD, 0xCD,
		        0xA9, 0x5D, 0x5D, 0x5D, 0x5D, 0x5D, 0x57, 0x2C, 0x32, 0x2C, 0xCD, 0xCD, 0xCD, 0xCD, 0xCD, 0xCD, 0xCD, 0xCD, 0xCD, 0xCD, 0xCD, 0xCD, 0xCD, 0xCD, 0xCD, 0xCD, 0xCD, 0xCD, 0xCD, 0xCD, 0x32, 0xB0, 0xAA, 0xA9, 0xA9, 0xA9, 0xAA, 0xA9, 0x57, 0x56, 0xCD,
		        0xCD, 0xCD, 0xCD, 0xCD, 0xCD, 0xCD, 0xCD, 0xCD, 0x56, 0x2B, 0x56, 0x32, 0x32, 0xA9, 0xD5, 0xAA, 0x5D, 0x5D, 0x5D, 0x5D, 0x5D, 0x5D, 0x56, 0xCD, 0xCD, 0xCD, 0xCD, 0xCD, 0x56, 0x2B, 0x2B, 0x32, 0x32, 0x2C, 0x2C, 0x56, 0x5D,
		  0x2C, 0x2C, 0x32, 0x56, 0x32, 0x32, 0x32, 0x2C, 0x2B, 0x07, 0x07, 0x2C, 0x07, 0xCD, 0xA9, 0xA9, 0xA9, 0xA9, 0xA9, 0xAA, 0xA9, 0x5D, 0x5D, 0x57, 0x56, 0x2C, 0x56, 0x32, 0x32, 0x2B, 0x07, 0x2B, 0x56, 0xCD, 0xCD, 0xCD, 0xCD, 0xCD, 0xCD, 0xCD, 0xCD, 0xCD,
		        0xA9, 0x5D, 0x5D, 0x5D, 0x5D, 0x5D, 0x57, 0x32, 0x56, 0x32, 0xCD, 0xCD, 0xCD, 0xCD, 0xCD, 0xCD, 0xCD, 0xCD, 0xCD, 0xCD, 0xCD, 0xCD, 0xCD, 0xCD, 0xCD, 0xCD, 0xCD, 0xCD, 0xCD, 0xA9, 0x5D, 0xB0, 0xAA, 0xA9, 0xAA, 0xAA, 0xAA, 0xA9, 0x5D, 0x56, 0xCD,
		        0xCD, 0xCD, 0xCD, 0xCD, 0xCD, 0xCD, 0xCD, 0xCD, 0x56, 0x2C, 0x32, 0x57, 0x5D, 0xAA, 0xD5, 0xAA, 0x5D, 0x5D, 0x5D, 0x5D, 0x5D, 0x5D, 0x56, 0xA9, 0xCD, 0xCD, 0xCD, 0xCD, 0x56, 0x2B, 0x2C, 0x32, 0x32, 0x57, 0x5D, 0xA9, 0xA9,
		  0x2C, 0x2C, 0x32, 0x57, 0x56, 0x32, 0x32, 0x32, 0x32, 0x32, 0x2B, 0x2C, 0x07, 0x56, 0x2B, 0x07, 0x07, 0x2B, 0x5D, 0x5D, 0x5D, 0x5D, 0x5D, 0x57, 0x56, 0x2C, 0x56, 0x32, 0x32, 0x32, 0x2C, 0x2B, 0x56, 0xCD, 0xCD, 0xCD, 0xCD, 0xCD, 0xCD, 0xCD, 0xCD, 0xCD,
		        0x5D, 0x5D, 0x5D, 0xA9, 0x5D, 0x5D, 0x57, 0x32, 0x56, 0x56, 0xCD, 0xCD, 0xCD, 0xCD, 0xCD, 0xCD, 0xCD, 0xCD, 0xCD, 0xCD, 0xCD, 0xCD, 0xCD, 0xCD, 0xCD, 0xCD, 0xCD, 0xCD, 0xCD, 0xA9, 0xA9, 0xB0, 0xAA, 0xA9, 0xA9, 0xA9, 0xA9, 0xA9, 0x5D, 0x56, 0xCD,
		        0xCD, 0xCD, 0xCD, 0xCD, 0xCD, 0xCD, 0xCD, 0xCD, 0x56, 0x32, 0x5D, 0xA9, 0xA9, 0xAA, 0xD5, 0xAA, 0xA9, 0xA9, 0xAA, 0xAA, 0xA9, 0x5D, 0x5D, 0xA9, 0xCD, 0xCD, 0xCD, 0xA9, 0x2B, 0x2B, 0x57, 0x57, 0x5D, 0x5D, 0x5D, 0xA9, 0xA9,
		  0x2C, 0x2C, 0x32, 0x57, 0x56, 0x32, 0x32, 0x32, 0x32, 0x32, 0x2C, 0x2C, 0x07, 0x07, 0x07, 0x07, 0x07, 0x2B, 0x5D, 0x5D, 0x5D, 0x5D, 0x5D, 0x57, 0x32, 0x2C, 0x32, 0x32, 0x32, 0x32, 0x2C, 0x2C, 0x56, 0xCD, 0xCD, 0xCD, 0xCD, 0xCD, 0xCD, 0xCD, 0xCD, 0xCD,
		        0x5D, 0x5D, 0x5D, 0x5D, 0x5D, 0x5D, 0x57, 0x32, 0x56, 0x56, 0xCD, 0xCD, 0xCD, 0xCD, 0xCD, 0xCD, 0xCD, 0xCD, 0xCD, 0xCD, 0xCD, 0xCD, 0xCD, 0xCD, 0xCD, 0xCD, 0xCD, 0xCD, 0xCD, 0xA9, 0xA9, 0xB0, 0xAA, 0xA9, 0xA9, 0xA9, 0xA9, 0x5D, 0x5D, 0x56, 0xCD,
		        0xCD, 0xCD, 0xCD, 0xCD, 0xCD, 0xCD, 0xCD, 0xCD, 0x56, 0x57, 0x5D, 0xA9, 0xAA, 0xAA, 0xD5, 0xAA, 0xA9, 0xA9, 0xAA, 0xAA, 0xAA, 0xA9, 0x5D, 0xA9, 0xCD, 0xA9, 0xA9, 0x2B, 0x07, 0x32, 0x5D, 0x5D, 0x5D, 0x5D, 0xA9, 0xA9, 0xA9,
		  0x2C, 0x2C, 0x32, 0x56, 0x32, 0x32, 0x32, 0x32, 0x32, 0x32, 0x32, 0x2C, 0x07, 0x00, 0x07, 0x07, 0x07, 0x2B, 0x5D, 0xA9, 0xAA, 0x5D, 0x5D, 0x57, 0x32, 0x2C, 0x32, 0x32, 0x32, 0x32, 0x32, 0x2C, 0x2B, 0xA9, 0xA9, 0xA9, 0xA9, 0xA9, 0xA9, 0xCD, 0xCD, 0xA9,
		        0x5D, 0xA9, 0xA9, 0x5D, 0x5D, 0x5D, 0x57, 0x2C, 0x56, 0x56, 0xCD, 0xCD, 0xCD, 0xCD, 0xCD, 0xCD, 0xCD, 0xCD, 0xCD, 0xCD, 0xCD, 0xCD, 0xCD, 0xCD, 0xCD, 0xCD, 0xCD, 0xCD, 0xCD, 0xA9, 0xA9, 0xB0, 0xAA, 0xA9, 0xA9, 0xA9, 0xA9, 0x5D, 0x5D, 0x56, 0xCD,
		        0xCD, 0xCD, 0xCD, 0xCD, 0xCD, 0xCD, 0xCD, 0xCD, 0x56, 0x5D, 0x5D, 0xA9, 0x5D, 0x5D, 0xD5, 0xAA, 0xA9, 0xA9, 0xAA, 0xAA, 0xAA, 0xA9, 0x5D, 0x32, 0x56, 0x2B, 0x2B, 0x07, 0x07, 0x56, 0x5D, 0x5D, 0x5D, 0x5D, 0xA9, 0x5D, 0x5D,
		  0x2C, 0x2C, 0x32, 0x56, 0x32, 0x32, 0x32, 0x32, 0x32, 0x32, 0x32, 0x2C, 0x07, 0x07, 0x07, 0x07, 0x07, 0x2B, 0x5D, 0xAA, 0xAA, 0x5D, 0x5D, 0x5D, 0x56, 0x2C, 0x56, 0x32, 0x2C, 0x2C, 0x2C, 0x2C, 0x07, 0x2B, 0x31, 0xA9, 0xA9, 0xA9, 0xA8, 0x56, 0xA9, 0xA9,
		        0x5D, 0xA9, 0xA9, 0x5D, 0x5D, 0x5D, 0x56, 0x2C, 0x32, 0x56, 0xCD, 0xCD, 0xCD, 0xCD, 0xCD, 0xCD, 0xCD, 0xCD, 0xCD, 0xCD, 0xCD, 0xCD, 0xCD, 0xCD, 0xCD, 0xCD, 0xCD, 0xCD, 0xCD, 0xA9, 0x57, 0xB0, 0xA9, 0xA9, 0xA9, 0xA9, 0xA9, 0x5D, 0x57, 0x56, 0xCD,
		        0xCD, 0xCD, 0xA9, 0xCD, 0xCD, 0xA9, 0xA9, 0xCD, 0x56, 0x5D, 0x5D, 0x5D, 0x2C, 0x5D, 0xD5, 0xAA, 0xA9, 0xA9, 0xAA, 0xAA, 0xAA, 0xA9, 0x5D, 0x2B, 0x07, 0x07, 0x07, 0x07, 0x07, 0x56, 0x5D, 0x5D, 0x5D, 0x5D, 0x32, 0x2C, 0x57,
		  0x2C, 0x2C, 0x32, 0x56, 0x32, 0x32, 0x32, 0x32, 0x32, 0x2C, 0x2C, 0x2C, 0x07, 0x00, 0x00, 0x00, 0x07, 0x2B, 0xA9, 0xA9, 0x5D, 0x5D, 0x5D, 0x5D, 0x56, 0x2C, 0x56, 0x32, 0x32, 0x32, 0x2C, 0x2C, 0x07, 0x07, 0x07, 0x31, 0x07, 0x07, 0x07, 0x07, 0x07, 0x2B,
		        0x5D, 0x5D, 0xA9, 0x5D, 0x5D, 0x5D, 0x5D, 0x32, 0x32, 0x32, 0xCD, 0xCD, 0xCD, 0xCD, 0xCD, 0xCD, 0xCD, 0xCD, 0xCD, 0xCD, 0xCD, 0xCD, 0xCD, 0xCD, 0xCD, 0xCD, 0xCD, 0xCD, 0xCD, 0xA9, 0x57, 0xB0, 0x5D, 0x5D, 0x5D, 0x5D, 0x5D, 0x5D, 0x57, 0x56, 0xA9,
		        0xA9, 0xCD, 0xA9, 0xA9, 0x56, 0x2B, 0x56, 0x56, 0x2B, 0x57, 0x2B, 0xAA, 0x5D, 0xAA, 0xD5, 0xAA, 0xA9, 0xA9, 0xAA, 0xA9, 0x5D, 0x5D, 0x5D, 0x07, 0x07, 0x07, 0x07, 0x07, 0x07, 0x56, 0x57, 0x2C, 0x2C, 0xAA, 0x5D, 0x5D, 0xA9,
		  0x2C, 0x2C, 0x32, 0x56, 0x32, 0x32, 0x32, 0x32, 0x32, 0x32, 0x32, 0x2C, 0x07, 0x00, 0x00, 0x07, 0x07, 0x2B, 0x5D, 0x5D, 0x5D, 0x5D, 0x5D, 0x5D, 0x32, 0x2C, 0x56, 0x32, 0x32, 0x32, 0x2C, 0x2C, 0x07, 0x07, 0x07, 0x07, 0x07, 0x07, 0x07, 0x07, 0x07, 0x07,
		        0x5D, 0xA9, 0xA9, 0xA9, 0x5D, 0x5D, 0x5D, 0x32, 0x32, 0x56, 0xCD, 0xA9, 0xA9, 0xA9, 0xA9, 0xCD, 0xCD, 0xCD, 0xCD, 0xCD, 0xCD, 0xCD, 0xCD, 0xCD, 0xCD, 0xCD, 0xCD, 0xCD, 0xCD, 0xA9, 0xB0, 0xB0, 0x5D, 0x5E, 0x5D, 0x5D, 0x5D, 0x5D, 0x57, 0x56, 0xA9,
		        0xA9, 0xA8, 0x2B, 0x07, 0x07, 0x07, 0x07, 0x07, 0x07, 0xAA, 0x5D, 0xB0, 0xAA, 0xAA, 0xD5, 0xAA, 0x5D, 0x5D, 0xAA, 0x5D, 0x5D, 0x5D, 0x5D, 0x07, 0x07, 0x00, 0x07, 0x06, 0x07, 0x57, 0xAA, 0x57, 0x5D, 0xAA, 0xAA, 0xA9, 0xA9,
		  0x2C, 0x2C, 0x32, 0x56, 0x32, 0x32, 0x32, 0x32, 0x32, 0x32, 0x32, 0x2C, 0x07, 0x00, 0x07, 0x07, 0x07, 0x2B, 0x5D, 0x5D, 0x5D, 0x5D, 0x5D, 0x5D, 0x32, 0x2C, 0x56, 0x32, 0x32, 0x32, 0x32, 0x2C, 0x07, 0x06, 0x07, 0x07, 0x07, 0x07, 0x07, 0x07, 0x07, 0x07,
		        0x5D, 0xA9, 0xA9, 0xA9, 0x5D, 0x5D, 0x5D, 0x32, 0x32, 0x56, 0xA9, 0xA9, 0xA9, 0xA9, 0xA9, 0xA9, 0xA9, 0xA9, 0xCD, 0xCD, 0xA9, 0xCD, 0xCD, 0xCD, 0xCD, 0xA9, 0xA9, 0xA9, 0xA9, 0xA9, 0xB0, 0xB0, 0x5D, 0x5E, 0x5D, 0x5D, 0x5D, 0x5D, 0x57, 0x56, 0x56,
		        0x56, 0x2B, 0x07, 0x00, 0x07, 0x07, 0x07, 0x07, 0x07, 0xAA, 0x5D, 0xB0, 0xAA, 0xAA, 0xD5, 0xAA, 0x5D, 0x5D, 0x5D, 0x5D, 0x5D, 0x57, 0x5D, 0x07, 0x00, 0x07, 0x07, 0x07, 0x07, 0x57, 0xB0, 0x5D, 0x5D, 0xB0, 0xAA, 0xA9, 0xA9,
		  0x2C, 0x2C, 0x32, 0x56, 0x32, 0x32, 0x32, 0x32, 0x32, 0x32, 0x32, 0x32, 0x07, 0x07, 0x07, 0x07, 0x07, 0x2B, 0x5D, 0x5D, 0x5D, 0x5D, 0x5D, 0x5D, 0x32, 0x2C, 0x56, 0x32, 0x32, 0x32, 0x32, 0x2C, 0x2B, 0x00, 0x07, 0x07, 0x07, 0x07, 0x07, 0x07, 0x07, 0x07,
		        0x5D, 0xA9, 0xA9, 0xA9, 0x5D, 0x5D, 0x5D, 0x32, 0x32, 0x56, 0xA9, 0xA9, 0xA9, 0xA9, 0xA9, 0xA9, 0xA9, 0xA9, 0xA9, 0xA9, 0xA9, 0xA9, 0xA9, 0xA9, 0xA9, 0xA9, 0xA9, 0xA9, 0xA9, 0xA9, 0xB0, 0xB0, 0x5D, 0x5D, 0x5D, 0x5D, 0x5D, 0x5D, 0x57, 0x56, 0x2B,
		        0x07, 0x07, 0x07, 0x07, 0x07, 0x07, 0x07, 0x07, 0x2B, 0xAA, 0x5D, 0xB0, 0xAA, 0xAA, 0xD5, 0xAA, 0x5D, 0x5D, 0x5D, 0x5D, 0x5D, 0x5D, 0x5D, 0x07, 0x07, 0x07, 0x00, 0x07, 0x32, 0x5D, 0xB0, 0x5D, 0x5D, 0xB0, 0xAA, 0xA9, 0xAA,
		  0x2C, 0x2C, 0x32, 0x56, 0x32, 0x32, 0x32, 0x32, 0x32, 0x32, 0x32, 0x2C, 0x07, 0x07, 0x07, 0x00, 0x00, 0x2B, 0x5D, 0xAA, 0x5D, 0x5D, 0x5D, 0x5D, 0x56, 0x2C, 0x56, 0x32, 0x32, 0x32, 0x32, 0x2C, 0x07, 0x00, 0x00, 0x07, 0x07, 0x07, 0x07, 0x07, 0x06, 0x00,
		        0x5D, 0xA9, 0xA9, 0xA9, 0x5D, 0x5D, 0x57, 0x32, 0x32, 0x56, 0xA9, 0xA9, 0xA9, 0xA9, 0xA9, 0xA9, 0xA9, 0xA9, 0xA9, 0xA9, 0xA9, 0xA9, 0xA9, 0xA9, 0xA9, 0xA9, 0xA9, 0xA9, 0xA9, 0xA9, 0xB0, 0xB0, 0x5D, 0x5D, 0x5D, 0x5D, 0x5D, 0x5D, 0x57, 0x56, 0x2B,
		        0x00, 0x07, 0x07, 0x07, 0x07, 0x07, 0x07, 0x07, 0x2C, 0xAA, 0x5D, 0xB0, 0xAA, 0xAA, 0xD5, 0xAA, 0x5D, 0x5D, 0x5D, 0x5D, 0x5D, 0x5D, 0x57, 0x2B, 0x07, 0x07, 0x07, 0x07, 0x32, 0x5D, 0xB0, 0x5D, 0x5D, 0xB0, 0xAA, 0xA9, 0xAA,
		  0x2C, 0x2B, 0x32, 0x56, 0x32, 0x32, 0x32, 0x32, 0x32, 0x32, 0x32, 0x2C, 0x07, 0x07, 0x00, 0x00, 0x00, 0x2B, 0xAA, 0xA9, 0x5D, 0x5D, 0x5D, 0x57, 0x32, 0x2C, 0x56, 0x32, 0x32, 0x32, 0x32, 0x2C, 0x07, 0x00, 0x06, 0x00, 0x07, 0x07, 0x07, 0x07, 0x07, 0x06,
		        0x5D, 0xAA, 0xAA, 0x5D, 0x5D, 0x5D, 0x57, 0x32, 0x32, 0x56, 0xA9, 0xA9, 0xA9, 0xA9, 0xA9, 0xA9, 0xA9, 0xA9, 0xA9, 0xA9, 0xA9, 0xA9, 0xA9, 0xA9, 0xA9, 0xA9, 0xA9, 0xA9, 0xA9, 0xA9, 0xB0, 0xB0, 0x5D, 0x5D, 0x5D, 0x5D, 0x5D, 0x57, 0x57, 0x2C, 0x07,
		        0x06, 0x07, 0x07, 0x07, 0x07, 0x07, 0x07, 0x07, 0x2C, 0xAA, 0x5D, 0xB0, 0xAA, 0xAA, 0xB0, 0xAA, 0x5D, 0x5D, 0x5D, 0x5D, 0x5D, 0x57, 0x5D, 0x2B, 0x07, 0x07, 0x07, 0x07, 0x56, 0x5D, 0xB0, 0x5D, 0x5D, 0xB0, 0xAA, 0xA9, 0xAA,
		  0x2C, 0x2B, 0x32, 0x56, 0x32, 0x32, 0x32, 0x32, 0x32, 0x32, 0x32, 0x2C, 0x07, 0x07, 0x06, 0x00, 0x00, 0x2B, 0x5D, 0x5D, 0x5D, 0x5D, 0x5D, 0x57, 0x32, 0x2C, 0x56, 0x32, 0x32, 0x32, 0x32, 0x2C, 0x07, 0x07, 0x00, 0x07, 0x07, 0x07, 0x07, 0x07, 0x06, 0x00,
		        0x5D, 0xA9, 0xAA, 0x5D, 0x5D, 0x5D, 0x57, 0x32, 0x32, 0x56, 0xA9, 0xA9, 0xA9, 0xA9, 0xA9, 0xA9, 0xA9, 0xA9, 0xA9, 0xA9, 0xA9, 0xA9, 0xA9, 0xA9, 0xA9, 0xA9, 0xA9, 0xA9, 0xA9, 0xA9, 0xB0, 0xB0, 0x5D, 0x57, 0x57, 0x57, 0x57, 0x57, 0x56, 0x2C, 0x07,
		        0x07, 0x07, 0x07, 0x07, 0x07, 0x07, 0x07, 0x07, 0x2C, 0xAA, 0x5D, 0xB0, 0xAA, 0xAA, 0xB0, 0xAA, 0x57, 0x5D, 0x5D, 0x5D, 0x5D, 0x5D, 0x5D, 0x2B, 0x07, 0x07, 0x07, 0x07, 0x56, 0x5D, 0xB0, 0x5D, 0x5D, 0xB0, 0xAA, 0xA9, 0xA9,
		  0x2B, 0x2B, 0x32, 0x56, 0x56, 0x32, 0x32, 0x32, 0x32, 0x32, 0x32, 0x2C, 0x07, 0x00, 0x06, 0x06, 0x07, 0x2B, 0x5D, 0x5D, 0x5D, 0x5D, 0x57, 0x57, 0x32, 0x2C, 0x56, 0x32, 0x32, 0x32, 0x32, 0x2C, 0x07, 0x07, 0x07, 0x00, 0x07, 0x07, 0x00, 0x00, 0x06, 0x00,
		        0xA9, 0xA9, 0xAA, 0x5D, 0x5D, 0x5D, 0x56, 0x32, 0x32, 0x32, 0xA9, 0xA9, 0xA9, 0xA9, 0xA9, 0xA9, 0xA9, 0xA9, 0xA9, 0xA9, 0xA9, 0xA9, 0xA9, 0xA9, 0xA9, 0xA9, 0xA9, 0xA9, 0xA9, 0xA9, 0xB0, 0xB0, 0x5D, 0x5D, 0x5D, 0x5D, 0x5D, 0x57, 0x56, 0x2C, 0x07,
		        0x06, 0x07, 0x07, 0x07, 0x00, 0x00, 0x07, 0x00, 0x2C, 0xAA, 0x5D, 0xAA, 0xAA, 0xAA, 0xD5, 0xA9, 0x5D, 0x5D, 0x5D, 0x5D, 0x5D, 0x5D, 0x5D, 0x2B, 0x07, 0x07, 0x07, 0x07, 0x32, 0x5D, 0xB0, 0x5D, 0x5D, 0xB0, 0xAA, 0xAA, 0xA9,
		  0x2C, 0x2B, 0x32, 0x56, 0x56, 0x32, 0x32, 0x32, 0x32, 0x32, 0x32, 0x2C, 0x07, 0x06, 0x07, 0x07, 0x07, 0x2C, 0x5D, 0x5D, 0x5D, 0x5D, 0x57, 0x57, 0x32, 0x2C, 0x56, 0x32, 0x32, 0x32, 0x32, 0x2C, 0x07, 0x07, 0x07, 0x06, 0x00, 0x00, 0x00, 0x00, 0x00, 0x00,
		        0x5D, 0xA9, 0xA9, 0xA9, 0x5D, 0x5D, 0x56, 0x32, 0x32, 0x32, 0x2B, 0xA9, 0xA9, 0xA9, 0xA9, 0xA9, 0xA9, 0xA9, 0xA9, 0xA9, 0xA9, 0xA9, 0xA9, 0xA9, 0xA9, 0xA9, 0xA9, 0xA9, 0xA9, 0xA9, 0xB0, 0xB0, 0xA9, 0x5D, 0x5D, 0x5D, 0x5D, 0x5D, 0x57, 0x2C, 0x00,
		        0x06, 0x07, 0x07, 0x07, 0x06, 0x06, 0x07, 0x07, 0x32, 0xAA, 0x5D, 0xAA, 0xAA, 0xAA, 0xD5, 0xAA, 0x5D, 0x5D, 0x5D, 0x5D, 0x5D, 0x5D, 0x57, 0x07, 0x00, 0x00, 0x07, 0x07, 0x32, 0x5D, 0xB0, 0x5D, 0x5D, 0xB0, 0xAA, 0xAA, 0xAA,
		  0x2C, 0x2B, 0x32, 0x56, 0x32, 0x32, 0x32, 0x32, 0x32, 0x32, 0x32, 0x2C, 0x07, 0x00, 0x00, 0x00, 0x00, 0x2B, 0x5D, 0x5D, 0x5D, 0x5D, 0x57, 0x57, 0x32, 0x2C, 0x56, 0x32, 0x32, 0x32, 0x32, 0x2C, 0x07, 0x07, 0x07, 0x07, 0x07, 0x06, 0x07, 0x07, 0x00, 0x00,
		        0x5D, 0xA9, 0xA9, 0x5D, 0x5D, 0x57, 0x56, 0x32, 0x32, 0x32, 0x06, 0x2B, 0xA2, 0xA9, 0xA9, 0xA9, 0xA9, 0xA9, 0xA9, 0xA9, 0xA9, 0xA9, 0xA9, 0xA9, 0xA9, 0xA9, 0xA9, 0xA9, 0xA9, 0xA9, 0xB0, 0xB0, 0xA9, 0x5D, 0xA9, 0x5D, 0x5D, 0x5D, 0x57, 0x2C, 0x07,
		        0x07, 0x07, 0x07, 0x07, 0x06, 0x00, 0x07, 0x07, 0x32, 0xAA, 0x5D, 0xB0, 0xAA, 0xAA, 0xD5, 0xAA, 0x5D, 0x5D, 0xA9, 0x5D, 0x5D, 0x57, 0x56, 0x01, 0x00, 0x00, 0x07, 0x07, 0x32, 0x5D, 0xB0, 0x5D, 0x5D, 0xB0, 0xAA, 0xAA, 0xAA,
		  0x2C, 0x2B, 0x32, 0x56, 0x56, 0x32, 0x32, 0x32, 0x32, 0x32, 0x32, 0x2C, 0x07, 0x00, 0x00, 0x00, 0x00, 0x2B, 0x5D, 0x5D, 0x5D, 0x57, 0x57, 0x57, 0x32, 0x2C, 0x56, 0x32, 0x32, 0x32, 0x32, 0x2C, 0x07, 0x00, 0x00, 0x00, 0x06, 0x07, 0x07, 0x07, 0x00, 0x00,
		        0xA9, 0xA9, 0xA9, 0xA9, 0x5D, 0x57, 0x56, 0x2C, 0x32, 0x32, 0x00, 0x06, 0x2B, 0x56, 0xA8, 0xA9, 0xA9, 0xA9, 0xA9, 0xA9, 0xA9, 0xA9, 0xA9, 0xA9, 0xA9, 0xA9, 0xA9, 0xA9, 0xA9, 0xA9, 0xB0, 0xB0, 0xA9, 0xA9, 0xA9, 0x5D, 0x5D, 0x5D, 0x57, 0x2C, 0x07,
		        0x07, 0x07, 0x07, 0x07, 0x07, 0x07, 0x07, 0x07, 0x2C, 0xAA, 0x5D, 0xB0, 0xAA, 0xAA, 0xD5, 0x5D, 0x5D, 0x5D, 0x5D, 0x5D, 0x5D, 0x57, 0x56, 0x07, 0x07, 0x07, 0x07, 0x00, 0x56, 0x5D, 0xB0, 0x5D, 0x5D, 0xB0, 0xAA, 0xAA, 0xAA,
		  0x2C, 0x2B, 0x32, 0x56, 0x32, 0x32, 0x32, 0x32, 0x32, 0x32, 0x32, 0x2C, 0x07, 0x06, 0x00, 0x00, 0x00, 0x2B, 0x5D, 0x5D, 0x5D, 0x57, 0x57, 0x57, 0x32, 0x2C, 0x56, 0x32, 0x32, 0x32, 0x32, 0x2C, 0x07, 0x07, 0x00, 0x00, 0x00, 0x07, 0x07, 0x07, 0x06, 0x00,
		        0x5D, 0x5D, 0xA9, 0xA9, 0x5D, 0x57, 0x56, 0x2C, 0x32, 0x32, 0x00, 0x00, 0x06, 0x06, 0x31, 0x56, 0x56, 0xA8, 0xA8, 0xA8, 0xA8, 0xA9, 0xA9, 0xA9, 0xA9, 0xA9, 0xA8, 0x56, 0x56, 0x56, 0xB0, 0xB0, 0xA9, 0xA9, 0x5D, 0x5D, 0x5D, 0x5D, 0x57, 0x2B, 0x07,
		        0x07, 0x06, 0x07, 0x00, 0x07, 0x07, 0x56, 0x56, 0x2B, 0xAA, 0x5D, 0xAA, 0xAA, 0xAA, 0xD5, 0xA9, 0x5D, 0x5D, 0x5D, 0x5D, 0x5D, 0x5D, 0x56, 0x2B, 0x07, 0x07, 0x07, 0x00, 0x32, 0x5D, 0xB0, 0x5D, 0x5D, 0xB0, 0xAA, 0xAA, 0xAA,
		  0x2B, 0x2B, 0x32, 0x56, 0x32, 0x32, 0x32, 0x32, 0x32, 0x32, 0x32, 0x2C, 0x2B, 0x00, 0x00, 0x00, 0x00, 0x2B, 0x5D, 0x5D, 0x5D, 0x5D, 0x57, 0x56, 0x32, 0x2C, 0x56, 0x32, 0x32, 0x32, 0x32, 0x2C, 0x07, 0x06, 0x00, 0x07, 0x07, 0x07, 0x00, 0x2B, 0x2B, 0x00,
		        0x5D, 0xA9, 0xA9, 0x5D, 0x5D, 0x57, 0x56, 0x2C, 0x32, 0x32, 0x00, 0x00, 0x00, 0x06, 0x32, 0x2B, 0x2B, 0x56, 0xA9, 0xA9, 0xA2, 0x56, 0xA9, 0xA9, 0xA8, 0x56, 0x2B, 0x2B, 0x07, 0x2B, 0xB0, 0xB0, 0xA9, 0x5D, 0x5D, 0xA9, 0xA9, 0x5D, 0x57, 0x2B, 0x07,
		        0x06, 0x00, 0x2B, 0x2B, 0x07, 0x2B, 0xD4, 0xA9, 0x2C, 0xAA, 0x5D, 0xAA, 0xAA, 0xAA, 0xD5, 0xA9, 0x5D, 0x5D, 0x5D, 0x5D, 0x5D, 0x5D, 0x57, 0x2B, 0x2B, 0x2B, 0x2B, 0x07, 0x32, 0x5D, 0xB0, 0x5D, 0x5D, 0xB0, 0xAA, 0xAA, 0xAA,
		  0x2B, 0x2B, 0x32, 0x56, 0x32, 0x32, 0x32, 0x32, 0x32, 0x32, 0x32, 0x2C, 0x2B, 0x00, 0x00, 0x00, 0x00, 0x2B, 0x5D, 0x5D, 0x57, 0x57, 0x56, 0x32, 0x2C, 0x2B, 0x56, 0x32, 0x32, 0x32, 0x2C, 0x2C, 0x00, 0x00, 0x00, 0x00, 0x00, 0x00, 0x00, 0x06, 0x00, 0x00,
		        0x5D, 0x5D, 0x5D, 0xA9, 0x5D, 0x57, 0x56, 0x2C, 0x32, 0x32, 0x07, 0x06, 0x06, 0x06, 0x07, 0x06, 0x06, 0x2B, 0x31, 0xA8, 0x56, 0x56, 0xA8, 0xA8, 0x2B, 0x07, 0x07, 0x07, 0x07, 0x2B, 0xB0, 0xB0, 0x5D, 0x5D, 0x5D, 0x5D, 0x5D, 0x5D, 0x56, 0x2B, 0x06,
		        0x07, 0x07, 0x2B, 0x2B, 0x07, 0x00, 0x32, 0x31, 0x2C, 0xAA, 0x5D, 0xAA, 0xAA, 0xAA, 0xD5, 0xAA, 0x5D, 0x5D, 0x5D, 0x5D, 0x5D, 0x57, 0x57, 0x2B, 0x2B, 0x2B, 0x07, 0x07, 0x32, 0x5D, 0xB0, 0x5D, 0x5D, 0xB0, 0xAA, 0xAA, 0xAA,
		  0x2B, 0x2B, 0x32, 0x56, 0x32, 0x32, 0x32, 0x32, 0x32, 0x32, 0x32, 0x2C, 0x07, 0x00, 0x00, 0x00, 0x00, 0x2B, 0x5D, 0x5D, 0x57, 0x57, 0x56, 0x32, 0x32, 0x2C, 0x56, 0x32, 0x32, 0x32, 0x2C, 0x2C, 0x00, 0x00, 0x2B, 0x00, 0x06, 0x06, 0x00, 0x07, 0x00, 0x00,
		        0x57, 0x5D, 0x5D, 0xA9, 0x5D, 0x57, 0x32, 0x2C, 0x32, 0x32, 0x07, 0x07, 0x07, 0x07, 0x06, 0x06, 0x06, 0x00, 0x07, 0x31, 0x56, 0x56, 0x56, 0x2B, 0x07, 0x07, 0x31, 0xA9, 0x2B, 0x2B, 0xB0, 0xB0, 0x5D, 0x5D, 0x5D, 0x5D, 0x5D, 0x5D, 0x32, 0x2C, 0x07,
		        0x00, 0x07, 0x07, 0x00, 0x00, 0x00, 0x00, 0x00, 0x2B, 0xAA, 0x5D, 0xAA, 0xAA, 0xAA, 0xB0, 0xAA, 0x5D, 0x5D, 0x5D, 0x5D, 0x5D, 0x5D, 0x57, 0x2B, 0x2B, 0x2B, 0x06, 0x2B, 0x32, 0x5D, 0xB0, 0x5D, 0x5D, 0xB0, 0xAA, 0xA9, 0xAA,
		  0x2B, 0x2B, 0x32, 0x56, 0x32, 0x32, 0x32, 0x32, 0x32, 0x32, 0x32, 0x2C, 0x07, 0x00, 0x00, 0x00, 0x00, 0x2B, 0x5D, 0x5D, 0x5D, 0x57, 0x56, 0x32, 0x2C, 0x2C, 0x56, 0x32, 0x32, 0x32, 0x2C, 0x2C, 0x00, 0x00, 0x2B, 0x00, 0x00, 0x00, 0x00, 0x00, 0x00, 0x00,
		        0x57, 0x5D, 0x5D, 0xA9, 0x5D, 0x56, 0x32, 0x2C, 0x32, 0x32, 0x56, 0x2B, 0x00, 0x2B, 0x06, 0x06, 0x2B, 0x55, 0x56, 0x56, 0x55, 0x2B, 0x2C, 0x33, 0x2B, 0x2B, 0x5C, 0xD4, 0x56, 0xA9, 0xB0, 0xB0, 0x5D, 0x5D, 0x5D, 0x5D, 0x5D, 0x57, 0x56, 0x2B, 0x00,
		        0x06, 0x00, 0x2B, 0x00, 0x00, 0x00, 0x2B, 0x78, 0x2B, 0xAA, 0x5D, 0xB0, 0xAA, 0xAA, 0xD5, 0xAA, 0x5D, 0x5D, 0x5D, 0x5D, 0x5D, 0x5D, 0x57, 0x01, 0x00, 0x00, 0x00, 0x2B, 0x32, 0x57, 0xB0, 0x5D, 0x5D, 0xB0, 0xAA, 0xA9, 0xAA,
		  0x2B, 0x2B, 0x32, 0x56, 0x32, 0x32, 0x32, 0x32, 0x32, 0x32, 0x32, 0x2C, 0x07, 0x00, 0x00, 0x00, 0x00, 0x2B, 0x5D, 0x5D, 0x5D, 0x57, 0x56, 0x56, 0x32, 0x2C, 0x56, 0x32, 0x32, 0x32, 0x2C, 0x2C, 0x00, 0x00, 0x00, 0x00, 0x00, 0x00, 0x00, 0x00, 0x00, 0x00,
		        0x5D, 0x5D, 0x5D, 0x5D, 0x5D, 0x57, 0x32, 0x2C, 0x32, 0x32, 0x56, 0x2B, 0x2B, 0x2B, 0x2B, 0x2B, 0x2C, 0x57, 0x2B, 0x2B, 0x57, 0x56, 0x2C, 0x56, 0x2B, 0x2C, 0x56, 0xA9, 0xA9, 0x5D, 0xB0, 0xB0, 0x5D, 0x5D, 0x5D, 0xA9, 0x5D, 0x57, 0x56, 0x2B, 0x2B,
		        0x2B, 0x2B, 0x2B, 0x2B, 0x2B, 0x2B, 0x2B, 0x00, 0x32, 0xAA, 0x5D, 0xAA, 0xAA, 0xAA, 0xB0, 0xAA, 0x5D, 0x5D, 0x5D, 0x5D, 0x5D, 0x5D, 0x57, 0x07, 0x01, 0x2B, 0x00, 0x2B, 0x32, 0x5D, 0xB0, 0x5D, 0x5D, 0xB0, 0xAA, 0xA9, 0xAA,
		  0x2B, 0x2B, 0x32, 0x56, 0x32, 0x32, 0x32, 0x32, 0x32, 0x2C, 0x32, 0x2C, 0x07, 0x00, 0x78, 0x00, 0x00, 0x2B, 0x57, 0x5D, 0x5D, 0x57, 0x32, 0x32, 0x2C, 0x2C, 0x56, 0x32, 0x32, 0x32, 0x2C, 0x2C, 0x00, 0x2B, 0x2A, 0x00, 0x2B, 0x7A, 0x2B, 0x2B, 0x00, 0x00,
		        0x5D, 0x5D, 0x5D, 0x5D, 0x5D, 0x56, 0x32, 0x2C, 0x32, 0x32, 0x2B, 0x2B, 0x2B, 0x32, 0x2C, 0x56, 0x56, 0x56, 0x2B, 0x2B, 0x2C, 0x2B, 0x2C, 0x2C, 0x2C, 0x2B, 0x2C, 0x56, 0x2C, 0x2C, 0xB0, 0xB0, 0x5D, 0x57, 0x5D, 0x5D, 0x5D, 0x57, 0x56, 0x2B, 0x2B,
		        0x2B, 0x56, 0x56, 0x56, 0xA8, 0x56, 0x2C, 0x07, 0x56, 0xAA, 0x5D, 0xAA, 0xAA, 0xAA, 0xB0, 0x5D, 0x57, 0x5D, 0x5D, 0x5D, 0x5D, 0x5D, 0x56, 0x2B, 0x7A, 0x2B, 0x01, 0x2C, 0x56, 0x5D, 0xB0, 0x5D, 0x5D, 0xB0, 0xAA, 0xA9, 0xAA,
		  0x2B, 0x2B, 0x32, 0x32, 0x32, 0x32, 0x32, 0x32, 0x32, 0x2C, 0x2C, 0x2C, 0x07, 0x01, 0x01, 0x2B, 0x2B, 0x2B, 0x5D, 0x5D, 0x5D, 0x57, 0x32, 0x32, 0x2C, 0x2B, 0x56, 0x32, 0x32, 0x32, 0x2C, 0x2C, 0x01, 0x2B, 0x2B, 0x2B, 0x2B, 0x2B, 0x2B, 0x2B, 0x7A, 0x01,
		        0x5D, 0x5D, 0x5D, 0x5D, 0x5D, 0x56, 0x2C, 0x2C, 0x32, 0x56, 0xAA, 0xA9, 0xA9, 0xA9, 0xAA, 0xAA, 0xAA, 0x56, 0x2B, 0x2B, 0x2C, 0x2B, 0x55, 0x2B, 0xAA, 0x56, 0x56, 0x57, 0x2B, 0x56, 0xB0, 0xB0, 0x5D, 0x57, 0x5D, 0x5D, 0x5D, 0x57, 0x56, 0x2B, 0x2B,
		        0x2A, 0x2A, 0x2A, 0x2B, 0x2B, 0x2B, 0x2B, 0x2B, 0x56, 0xAA, 0x5D, 0xB0, 0xAA, 0xAA, 0xB0, 0x5D, 0x57, 0x5D, 0x5D, 0x5D, 0x5D, 0x57, 0x56, 0x2B, 0x2B, 0x2B, 0x25, 0x2C, 0x32, 0x5D, 0xAA, 0x5D, 0xA9, 0xB0, 0xAA, 0xAA, 0xA9,
		  0x2B, 0x2B, 0x2C, 0x32, 0x32, 0x32, 0x32, 0x32, 0x32, 0x2C, 0x2C, 0x2B, 0x01, 0x56, 0x32, 0x32, 0x32, 0x56, 0x5D, 0x5D, 0x5D, 0x57, 0x57, 0x57, 0x2C, 0x2B, 0x32, 0x32, 0x32, 0x32, 0x2C, 0x2B, 0x2B, 0x2B, 0x2B, 0x56, 0x56, 0x56, 0x56, 0x56, 0x56, 0x56,
		        0x5D, 0x5D, 0x5D, 0x5D, 0x5D, 0x56, 0x2C, 0x2C, 0x32, 0x32, 0x56, 0x56, 0x56, 0x56, 0x56, 0x56, 0x56, 0x2C, 0x2B, 0x2B, 0x56, 0x55, 0x56, 0x56, 0x56, 0x2B, 0x56, 0x56, 0x2B, 0x56, 0xB0, 0xB0, 0x5D, 0x57, 0x5D, 0x5D, 0x5D, 0x57, 0x56, 0x32, 0x56,
		        0x2B, 0x31, 0x31, 0x55, 0x56, 0x2C, 0x56, 0x56, 0x56, 0xA9, 0x5D, 0xAA, 0xAA, 0xAA, 0xB0, 0x5D, 0x57, 0x5D, 0x57, 0x5D, 0x5D, 0x57, 0x56, 0x2C, 0x56, 0x32, 0x56, 0x56, 0x2C, 0x57, 0xB0, 0x5D, 0xA9, 0xB0, 0xAA, 0x5D, 0xA9,
		  0x2B, 0x2B, 0x2C, 0x32, 0x32, 0x32, 0x32, 0x32, 0x32, 0x2C, 0x2C, 0x2B, 0x00, 0x56, 0x56, 0x56, 0x56, 0x56, 0x5D, 0x5D, 0x5D, 0x57, 0x57, 0x57, 0x2C, 0x2B, 0x56, 0x32, 0x2C, 0x2C, 0x2C, 0x2B, 0x2B, 0x2B, 0x2B, 0x56, 0x56, 0x56, 0x56, 0x56, 0x56, 0x56,
		        0xA9, 0x5D, 0x5D, 0x5D, 0x5D, 0x57, 0x56, 0x2C, 0x32, 0x32, 0x2B, 0x56, 0x56, 0x56, 0x56, 0x56, 0x2B, 0x56, 0x00, 0x2B, 0x56, 0x56, 0x55, 0x4F, 0x56, 0x56, 0x56, 0x56, 0x2B, 0x56, 0xB0, 0xB0, 0x5D, 0x5D, 0x5D, 0x5D, 0x5D, 0x57, 0x56, 0x32, 0x56,
		        0x56, 0x56, 0x56, 0x56, 0x56, 0x56, 0x56, 0x32, 0x32, 0xAA, 0x5D, 0xAA, 0xAA, 0xAA, 0xB0, 0x5D, 0x5D, 0x5D, 0x5D, 0x5D, 0x5D, 0x57, 0x56, 0x2B, 0x2B, 0x2B, 0x2B, 0x2B, 0x2C, 0x56, 0xB0, 0x5D, 0xA9, 0xB0, 0xAA, 0xA9, 0xAA,
		  0x2B, 0x2B, 0x2B, 0x2C, 0x2C, 0x2C, 0x2B, 0x2B, 0x07, 0x2B, 0x07, 0x2B, 0x00, 0x00, 0x00, 0x2B, 0x2B, 0x32, 0x57, 0x57, 0x56, 0x56, 0x32, 0x32, 0x2B, 0x2B, 0x2B, 0x2B, 0x2B, 0x07, 0x07, 0x01, 0x00, 0x00, 0x2B, 0x2B, 0x2B, 0x2B, 0x2B, 0x2B, 0x2B, 0x2B,
		        0x56, 0x56, 0x56, 0x56, 0x56, 0x56, 0x2B, 0x2B, 0x2B, 0x2B, 0x00, 0x2B, 0x2B, 0x2B, 0x2B, 0x2B, 0x2B, 0x2B, 0x2B, 0x2B, 0x2B, 0x2B, 0x2B, 0x2B, 0x2B, 0x2B, 0x2B, 0x2B, 0x2B, 0x2B, 0x5D, 0xA9, 0x56, 0x5D, 0x5D, 0x5D, 0x5D, 0x57, 0x56, 0x2C, 0x2B,
		        0x2B, 0x2B, 0x2B, 0x2B, 0x2B, 0x2B, 0x2B, 0x00, 0x2C, 0x56, 0x57, 0x5D, 0x5D, 0xA9, 0xB0, 0x5D, 0x5D, 0x5D, 0x5D, 0x57, 0x57, 0x57, 0x56, 0x2B, 0x2B, 0x2B, 0x00, 0x2B, 0x2B, 0x32, 0x5D, 0x57, 0x56, 0x5D, 0x5D, 0x5D, 0xA9,
		  0x2B, 0x2B, 0x2B, 0x2B, 0x2B, 0x2B, 0x2B, 0x07, 0x07, 0x07, 0x07, 0x2B, 0x07, 0x2B, 0x2B, 0x2B, 0x2B, 0x56, 0x5D, 0x57, 0x56, 0x56, 0x32, 0x32, 0x2B, 0x2B, 0x2B, 0x2B, 0x2B, 0x07, 0x2B, 0x07, 0x07, 0x2B, 0x2B, 0x2B, 0x2B, 0x7B, 0x2B, 0x2B, 0x2B, 0x2B,
		        0x56, 0x56, 0x56, 0x56, 0x56, 0x56, 0x2C, 0x2B, 0x2B, 0x2B, 0x2B, 0x7A, 0x2B, 0x2B, 0x2B, 0x2B, 0x2B, 0x2B, 0x2B, 0x2B, 0x2B, 0x2B, 0x2C, 0x56, 0x56, 0x56, 0x56, 0x56, 0x56, 0x56, 0x56, 0x56, 0x2B, 0x56, 0x56, 0x56, 0x56, 0x56, 0x32, 0x2C, 0x2B,
		        0x2B, 0x2B, 0x2B, 0x2B, 0x2B, 0x2B, 0x2B, 0x2B, 0x2C, 0x32, 0x57, 0x5D, 0x57, 0x57, 0x5D, 0x56, 0x32, 0x57, 0x56, 0x56, 0x56, 0x32, 0x56, 0x2B, 0x2B, 0x2B, 0x00, 0x2B, 0x2B, 0x32, 0x57, 0x56, 0x2C, 0x5D, 0x5D, 0x5D, 0x57,
		  0x2B, 0x07, 0x2B, 0x2B, 0x2B, 0x2B, 0x2B, 0x2B, 0x2B, 0x2B, 0x2B, 0x32, 0x2B, 0x2B, 0x2B, 0x2B, 0x32, 0x32, 0x56, 0x57, 0x56, 0x56, 0x32, 0x32, 0x2B, 0x2B, 0x2B, 0x2B, 0x2B, 0x2B, 0x2B, 0x2B, 0x2C, 0x32, 0x32, 0x56, 0x56, 0x56, 0x56, 0x32, 0x2B, 0x32,
		        0x56, 0x56, 0x56, 0x32, 0x56, 0x56, 0x32, 0x2B, 0x2B, 0x2B, 0x2B, 0x2B, 0x2C, 0x56, 0x56, 0x56, 0x56, 0x56, 0x56, 0x56, 0x56, 0x56, 0x56, 0x56, 0x56, 0x56, 0x56, 0x56, 0x56, 0x56, 0x56, 0x56, 0x2B, 0x56, 0x56, 0x56, 0x56, 0x56, 0x56, 0x2C, 0x2B,
		        0x2B, 0x2B, 0x2B, 0x32, 0x56, 0x32, 0x56, 0x56, 0x32, 0x32, 0x56, 0x56, 0x56, 0x56, 0x56, 0x2B, 0x2B, 0x56, 0x56, 0x56, 0x32, 0x32, 0x32, 0x2B, 0x2B, 0x55, 0x2B, 0x32, 0x2C, 0x2C, 0x32, 0x32, 0x32, 0x56, 0x56, 0x56, 0x56,
		  0x2B, 0x2B, 0x32, 0x32, 0x32, 0x56, 0x56, 0x56, 0x56, 0x56, 0x32, 0x56, 0x56, 0x56, 0x56, 0x32, 0x56, 0x56, 0x56, 0x56, 0x56, 0x56, 0x56, 0x56, 0x56, 0x56, 0x32, 0x56, 0x56, 0x56, 0x56, 0x56, 0x56, 0x56, 0x56, 0x56, 0x56, 0x56, 0x56, 0x56, 0x56, 0x56,
		        0x56, 0x56, 0x56, 0x56, 0x56, 0x56, 0x56, 0x56, 0x56, 0x56, 0x56, 0x56, 0x56, 0x56, 0x56, 0x56, 0x56, 0x56, 0x56, 0x56, 0x56, 0x56, 0x56, 0x56, 0x56, 0x56, 0x56, 0x56, 0x56, 0x56, 0x56, 0x56, 0x56, 0x56, 0x56, 0x56, 0x56, 0x56, 0x56, 0x56, 0x56,
		        0x56, 0x56, 0x56, 0x56, 0x56, 0x56, 0x56, 0x56, 0x56, 0x56, 0x56, 0x56, 0x56, 0x56, 0x56, 0x56, 0x56, 0x56, 0x56, 0x57, 0x56, 0x56, 0x57, 0x57, 0x56, 0x32, 0x56, 0x56, 0x56, 0x56, 0x56, 0x56, 0x56, 0x56, 0x56, 0x56, 0x56,
		  0x56, 0x56, 0x56, 0x56, 0x56, 0x56, 0x56, 0x56, 0x56, 0x56, 0x56, 0x56, 0x56, 0x56, 0x56, 0x56, 0x56, 0x56, 0x56, 0x56, 0x32, 0x32, 0x56, 0x56, 0x56, 0x56, 0x56, 0x56, 0x56, 0x56, 0x56, 0x56, 0x56, 0x56, 0x56, 0x56, 0x57, 0x57, 0x57, 0x57, 0x57, 0x56,
		        0x56, 0x56, 0x56, 0x56, 0x56, 0x56, 0x56, 0x32, 0x56, 0x56, 0x56, 0x56, 0x56, 0x56, 0x56, 0x56, 0x56, 0x56, 0x56, 0x56, 0x56, 0x56, 0x56, 0x56, 0x56, 0x56, 0x56, 0x56, 0x56, 0x56, 0x56, 0x56, 0x57, 0x57, 0x57, 0x57, 0x57, 0x57, 0x57, 0x56, 0x56,
		        0x56, 0x56, 0x56, 0x56, 0x56, 0x56, 0x56, 0x56, 0x56, 0x56, 0x56, 0x56, 0x56, 0x56, 0x56, 0x56, 0x56, 0x56, 0x56, 0x56, 0x56, 0x56, 0x56, 0x56, 0x56, 0x56, 0x56, 0x56, 0x56, 0x56, 0x56, 0x56, 0x56, 0x56, 0x56, 0x56, 0x56,
		  0x56, 0x56, 0x56, 0x56, 0x56, 0x56, 0x56, 0x56, 0x56, 0x56, 0x56, 0x56, 0x56, 0x56, 0x56, 0x56, 0x56, 0x56, 0x56, 0x56, 0x56, 0x56, 0x56, 0x56, 0x56, 0x56, 0x56, 0x56, 0x56, 0x56, 0x56, 0x56, 0x56, 0x56, 0x56, 0x56, 0x56, 0x56, 0x56, 0x56, 0x56, 0x56,
		        0x56, 0x56, 0x56, 0x56, 0x56, 0x56, 0x56, 0x56, 0x56, 0x56, 0x56, 0x56, 0x56, 0x56, 0x56, 0x56, 0x56, 0x56, 0x56, 0x56, 0x56, 0x56, 0x56, 0x56, 0x56, 0x56, 0x56, 0x56, 0x56, 0x56, 0x56, 0x56, 0x56, 0x56, 0x56, 0x56, 0x56, 0x56, 0x56, 0x56, 0x56,
		        0x56, 0x56, 0x56, 0x56, 0x56, 0x56, 0x56, 0x56, 0x56, 0x56, 0x56, 0x56, 0x56, 0x56, 0x56, 0x56, 0x56, 0x56, 0x56, 0x56, 0x56, 0x56, 0x56, 0x57, 0x57, 0x57, 0x57, 0x56, 0x56, 0x56, 0x56, 0x56, 0x56, 0x56, 0x56, 0x56, 0x56,
		  0x56, 0x56, 0x56, 0x56, 0x56, 0x56, 0x56, 0x56, 0x56, 0x56, 0x56, 0x56, 0x56, 0x56, 0x56, 0x56, 0x56, 0x56, 0x56, 0x56, 0x56, 0x56, 0x56, 0x56, 0x56, 0x56, 0x56, 0x56, 0x56, 0x56, 0x56, 0x56, 0x56, 0x56, 0x56, 0x56, 0x56, 0x56, 0x56, 0x56, 0x56, 0x56,
		        0x56, 0x56, 0x56, 0x56, 0x56, 0x56, 0x56, 0x56, 0x56, 0x56, 0x56, 0x56, 0x56, 0x56, 0x56, 0x56, 0x56, 0x56, 0x56, 0x56, 0x56, 0x56, 0x56, 0x56, 0x56, 0x56, 0x56, 0x56, 0x56, 0x56, 0x56, 0x56, 0x56, 0x56, 0x56, 0x56, 0x56, 0x56, 0x56, 0x56, 0x56,
		        0x56, 0x56, 0x56, 0x56, 0x56, 0x56, 0x56, 0x56, 0x56, 0x56, 0x56, 0x56, 0x56, 0x56, 0x56, 0x56, 0x56, 0x56, 0x56, 0x56, 0x56, 0x56, 0x56, 0x56, 0x56, 0x56, 0x56, 0x56, 0x56, 0x56, 0x56, 0x56, 0x56, 0x56, 0x56, 0x56, 0x56,
		  0x56, 0x56, 0x56, 0x56, 0x56, 0x56, 0x56, 0x56, 0x56, 0x56, 0x56, 0x56, 0x56, 0x56, 0x56, 0x56, 0x56, 0x56, 0x56, 0x56, 0x56, 0x56, 0x56, 0x56, 0x56, 0x56, 0x56, 0x56, 0x56, 0x56, 0x56, 0x56, 0x56, 0x56, 0x56, 0x56, 0x56, 0x56, 0x56, 0x56, 0x56, 0x56,
		        0x56, 0x56, 0x56, 0x56, 0x56, 0x56, 0x56, 0x56, 0x56, 0x56, 0x56, 0x56, 0x56, 0x56, 0x56, 0x56, 0x56, 0x56, 0x56, 0x56, 0x56, 0x56, 0x56, 0x56, 0x56, 0x56, 0x56, 0x56, 0x56, 0x56, 0x56, 0x56, 0x56, 0x56, 0x56, 0x56, 0x56, 0x56, 0x56, 0x56, 0x56,
		        0x56, 0x56, 0x56, 0x56, 0x56, 0x56, 0x56, 0x56, 0x56, 0x56, 0x56, 0x56, 0x56, 0x56, 0x56, 0x56, 0x56, 0x56, 0x56, 0x56, 0x56, 0x56, 0x56, 0x56, 0x56, 0x56, 0x56, 0x56, 0x56, 0x56, 0x56, 0x56, 0x56, 0x56, 0x56, 0x56, 0x56,
		  0x56, 0x56, 0x56, 0x56, 0x56, 0x56, 0x56, 0x56, 0x56, 0x56, 0x56, 0x56, 0x56, 0x56, 0x56, 0x56, 0x56, 0x56, 0x56, 0x56, 0x56, 0x56, 0x56, 0x56, 0x56, 0x56, 0x56, 0x56, 0x56, 0x56, 0x56, 0x56, 0x56, 0x56, 0x56, 0x56, 0x56, 0x56, 0x56, 0x56, 0x56, 0x56,
		        0x56, 0x56, 0x56, 0x56, 0x56, 0x56, 0x56, 0x56, 0x56, 0x56, 0x56, 0x56, 0x56, 0x56, 0x56, 0x56, 0x56, 0x56, 0x56, 0x56, 0x56, 0x56, 0x56, 0x56, 0x56, 0x56, 0x56, 0x56, 0x56, 0x56, 0x56, 0x56, 0x56, 0x56, 0x56, 0x56, 0x56, 0x56, 0x56, 0x56, 0x56,
		        0x56, 0x56, 0x56, 0x56, 0x56, 0x56, 0x56, 0x56, 0x56, 0x56, 0x56, 0x56, 0x56, 0x56, 0x56, 0x56, 0x56, 0x56, 0x56, 0x56, 0x56, 0x56, 0x56, 0x56, 0x56, 0x56, 0x56, 0x56, 0x56, 0x56, 0x56, 0x56, 0x56, 0x56, 0x56, 0x56, 0x56,
		  0x56, 0x56, 0x56, 0x56, 0x56, 0x56, 0x56, 0x56, 0x56, 0x56, 0x56, 0x56, 0x56, 0x56, 0x56, 0x56, 0x56, 0x56, 0x56, 0x56, 0x56, 0x56, 0x56, 0x56, 0x56, 0x56, 0x56, 0x56, 0x56, 0x56, 0x56, 0x56, 0x56, 0x56, 0x56, 0x56, 0x56, 0x56, 0x56, 0x56, 0x56, 0x56,
		        0x56, 0x56, 0x56, 0x56, 0x56, 0x56, 0x56, 0x56, 0x56, 0x56, 0x56, 0x56, 0x56, 0x56, 0x56, 0x56, 0x56, 0x56, 0x56, 0x56, 0x56, 0x56, 0x56, 0x56, 0x56, 0x56, 0x56, 0x56, 0x56, 0x56, 0x56, 0x56, 0x56, 0x56, 0x56, 0x56, 0x56, 0x56, 0x56, 0x56, 0x56,
		        0x56, 0x56, 0x56, 0x56, 0x56, 0x56, 0x56, 0x56, 0x56, 0x56, 0x56, 0x56, 0x56, 0x56, 0x56, 0x56, 0x56, 0x56, 0x56, 0x56, 0x56, 0x56, 0x56, 0x56, 0x56, 0x56, 0x56, 0x56, 0x56, 0x56, 0x56, 0x56, 0x56, 0x56, 0x56, 0x56, 0x56,
		  0x56, 0x56, 0x56, 0x56, 0x56, 0x56, 0x56, 0x56, 0x56, 0x56, 0x56, 0x56, 0x56, 0x56, 0x56, 0x56, 0x56, 0x56, 0x56, 0x56, 0x56, 0x56, 0x56, 0x56, 0x56, 0x56, 0x56, 0x56, 0x56, 0x56, 0x56, 0x56, 0x56, 0x56, 0x56, 0x56, 0x56, 0x56, 0x56, 0x56, 0x56, 0x56,
		        0x56, 0x56, 0x56, 0x56, 0x56, 0x56, 0x56, 0x56, 0x56, 0x56, 0x56, 0x56, 0x56, 0x56, 0x56, 0x56, 0x56, 0x56, 0x56, 0x56, 0x56, 0x56, 0x56, 0x56, 0x56, 0x56, 0x56, 0x56, 0x56, 0x56, 0x56, 0x56, 0x56, 0x56, 0x56, 0x56, 0x56, 0x56, 0x56, 0x56, 0x56,
		        0x56, 0x56, 0x56, 0x56, 0x56, 0x56, 0x56, 0x56, 0x56, 0x56, 0x56, 0x56, 0x56, 0x56, 0x56, 0x56, 0x56, 0x56, 0x56, 0x56, 0x56, 0x56, 0x56, 0x56, 0x56, 0x56, 0x56, 0x56, 0x56, 0x56, 0x56, 0x56, 0x56, 0x56, 0x56, 0x56, 0x56,
		  0x56, 0x56, 0x56, 0x56, 0x56, 0x56, 0x56, 0x56, 0x56, 0x56, 0x56, 0x56, 0x56, 0x56, 0x56, 0x56, 0x56, 0x56, 0x56, 0x56, 0x56, 0x56, 0x56, 0x56, 0x56, 0x56, 0x56, 0x56, 0x56, 0x56, 0x56, 0x56, 0x56, 0x56, 0x56, 0x56, 0x56, 0x56, 0x56, 0x56, 0x56, 0x56,
		        0x56, 0x56, 0x56, 0x56, 0x56, 0x56, 0x56, 0x56, 0x56, 0x56, 0x56, 0x56, 0x56, 0x56, 0x56, 0x56, 0x56, 0x56, 0x56, 0x56, 0x56, 0x56, 0x56, 0x56, 0x56, 0x56, 0x56, 0x56, 0x56, 0x56, 0x56, 0x56, 0x56, 0x56, 0x56, 0x56, 0x56, 0x56, 0x56, 0x56, 0x56,
		        0x56, 0x56, 0x56, 0x56, 0x56, 0x56, 0x56, 0x56, 0x56, 0x56, 0x56, 0x56, 0x56, 0x56, 0x56, 0x56, 0x56, 0x56, 0x56, 0x56, 0x56, 0x56, 0x56, 0x56, 0x56, 0x56, 0x56, 0x56, 0x56, 0x56, 0x56, 0x56, 0x56, 0x56, 0x56, 0x56, 0x56,
		  0x56, 0x56, 0x56, 0x56, 0x56, 0x56, 0x56, 0x56, 0x56, 0x56, 0x56, 0x56, 0x56, 0x56, 0x56, 0x56, 0x56, 0x56, 0x56, 0x56, 0x56, 0x56, 0x56, 0x56, 0x56, 0x56, 0x56, 0x56, 0x56, 0x56, 0x56, 0x56, 0x56, 0x56, 0x56, 0x56, 0x56, 0x56, 0x56, 0x56, 0x56, 0x56,
		        0x56, 0x56, 0x56, 0x56, 0x56, 0x56, 0x56, 0x56, 0x56, 0x56, 0x56, 0x56, 0x56, 0x56, 0x56, 0x56, 0x56, 0x56, 0x56, 0x56, 0x56, 0x56, 0x56, 0x56, 0x56, 0x56, 0x56, 0x56, 0x56, 0x56, 0x56, 0x56, 0x56, 0x56, 0x56, 0x56, 0x56, 0x56, 0x56, 0x56, 0x56,
		        0x56, 0x56, 0x56, 0x56, 0x56, 0x56, 0x56, 0x56, 0x56, 0x56, 0x56, 0x56, 0x56, 0x56, 0x56, 0x56, 0x56, 0x56, 0x56, 0x56, 0x56, 0x56, 0x56, 0x56, 0x56, 0x56, 0x56, 0x56, 0x56, 0x56, 0x56, 0x56, 0x56, 0x56, 0x56, 0x56, 0x56,
		  0x56, 0x56, 0x56, 0x56, 0x56, 0x56, 0x56, 0x56, 0x56, 0x56, 0x56, 0x56, 0x56, 0x56, 0x56, 0x56, 0x56, 0x56, 0x56, 0x56, 0x56, 0x56, 0x56, 0x56, 0x56, 0x56, 0x56, 0x56, 0x56, 0x56, 0x56, 0x56, 0x56, 0x56, 0x56, 0x56, 0x56, 0x56, 0x56, 0x56, 0x56, 0x56,
		        0x56, 0x56, 0x56, 0x56, 0x56, 0x56, 0x56, 0x56, 0x56, 0x56, 0x56, 0x56, 0x56, 0x56, 0x56, 0x56, 0x56, 0x56, 0x56, 0x56, 0x56, 0x56, 0x56, 0x56, 0x56, 0x56, 0x56, 0x56, 0x56, 0x56, 0x56, 0x56, 0x56, 0x56, 0x56, 0x56, 0x56, 0x56, 0x56, 0x56, 0x56,
		        0x56, 0x56, 0x56, 0x56, 0x56, 0x56, 0x56, 0x56, 0x56, 0x56, 0x56, 0x56, 0x56, 0x56, 0x56, 0x56, 0x56, 0x56, 0x56, 0x56, 0x56, 0x56, 0x56, 0x56, 0x56, 0x56, 0x56, 0x56, 0x56, 0x56, 0x56, 0x56, 0x56, 0x56, 0x56, 0x56, 0x56,
		  0x56, 0x56, 0x56, 0x56, 0x56, 0x56, 0x56, 0x56, 0x56, 0x56, 0x56, 0x56, 0x56, 0x56, 0x56, 0x56, 0x56, 0x56, 0x56, 0x56, 0x56, 0x56, 0x56, 0x56, 0x56, 0x56, 0x56, 0x56, 0x56, 0x56, 0x56, 0x56, 0x56, 0x56, 0x56, 0x56, 0x56, 0x56, 0x56, 0x56, 0x56, 0x56,
		        0x56, 0x56, 0x56, 0x56, 0x56, 0x56, 0x56, 0x56, 0x56, 0x56, 0x56, 0x56, 0x56, 0x56, 0x56, 0x56, 0x56, 0x56, 0x56, 0x56, 0x56, 0x56, 0x56, 0x56, 0x56, 0x56, 0x56, 0x56, 0x56, 0x56, 0x56, 0x56, 0x56, 0x56, 0x56, 0x56, 0x56, 0x56, 0x56, 0x56, 0x56,
		        0x56, 0x56, 0x56, 0x56, 0x56, 0x56, 0x56, 0x56, 0x56, 0x56, 0x56, 0x56, 0x56, 0x56, 0x56, 0x56, 0x56, 0x56, 0x56, 0x56, 0x56, 0x56, 0x56, 0x56, 0x56, 0x56, 0x56, 0x56, 0x56, 0x56, 0x56, 0x56, 0x56, 0x56, 0x56, 0x56, 0x56,
		  0x56, 0x56, 0x56, 0x56, 0x56, 0x56, 0x56, 0x56, 0x56, 0x56, 0x56, 0x56, 0x56, 0x56, 0x56, 0x56, 0x56, 0x56, 0x56, 0x56, 0x56, 0x56, 0x56, 0x56, 0x56, 0x56, 0x56, 0x56, 0x56, 0x56, 0x56, 0x56, 0x56, 0x56, 0x56, 0x56, 0x56, 0x56, 0x56, 0x56, 0x56, 0x56,
		        0x56, 0x56, 0x56, 0x56, 0x56, 0x56, 0x56, 0x56, 0x56, 0x56, 0x56, 0x56, 0x56, 0x56, 0x56, 0x56, 0x56, 0x56, 0x56, 0x56, 0x56, 0x56, 0x56, 0x56, 0x56, 0x56, 0x56, 0x56, 0x56, 0x56, 0x56, 0x56, 0x56, 0x56, 0x56, 0x56, 0x56, 0x56, 0x56, 0x56, 0x56,
		        0x56, 0x56, 0x56, 0x56, 0x56, 0x56, 0x56, 0x56, 0x56, 0x56, 0x56, 0x56, 0x56, 0x56, 0x56, 0x56, 0x56, 0x56, 0x56, 0x56, 0x56, 0x56, 0x56, 0x56, 0x56, 0x56, 0x56, 0x56, 0x56, 0x56, 0x56, 0x56, 0x56, 0x56, 0x56, 0x56, 0x56,
		  0x56, 0x56, 0x56, 0x56, 0x56, 0x56, 0x56, 0x56, 0x56, 0x56, 0x56, 0x56, 0x56, 0x56, 0x56, 0x56, 0x56, 0x56, 0x56, 0x56, 0x56, 0x56, 0x56, 0x56, 0x56, 0x56, 0x56, 0x56, 0x56, 0x56, 0x56, 0x56, 0x56, 0x56, 0x56, 0x56, 0x56, 0x56, 0x56, 0x56, 0x56, 0x56,
		        0x56, 0x56, 0x56, 0x56, 0x56, 0x56, 0x56, 0x56, 0x56, 0x56, 0x56, 0x56, 0x56, 0x56, 0x56, 0x56, 0x56, 0x56, 0x56, 0x56, 0x56, 0x56, 0x56, 0x56, 0x56, 0x56, 0x56, 0x56, 0x56, 0x56, 0x56, 0x56, 0x56, 0x56, 0x56, 0x56, 0x56, 0x56, 0x56, 0x56, 0x56,
		        0x56, 0x56, 0x56, 0x56, 0x56, 0x56, 0x56, 0x56, 0x56, 0x56, 0x56, 0x56, 0x56, 0x56, 0x56, 0x56, 0x56, 0x56, 0x56, 0x56, 0x56, 0x56, 0x56, 0x56, 0x56, 0x56, 0x56, 0x56, 0x56, 0x56, 0x56, 0x56, 0x56, 0x56, 0x56, 0x56, 0x56
		};
/* USER CODE END PD */

void SystemClock_Config(void);

int main(void)
{

  /* MCU Configuration--------------------------------------------------------*/

  /* Reset of all peripherals, Initializes the Flash interface and the Systick. */
  HAL_Init();

  /* Configure the system clock */
  SystemClock_Config();

  /* Initialize all configured peripherals */
  MX_GPIO_Init();
  MX_SPI1_Init();
  /* USER CODE BEGIN 2 */

	ST7735_Init(0);
	//fillScreen(BLACK);
	//testAll();
	ST7735_DrawImage(0,0,120,152,_acBrandenburg_gate_cropped_high);
    //ST7735_WriteString(0, 0, "ControllersTech", Font_16x26, YELLOW,BLACK);
	//HAL_Delay(1000);
  /* USER CODE END 2 */

  /* Infinite loop */
  while (1)
  {

    /* USER CODE BEGIN 3 */
	  HAL_GPIO_TogglePin(GPIOB,GPIO_PIN_0);
	  HAL_Delay(100);
  }
  /* USER CODE END 3 */
}

void SystemClock_Config(void)
{
  RCC_OscInitTypeDef RCC_OscInitStruct = {0};
  RCC_ClkInitTypeDef RCC_ClkInitStruct = {0};

  /** Initializes the RCC Oscillators according to the specified parameters
  * in the RCC_OscInitTypeDef structure.
  */
  RCC_OscInitStruct.OscillatorType = RCC_OSCILLATORTYPE_HSI;
  RCC_OscInitStruct.HSIState = RCC_HSI_ON;
  RCC_OscInitStruct.HSICalibrationValue = RCC_HSICALIBRATION_DEFAULT;
  RCC_OscInitStruct.PLL.PLLState = RCC_PLL_NONE;
  if (HAL_RCC_OscConfig(&RCC_OscInitStruct) != HAL_OK)
  {
    Error_Handler();
  }

  /** Initializes the CPU, AHB and APB buses clocks
  */
  RCC_ClkInitStruct.ClockType = RCC_CLOCKTYPE_HCLK|RCC_CLOCKTYPE_SYSCLK
                              |RCC_CLOCKTYPE_PCLK1|RCC_CLOCKTYPE_PCLK2;
  RCC_ClkInitStruct.SYSCLKSource = RCC_SYSCLKSOURCE_HSI;
  RCC_ClkInitStruct.AHBCLKDivider = RCC_SYSCLK_DIV1;
  RCC_ClkInitStruct.APB1CLKDivider = RCC_HCLK_DIV1;
  RCC_ClkInitStruct.APB2CLKDivider = RCC_HCLK_DIV1;

  if (HAL_RCC_ClockConfig(&RCC_ClkInitStruct, FLASH_LATENCY_0) != HAL_OK)
  {
    Error_Handler();
  }
}

void Error_Handler(void)
{
  __disable_irq();
  while (1)
  {
  }
}
